VERSION "dbc-export 1 2025.20.8"

NS_ :

BS_:

BU_: ADSP APB APP APS BB BMS CC CP DAS DI DIF DIR EPAS3P EPAS3S EPBL EPBR GTW HVP ICR IDB PCS PM TCU UI UIS VC VCFRONT VCLEFT VCRIGHT VCSEC

BO_ 322 VCLEFT_liftgateStatus: 8 VCLEFT
 SG_ VCLEFT_liftgateStatusIndex M : 0|2@1+ (1,0) [0|3] "" Vector__XXX
 SG_ VCLEFT_liftgateState m0 : 3|4@1+ (1,0) [0|15] "" Vector__XXX
 SG_ VCLEFT_liftgateStoppingCondition m0 : 10|4@1+ (1,0) [0|15] "" Vector__XXX
 SG_ VCLEFT_liftgateMvmntNotAllowedCo m0 : 14|3@1+ (1,0) [0|7] "" Vector__XXX
 SG_ VCLEFT_liftgatePositionCalibrate m0 : 17|1@1+ (1,0) [0|1] "" Vector__XXX
 SG_ VCLEFT_liftgateUIChimeRequest m0 : 18|3@1+ (1,0) [0|7] "" Vector__XXX
 SG_ VCLEFT_liftgatePhysicalChimeRequ m0 : 21|3@1+ (1,0) [0|7] "" Vector__XXX
 SG_ VCLEFT_liftgateEstimatedStrutTem m0 : 24|8@1+ (1,-60) [-60|195] "C" Vector__XXX
 SG_ VCLEFT_liftgateStaticStrutMode m0 : 32|3@1+ (1,0) [1|7] "" Vector__XXX
 SG_ VCLEFT_liftgateRequestSource m0 : 35|4@1+ (1,0) [0|15] "" Vector__XXX
 SG_ VCLEFT_liftgateNewHeightNudge m0 : 39|1@1+ (1,0) [0|1] "" Vector__XXX
 SG_ VCLEFT_liftgateNewSaveHeight m0 : 40|8@1+ (1,0) [0|255] "cm" Vector__XXX
 SG_ VCLEFT_liftgateGeofenceState m0 : 48|2@1+ (1,0) [0|3] "" Vector__XXX
 SG_ VCLEFT_liftgateAboveCrossoverAng m0 : 59|1@1+ (1,0) [0|1] "" Vector__XXX
 SG_ VCLEFT_liftgateLatchRequest m0 : 61|3@1+ (1,0) [0|7] "" Vector__XXX
 SG_ VCLEFT_liftgateStrutDutyCycle m1 : 3|8@1- (1,0) [-100|100] "%" Vector__XXX
 SG_ VCLEFT_liftgateStrutCurrent m1 : 11|10@1- (0.1,0) [-30|30] "A" Vector__XXX
 SG_ VCLEFT_liftgatePosition m1 : 21|7@1- (1,46) [-5|95] "deg" Vector__XXX
 SG_ VCLEFT_liftgateSpeed m1 : 28|10@1- (0.1,0) [-30|30] "deg/s" Vector__XXX
 SG_ VCLEFT_liftgateHeight m1 : 38|8@1+ (1,0) [0|255] "cm" Vector__XXX
 SG_ VCLEFT_liftgatePositionDiff m1 : 46|6@1- (1,0) [-30|30] "deg" Vector__XXX

BO_ 994 VCLEFT_lightStatus: 7 VCLEFT
 SG_ VCLEFT_brakeLightStatus : 0|2@1+ (1,0) [0|2] "" Vector__XXX
 SG_ VCLEFT_tailLightStatus : 2|2@1+ (1,0) [0|2] "" Vector__XXX
 SG_ VCLEFT_turnSignalStatus : 4|2@1+ (1,0) [0|2] "" Vector__XXX
 SG_ VCLEFT_FLMapLightStatus : 6|2@1+ (1,0) [0|2] "" Vector__XXX
 SG_ VCLEFT_FRMapLightStatus : 8|2@1+ (1,0) [0|2] "" Vector__XXX
 SG_ VCLEFT_RLMapLightStatus : 10|2@1+ (1,0) [0|2] "" Vector__XXX
 SG_ VCLEFT_RRMapLightStatus : 12|2@1+ (1,0) [0|2] "" Vector__XXX
 SG_ VCLEFT_FLMapLightSwitchPressed : 14|1@1+ (1,0) [0|1] "" Vector__XXX
 SG_ VCLEFT_FRMapLightSwitchPressed : 15|1@1+ (1,0) [0|1] "" Vector__XXX
 SG_ VCLEFT_RLMapLightSwitchPressed : 16|1@1+ (1,0) [0|1] "" Vector__XXX
 SG_ VCLEFT_RRMapLightSwitchPressed : 17|1@1+ (1,0) [0|1] "" Vector__XXX
 SG_ VCLEFT_leftTurnTrailerLightStatu : 18|2@1+ (1,0) [0|2] "" Vector__XXX
 SG_ VCLEFT_rightTrnTrailerLightStatu : 20|2@1+ (1,0) [0|2] "" Vector__XXX
 SG_ VCLEFT_brakeTrailerLightStatus : 22|2@1+ (1,0) [0|2] "" Vector__XXX
 SG_ VCLEFT_tailTrailerLightStatus : 24|2@1+ (1,0) [0|2] "" Vector__XXX
 SG_ VCLEFT_fogTrailerLightStatus : 26|2@1+ (1,0) [0|2] "" Vector__XXX
 SG_ VCLEFT_frontRideHeight : 28|8@1- (1,0) [-127|127] "mm" Vector__XXX
 SG_ VCLEFT_rearRideHeight : 36|8@1- (1,0) [-127|127] "mm" Vector__XXX
 SG_ VCLEFT_trailerDetected : 46|2@1+ (1,0) [1|3] "" Vector__XXX
 SG_ VCLEFT_rideHeightSensorFault : 48|1@1+ (1,0) [0|1] "" Vector__XXX
 SG_ VCLEFT_reverseTrailerLightStatus : 49|2@1+ (1,0) [0|2] "" Vector__XXX
 SG_ VCLEFT_tailLightOutageStatus : 51|1@1+ (1,0) [0|1] "" Vector__XXX
 SG_ VCLEFT_reverseLightStatus : 52|2@1+ (1,0) [0|2] "" Vector__XXX

BO_ 1802 VCLEFT_logging0point1Hz: 6 VCLEFT
 SG_ VCLEFT_logging0point1HzIndex M : 0|1@1+ (1,0) [0|1] "" Vector__XXX
 SG_ VCLEFT_leftBrakeTailLightCurrent m0 : 2|9@1+ (0.005,0) [0|2.55] "A" Vector__XXX
 SG_ VCLEFT_leftBrakeTailLightCu_0001 m0 : 11|3@1+ (1,0) [1|7] "" Vector__XXX
 SG_ VCLEFT_leftRearTurnLightCurrent m0 : 14|9@1+ (0.002,0) [0|1.02] "A" Vector__XXX
 SG_ VCLEFT_leftRearTurnLightCurrentS m0 : 24|3@1+ (1,0) [1|7] "" Vector__XXX

BO_ 936 VCLEFT_logging1Hz: 8 VCLEFT
 SG_ VCLEFT_logging1HzIndex M : 0|2@1+ (1,0) [0|3] "" Vector__XXX
 SG_ VCLEFT_tohcPCBATemperature m0 : 8|8@1+ (1,-40) [-40|214] "degC" Vector__XXX
 SG_ VCLEFT_phoneChargingFL m0 : 16|1@1+ (1,0) [0|1] "" Vector__XXX
 SG_ VCLEFT_phoneChargingFR m0 : 17|1@1+ (1,0) [0|1] "" Vector__XXX
 SG_ VCLEFT_swcResistance m0 : 24|7@1+ (0.025,0) [0|3.15] "Ohm" Vector__XXX
 SG_ VCLEFT_frontSeatHeatCushionPwr m0 : 32|7@1+ (1,0) [0|127] "W" Vector__XXX
 SG_ VCLEFT_frontSeatHeatBackrestPwr m0 : 40|7@1+ (1,0) [0|127] "W" Vector__XXX

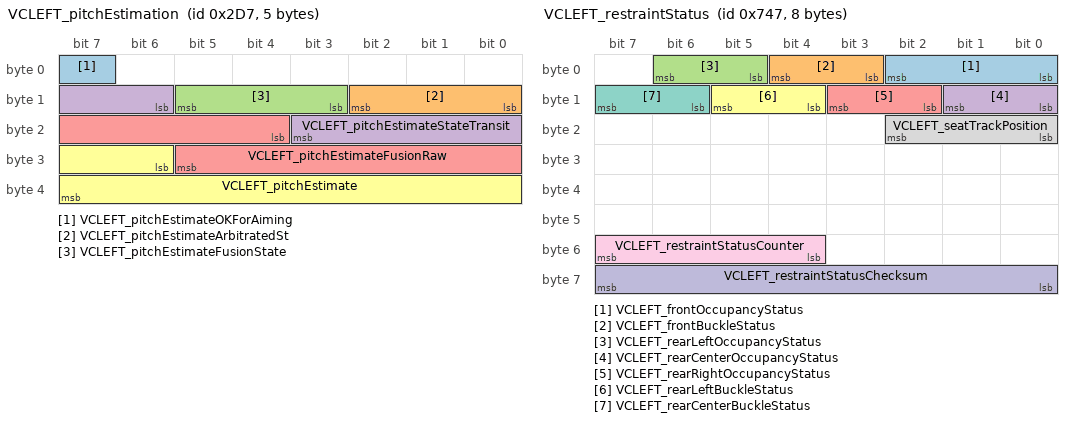
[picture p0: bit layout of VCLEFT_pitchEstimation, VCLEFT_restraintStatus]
BO_ 727 VCLEFT_pitchEstimation: 5 VCLEFT
 SG_ VCLEFT_pitchEstimateOKForAiming : 7|1@1+ (1,0) [0|1] "" Vector__XXX
 SG_ VCLEFT_pitchEstimateArbitratedSt : 8|3@1+ (1,0) [0|7] "" Vector__XXX
 SG_ VCLEFT_pitchEstimateFusionState : 11|3@1+ (1,0) [0|7] "" Vector__XXX
 SG_ VCLEFT_pitchEstimateStateTransit : 14|6@1+ (1,0) [0|63] "" Vector__XXX
 SG_ VCLEFT_pitchEstimateFusionRaw : 20|10@1- (0.0002,0) [-0.1024|0.1022] "rad" Vector__XXX
 SG_ VCLEFT_pitchEstimate : 30|10@1- (0.0002,0) [-0.1022|0.1022] "rad" Vector__XXX

BO_ 1863 VCLEFT_restraintStatus: 8 VCLEFT
 SG_ VCLEFT_frontOccupancyStatus : 0|3@1+ (1,0) [0|6] "" Vector__XXX
 SG_ VCLEFT_frontBuckleStatus : 3|2@1+ (1,0) [0|2] "" Vector__XXX
 SG_ VCLEFT_rearLeftOccupancyStatus : 5|2@1+ (1,0) [0|2] "" Vector__XXX
 SG_ VCLEFT_rearCenterOccupancyStatus : 8|2@1+ (1,0) [0|2] "" Vector__XXX
 SG_ VCLEFT_rearRightOccupancyStatus : 10|2@1+ (1,0) [0|2] "" Vector__XXX
 SG_ VCLEFT_rearLeftBuckleStatus : 12|2@1+ (1,0) [0|2] "" Vector__XXX
 SG_ VCLEFT_rearCenterBuckleStatus : 14|2@1+ (1,0) [0|2] "" Vector__XXX
 SG_ VCLEFT_seatTrackPosition : 16|3@1+ (1,0) [0|6] "" Vector__XXX
 SG_ VCLEFT_restraintStatusCounter : 52|4@1+ (1,0) [0|15] "" Vector__XXX
 SG_ VCLEFT_restraintStatusChecksum : 56|8@1+ (1,0) [0|255] "" Vector__XXX

BO_ 1250 VCLEFT_seatStatus: 8 VCLEFT
 SG_ VCLEFT_seatStatusIndex M : 0|3@1+ (1,0) [0|7] "" Vector__XXX
 SG_ VCLEFT_frontSeatTrackPos m0 : 8|16@1- (1,0) [-32768|32767] "" Vector__XXX
 SG_ VCLEFT_frontSeatTrackCurrent m0 : 24|12@1- (0.01,0) [-20.48|20.47] "A" Vector__XXX
 SG_ VCLEFT_frontSeatTrackDuty m0 : 36|12@1- (0.1,0) [-204.8|204.7] "%" Vector__XXX
 SG_ VCLEFT_frontSeatTrackState m0 : 48|3@1+ (1,0) [0|7] "" Vector__XXX
 SG_ VCLEFT_frontSeatTrackCalibrated m0 : 51|1@1+ (1,0) [0|1] "" Vector__XXX
 SG_ VCLEFT_frontSeatTrackLog m0 : 52|1@1+ (1,0) [0|1] "" Vector__XXX
 SG_ VCLEFT_frontSeatTrackBridgeSt m0 : 53|2@1+ (1,0) [0|3] "" Vector__XXX
 SG_ VCLEFT_frontSeatBackPos m1 : 8|16@1- (1,0) [-32768|32767] "" Vector__XXX
 SG_ VCLEFT_frontSeatBackCurrent m1 : 24|12@1- (0.01,0) [-20.48|20.47] "A" Vector__XXX
 SG_ VCLEFT_frontSeatBackDuty m1 : 36|12@1- (0.1,0) [-204.8|204.7] "%" Vector__XXX
 SG_ VCLEFT_frontSeatBackState m1 : 48|3@1+ (1,0) [0|7] "" Vector__XXX
 SG_ VCLEFT_frontSeatBackCalibrated m1 : 51|1@1+ (1,0) [0|1] "" Vector__XXX
 SG_ VCLEFT_frontSeatBackLog m1 : 52|1@1+ (1,0) [0|1] "" Vector__XXX
 SG_ VCLEFT_frontSeatBackBridgeSt m1 : 53|2@1+ (1,0) [0|3] "" Vector__XXX
 SG_ VCLEFT_frontSeatLiftPos m2 : 8|16@1- (1,0) [-32768|32767] "" Vector__XXX
 SG_ VCLEFT_frontSeatLiftCurrent m2 : 24|12@1- (0.01,0) [-20.48|20.47] "A" Vector__XXX
 SG_ VCLEFT_frontSeatLiftDuty m2 : 36|12@1- (0.1,0) [-204.8|204.7] "%" Vector__XXX
 SG_ VCLEFT_frontSeatLiftState m2 : 48|3@1+ (1,0) [0|7] "" Vector__XXX
 SG_ VCLEFT_frontSeatLiftCalibrated m2 : 51|1@1+ (1,0) [0|1] "" Vector__XXX
 SG_ VCLEFT_frontSeatLiftLog m2 : 52|1@1+ (1,0) [0|1] "" Vector__XXX
 SG_ VCLEFT_frontSeatLiftBridgeSt m2 : 53|2@1+ (1,0) [0|3] "" Vector__XXX
 SG_ VCLEFT_frontSeatTiltPos m3 : 8|16@1- (1,0) [-32768|32767] "" Vector__XXX
 SG_ VCLEFT_frontSeatTiltCurrent m3 : 24|12@1- (0.01,0) [-20.48|20.47] "A" Vector__XXX
 SG_ VCLEFT_frontSeatTiltDuty m3 : 36|12@1- (0.1,0) [-204.8|204.7] "%" Vector__XXX
 SG_ VCLEFT_frontSeatTiltState m3 : 48|3@1+ (1,0) [0|7] "" Vector__XXX
 SG_ VCLEFT_frontSeatTiltCalibrated m3 : 51|1@1+ (1,0) [0|1] "" Vector__XXX
 SG_ VCLEFT_frontSeatTiltLog m3 : 52|1@1+ (1,0) [0|1] "" Vector__XXX
 SG_ VCLEFT_frontSeatTiltBridgeSt m3 : 53|2@1+ (1,0) [0|3] "" Vector__XXX
 SG_ VCLEFT_lumbarAState m4 : 3|3@1+ (1,0) [0|7] "" Vector__XXX
 SG_ VCLEFT_lumbarBState m4 : 6|3@1+ (1,0) [0|7] "" Vector__XXX
 SG_ VCLEFT_lumbarAPressureHpa m4 : 9|12@1+ (1,0) [0|4095] "" Vector__XXX
 SG_ VCLEFT_lumbarAPressureHpaFilt m4 : 21|10@1+ (1,0) [0|1023] "" Vector__XXX
 SG_ VCLEFT_lumbarBPressureHpa m4 : 31|12@1+ (1,0) [0|4095] "" Vector__XXX
 SG_ VCLEFT_lumbarBPressureHpaFilt m4 : 43|10@1+ (1,0) [0|1023] "" Vector__XXX
 SG_ VCLEFT_lumbarActiveTooLongErr m4 : 53|1@1+ (1,0) [0|1] "" Vector__XXX
 SG_ VCLEFT_lumbarMaxPErr m4 : 54|1@1+ (1,0) [0|1] "" Vector__XXX
 SG_ VCLEFT_lumbarOvercurrentErr m4 : 55|1@1+ (1,0) [0|1] "" Vector__XXX
 SG_ VCLEFT_lumbarMaxOperatingPErr m4 : 56|1@1+ (1,0) [0|1] "" Vector__XXX
 SG_ VCLEFT_lumbarMinPErr m4 : 57|1@1+ (1,0) [0|1] "" Vector__XXX
 SG_ VCLEFT_lumbarGeneralErr m4 : 58|1@1+ (1,0) [0|1] "" Vector__XXX
 SG_ VCLEFT_lumbarDevMaxPumpPressA m4 : 59|1@1+ (1,0) [0|1] "" Vector__XXX
 SG_ VCLEFT_lumbarDevMaxPumpPressB m4 : 60|1@1+ (1,0) [0|1] "" Vector__XXX
 SG_ VCLEFT_frontSeatTrackPosReal m5 : 3|12@1- (1,0) [-2048|2047] "mm" Vector__XXX
 SG_ VCLEFT_frontSeatBackPosReal m5 : 16|12@1- (0.1,0) [-204.8|204.7] "deg" Vector__XXX
 SG_ VCLEFT_frontSeatLiftPosReal m5 : 28|12@1- (1,0) [-2048|2047] "mm" Vector__XXX
 SG_ VCLEFT_frontSeatTiltPosReal m5 : 40|12@1- (0.1,0) [-204.8|204.7] "deg" Vector__XXX
 SG_ VCLEFT_frontSeatTrackPosOffset m6 : 3|12@1- (1,0) [-2048|2047] "mm" Vector__XXX
 SG_ VCLEFT_frontSeatBackPosOffset m6 : 16|12@1- (0.1,0) [-204.8|204.7] "deg" Vector__XXX
 SG_ VCLEFT_frontSeatLiftPosOffset m6 : 28|12@1- (1,0) [-2048|2047] "mm" Vector__XXX
 SG_ VCLEFT_frontSeatTiltPosOffset m6 : 40|12@1- (0.1,0) [-204.8|204.7] "deg" Vector__XXX

BO_ 738 VCLEFT_seatStatus2: 8 VCLEFT
 SG_ VCLEFT_seatStatus2Index M : 0|4@1+ (1,0) [0|15] "" Vector__XXX
 SG_ VCLEFT_frontSeatHeatCurrent m0 : 4|12@1+ (0.01,0) [0|40.95] "A" Vector__XXX
 SG_ VCLEFT_frontSeatHeatDuty m0 : 16|8@1+ (1,0) [0|255] "%" Vector__XXX
 SG_ VCLEFT_frontSeatHeatTmp m0 : 24|12@1- (0.05,0) [-40|80] "degC" Vector__XXX
 SG_ VCLEFT_frontSeatHeatTmpTarget m0 : 36|8@1- (0.5,0) [0|60] "degC" Vector__XXX
 SG_ VCLEFT_frontSeatHeatInhibited m0 : 44|1@1+ (1,0) [0|1] "" Vector__XXX
 SG_ VCLEFT_frontSeatHeatPowered m0 : 45|1@1+ (1,0) [0|1] "" Vector__XXX
 SG_ VCLEFT_2RowSeatReclineState m11 : 4|4@1+ (1,0) [0|14] "" Vector__XXX
 SG_ VCLEFT_2RowSeatReclineDuty m11 : 8|8@1- (1,0) [-100|100] "%" Vector__XXX
 SG_ VCLEFT_2RowSeatReclineCurrent m11 : 16|12@1- (0.05,0) [-100|100] "A" Vector__XXX
 SG_ VCLEFT_2RowSeatReclineCalibrated m11 : 28|1@1+ (1,0) [0|1] "" Vector__XXX
 SG_ VCLEFT_2RowSeatReclinePositionRa m11 : 29|12@1- (1,0) [-2048|2047] "" Vector__XXX
 SG_ VCLEFT_2RowSeatReclineAngle m11 : 41|12@1- (0.1,0) [-204.8|204.7] "deg" Vector__XXX
 SG_ VCLEFT_2RowSeatReclineAbsPosSwit m11 : 53|2@1+ (1,0) [1|3] "" Vector__XXX
 SG_ VCLEFT_2RowSeatReclinePositionSt m12 : 4|3@1+ (1,0) [0|7] "" Vector__XXX
 SG_ VCLEFT_2RowSeatReclineAdjustment m12 : 7|1@1+ (1,0) [0|1] "" Vector__XXX
 SG_ VCLEFT_2RowSeatReclineFoldAllowe m12 : 8|1@1+ (1,0) [0|1] "" Vector__XXX
 SG_ VCLEFT_2RowSeatReclineUnfoldAllo m12 : 9|1@1+ (1,0) [0|1] "" Vector__XXX
 SG_ VCLEFT_2RowSeatReclineNextToggle m12 : 10|2@1+ (1,0) [0|3] "" Vector__XXX
 SG_ VCLEFT_2RowSeatReclineChoreoBloc m12 : 12|1@1+ (1,0) [0|1] "" Vector__XXX
 SG_ VCLEFT_2RowSeat1RClashAvoidanceB m12 : 13|3@1+ (1,0) [0|7] "" Vector__XXX
 SG_ VCLEFT_2RowSeat1RClashAvoidanceS m12 : 16|2@1+ (1,0) [0|3] "" Vector__XXX
 SG_ VCLEFT_2RowSeatReclineAbsPo_0001 m12 : 18|12@1- (0.1,0) [-204.8|204.7] "deg" Vector__XXX

BO_ 930 VCLEFT_status: 8 VCLEFT
 SG_ VCLEFT_statusIndex M : 0|2@1+ (1,0) [0|3] "" Vector__XXX
 SG_ VCLEFT_securityControllerEnable m0 : 5|1@1+ (1,0) [0|1] "" Vector__XXX
 SG_ VCLEFT_securityControllerVoltage m0 : 6|5@1+ (0.625,0) [0|19.375] "V" Vector__XXX
 SG_ VCLEFT_consoleDoorAssist m0 : 11|1@1+ (1,0) [0|1] "" Vector__XXX
 SG_ VCLEFT_OTAState m0 : 12|1@1+ (1,0) [0|1] "" Vector__XXX
 SG_ VCLEFT_5AVoltage m0 : 13|10@1+ (0.005443676,0) [0|5.568880548] "V" Vector__XXX
 SG_ VCLEFT_vbatProt m0 : 23|12@1+ (0.005443676,0) [0|22.29185322] "V" Vector__XXX
 SG_ VCLEFT_footwellLightCurrent m0 : 35|12@1- (0.1,0) [-204.8|204.7] "mA" Vector__XXX
 SG_ VCLEFT_swcInputVoltage m0 : 47|8@1+ (0.1,0) [0|25.4] "V" Vector__XXX
 SG_ VCLEFT_swcPCBATemperature m0 : 55|8@1- (1,68) [-59|195] "degC" Vector__XXX
 SG_ VCLEFT_obdEthernetActive m0 : 63|1@1+ (1,0) [0|1] "" Vector__XXX
 SG_ VCLEFT_rationalityAggregateCurre m1 : 12|8@1+ (0.5,0) [0|127.5] "A" Vector__XXX
 SG_ VCLEFT_LVBatteryTypeDBG m1 : 20|3@1+ (1,0) [0|7] "" Vector__XXX
 SG_ VCLEFT_DIeFuseFault m1 : 24|1@1+ (1,0) [0|1] "" Vector__XXX
 SG_ VCLEFT_eFuseMgmtVoltageMonitor m1 : 25|7@1+ (0.125,0) [0|15.875] "V" Vector__XXX
 SG_ VCLEFT_trailerAuxCurrent m1 : 32|12@1+ (0.025,0) [0|102.35] "A" Vector__XXX
 SG_ VCLEFT_swcHeatTmp m1 : 44|10@1+ (0.1,-35) [-35|65] "degC" Vector__XXX
 SG_ VCLEFT_swcHeatStatus m1 : 54|3@1+ (1,0) [1|7] "" Vector__XXX
 SG_ VCLEFT_swcHeatInhibited m1 : 57|1@1+ (1,0) [0|1] "" Vector__XXX
 SG_ VCLEFT_pcbaTemperature m2 : 4|11@1+ (0.125,-40) [-40|150] "degC" Vector__XXX
 SG_ VCLEFT_swcHeatPwr m2 : 15|9@1+ (0.5,0) [0|254] "W" Vector__XXX
 SG_ VCLEFT_swcHeatDutyCycle m2 : 24|7@1+ (1,0) [0|100] "%" Vector__XXX
 SG_ VCLEFT_DIeFuseCurrent m2 : 31|6@1+ (0.1,0) [0|6.3] "A" Vector__XXX
 SG_ VCLEFT_SWCpresent m2 : 37|1@1+ (1,0) [0|1] "" Vector__XXX

BO_ 962 VCLEFT_switchStatus: 8 VCLEFT
 SG_ VCLEFT_switchStatusIndex M : 0|1@1+ (1,0) [0|1] "" Vector__XXX
 SG_ VCLEFT_hornSwitchPressed m0 : 2|1@1+ (1,0) [0|1] "" Vector__XXX
 SG_ VCLEFT_hazardButtonPressed m0 : 3|1@1+ (1,0) [0|1] "" Vector__XXX
 SG_ VCLEFT_brakeSwitchPressed m0 : 4|1@1+ (1,0) [0|1] "" Vector__XXX
 SG_ VCLEFT_rightMirrorTilt m0 : 5|3@1+ (1,0) [0|7] "" Vector__XXX
 SG_ VCLEFT_frontSeatTrackBack m0 : 8|2@1+ (1,0) [1|3] "" Vector__XXX
 SG_ VCLEFT_frontSeatTrackForward m0 : 10|2@1+ (1,0) [1|3] "" Vector__XXX
 SG_ VCLEFT_frontSeatTiltDown m0 : 12|2@1+ (1,0) [1|3] "" Vector__XXX
 SG_ VCLEFT_frontSeatTiltUp m0 : 14|2@1+ (1,0) [1|3] "" Vector__XXX
 SG_ VCLEFT_frontSeatLiftDown m0 : 16|2@1+ (1,0) [1|3] "" Vector__XXX
 SG_ VCLEFT_frontSeatLiftUp m0 : 18|2@1+ (1,0) [1|3] "" Vector__XXX
 SG_ VCLEFT_frontSeatBackrestBack m0 : 20|2@1+ (1,0) [1|3] "" Vector__XXX
 SG_ VCLEFT_frontSeatBackrestForward m0 : 22|2@1+ (1,0) [1|3] "" Vector__XXX
 SG_ VCLEFT_frontSeatLumbarDown m0 : 24|2@1+ (1,0) [1|3] "" Vector__XXX
 SG_ VCLEFT_frontSeatLumbarUp m0 : 26|2@1+ (1,0) [1|3] "" Vector__XXX
 SG_ VCLEFT_frontSeatLumbarIn m0 : 28|2@1+ (1,0) [1|3] "" Vector__XXX
 SG_ VCLEFT_frontSeatLumbarOut m0 : 30|2@1+ (1,0) [1|3] "" Vector__XXX
 SG_ VCLEFT_btnWindowSwPackUpLF m0 : 32|1@1+ (1,0) [0|1] "" Vector__XXX
 SG_ VCLEFT_btnWindowSwPackAutoUpLF m0 : 33|1@1+ (1,0) [0|1] "" Vector__XXX
 SG_ VCLEFT_btnWindowSwPackDownLF m0 : 34|1@1+ (1,0) [0|1] "" Vector__XXX
 SG_ VCLEFT_btnWindowSwPackAutoDownLF m0 : 35|1@1+ (1,0) [0|1] "" Vector__XXX
 SG_ VCLEFT_btnWindowSwPackUpLR m0 : 36|1@1+ (1,0) [0|1] "" Vector__XXX
 SG_ VCLEFT_btnWindowSwPackAutoUpLR m0 : 37|1@1+ (1,0) [0|1] "" Vector__XXX
 SG_ VCLEFT_btnWindowSwPackDownLR m0 : 38|1@1+ (1,0) [0|1] "" Vector__XXX
 SG_ VCLEFT_btnWindowSwPackAutoDownLR m0 : 39|1@1+ (1,0) [0|1] "" Vector__XXX
 SG_ VCLEFT_btnWindowSwPackUpRF m0 : 40|1@1+ (1,0) [0|1] "" Vector__XXX
 SG_ VCLEFT_btnWindowSwPackAutoUpRF m0 : 41|1@1+ (1,0) [0|1] "" Vector__XXX
 SG_ VCLEFT_btnWindowSwPackDownRF m0 : 42|1@1+ (1,0) [0|1] "" Vector__XXX
 SG_ VCLEFT_btnWindowSwPackAutoDownRF m0 : 43|1@1+ (1,0) [0|1] "" Vector__XXX
 SG_ VCLEFT_btnWindowSwPackUpRR m0 : 44|1@1+ (1,0) [0|1] "" Vector__XXX
 SG_ VCLEFT_btnWindowSwPackAutoUpRR m0 : 45|1@1+ (1,0) [0|1] "" Vector__XXX
 SG_ VCLEFT_btnWindowSwPackDownRR m0 : 46|1@1+ (1,0) [0|1] "" Vector__XXX
 SG_ VCLEFT_btnWindowSwPackAutoDownRR m0 : 47|1@1+ (1,0) [0|1] "" Vector__XXX
 SG_ VCLEFT_frontBuckleSwitch m0 : 48|2@1+ (1,0) [1|3] "" Vector__XXX
 SG_ VCLEFT_frontOccupancySwitch m0 : 50|2@1+ (1,0) [1|3] "" Vector__XXX
 SG_ VCLEFT_rearLeftBuckleSwitch m0 : 52|2@1+ (1,0) [1|3] "" Vector__XXX
 SG_ VCLEFT_rearCenterOccupancySwitch m0 : 54|2@1+ (1,0) [1|3] "" Vector__XXX
 SG_ VCLEFT_rearLeftOccupancySwitch m0 : 56|2@1+ (1,0) [1|3] "" Vector__XXX
 SG_ VCLEFT_rearRightOccupancySwitch m0 : 58|2@1+ (1,0) [1|3] "" Vector__XXX
 SG_ VCLEFT_brakePressed m0 : 60|1@1+ (1,0) [0|1] "" Vector__XXX
 SG_ VCLEFT_rearHVACButtonPressed m0 : 61|1@1+ (1,0) [0|1] "" Vector__XXX
 SG_ VCLEFT_rearCenterBuckleSwitch m0 : 62|2@1+ (1,0) [1|3] "" Vector__XXX
 SG_ VCLEFT_isAlcoholInterlockSet m1 : 2|1@1+ (1,0) [0|1] "" Vector__XXX
 SG_ VCLEFT_swcLeftTiltRight m1 : 3|2@1+ (1,0) [1|3] "" Vector__XXX
 SG_ VCLEFT_swcLeftPressed m1 : 5|2@1+ (1,0) [1|3] "" Vector__XXX
 SG_ VCLEFT_swcRightTiltLeft m1 : 8|2@1+ (1,0) [1|3] "" Vector__XXX
 SG_ VCLEFT_swcRightTiltRight m1 : 10|2@1+ (1,0) [1|3] "" Vector__XXX
 SG_ VCLEFT_swcRightPressed m1 : 12|2@1+ (1,0) [1|3] "" Vector__XXX
 SG_ VCLEFT_swcLeftTiltLeft m1 : 14|2@1+ (1,0) [1|3] "" Vector__XXX
 SG_ VCLEFT_swcLeftScrollTicks m1 : 16|6@1- (1,0) [-32|31] "" Vector__XXX
 SG_ VCLEFT_swcWiperButtonState m1 : 22|2@1+ (1,0) [0|3] "" Vector__XXX
 SG_ VCLEFT_swcRightScrollTicks m1 : 24|6@1- (1,0) [-32|31] "" Vector__XXX
 SG_ VCLEFT_swcTurnSignalLeftButtonSt m1 : 30|2@1+ (1,0) [0|3] "" Vector__XXX
 SG_ VCLEFT_btnWindowUpLR m1 : 32|1@1+ (1,0) [0|1] "" Vector__XXX
 SG_ VCLEFT_btnWindowAutoUpLR m1 : 33|1@1+ (1,0) [0|1] "" Vector__XXX
 SG_ VCLEFT_btnWindowDownLR m1 : 34|1@1+ (1,0) [0|1] "" Vector__XXX
 SG_ VCLEFT_btnWindowAutoDownLR m1 : 35|1@1+ (1,0) [0|1] "" Vector__XXX
 SG_ VCLEFT_2RowSeatLeftFoldFlatSwitc m1 : 38|1@1+ (1,0) [0|1] "" Vector__XXX
 SG_ VCLEFT_2RowSeatRightFoldFlatSwit m1 : 39|1@1+ (1,0) [0|1] "" Vector__XXX
 SG_ VCLEFT_2RowSeatBothFoldFlatSwitc m1 : 40|1@1+ (1,0) [0|1] "" Vector__XXX
 SG_ VCLEFT_swcLeftDoublePress m1 : 41|1@1+ (1,0) [0|1] "" Vector__XXX
 SG_ VCLEFT_swcRightDoublePress m1 : 42|1@1+ (1,0) [0|1] "" Vector__XXX
 SG_ VCLEFT_swcTurnSignalRightButtonS m1 : 44|2@1+ (1,0) [0|3] "" Vector__XXX
 SG_ VCLEFT_swcHighBeamButtonState m1 : 46|2@1+ (1,0) [0|3] "" Vector__XXX
 SG_ VCLEFT_swcVoiceControlPress m1 : 48|2@1+ (1,0) [1|3] "" Vector__XXX
 SG_ VCLEFT_swcCameraButtonState m1 : 50|2@1+ (1,0) [0|3] "" Vector__XXX
 SG_ VCLEFT_swcRightPressedQF m1 : 52|1@1+ (1,0) [0|1] "" Vector__XXX
 SG_ VCLEFT_frontSeatResistiveOccupan m1 : 62|2@1+ (1,0) [1|3] "" Vector__XXX

BO_ 656 VCLEFT_thermalLogging10Hz: 8 VCLEFT
 SG_ VCLEFT_thermalLogging10HzIndex M : 0|3@1+ (1,0) [0|7] "" Vector__XXX
 SG_ VCLEFT_hvac2RLeftLateralVoltage m2 : 8|8@1+ (0.02,0) [0|5] "V" Vector__XXX
 SG_ VCLEFT_hvac2RLeftVerticalVoltage m2 : 16|8@1+ (0.02,0) [0|5] "V" Vector__XXX
 SG_ VCLEFT_hvac2RRightLateralVoltage m2 : 24|8@1+ (0.02,0) [0|5] "V" Vector__XXX
 SG_ VCLEFT_hvac2RRightVerticalVoltag m2 : 32|8@1+ (0.02,0) [0|5] "V" Vector__XXX
 SG_ VCLEFT_hvac2RLeftLateralCalibrat m2 : 40|1@1+ (1,0) [0|1] "" Vector__XXX
 SG_ VCLEFT_hvac2RLeftVerticalCalibra m2 : 41|1@1+ (1,0) [0|1] "" Vector__XXX
 SG_ VCLEFT_hvac2RRightLateralCalibra m2 : 42|1@1+ (1,0) [0|1] "" Vector__XXX
 SG_ VCLEFT_hvac2RRightVerticalCalibr m2 : 43|1@1+ (1,0) [0|1] "" Vector__XXX
 SG_ VCLEFT_hvac2RLeftLateralState m2 : 44|4@1+ (1,0) [0|15] "" Vector__XXX
 SG_ VCLEFT_hvac2RLeftVerticalState m2 : 48|4@1+ (1,0) [0|15] "" Vector__XXX
 SG_ VCLEFT_hvac2RRightLateralState m2 : 52|4@1+ (1,0) [0|15] "" Vector__XXX
 SG_ VCLEFT_hvac2RRightVerticalState m2 : 56|4@1+ (1,0) [0|15] "" Vector__XXX
 SG_ VCLEFT_hvacBlowerWindmillElecRpm m3 : 8|14@1+ (1,0) [0|16383] "RPM" Vector__XXX
 SG_ VCLEFT_hvac2RRightVerticalVeloci m3 : 24|8@1- (1,0) [-100|100] "deg/s" Vector__XXX
 SG_ VCLEFT_hvacBlowerWindmillBemf m3 : 32|14@1+ (4,0) [0|65532] "mV" Vector__XXX
 SG_ VCLEFT_hvac2RLeftVerticalVelocit m3 : 46|8@1- (1,0) [-100|100] "deg/s" Vector__XXX
 SG_ VCLEFT_hvac2RLeftLateralVelocity m3 : 54|8@1- (1,0) [-100|100] "deg/s" Vector__XXX
 SG_ VCLEFT_vcusbLinSchedule m3 : 62|2@1+ (1,0) [0|3] "" Vector__XXX
 SG_ VCLEFT_hvac2RLeftLateralDuty m4 : 3|8@1- (1,0) [-100|100] "%" Vector__XXX
 SG_ VCLEFT_hvac2RLeftVerticalDuty m4 : 11|8@1- (1,0) [-100|100] "%" Vector__XXX
 SG_ VCLEFT_hvac2RRightLateralDuty m4 : 19|8@1- (1,0) [-100|100] "%" Vector__XXX
 SG_ VCLEFT_hvac2RRightVerticalDuty m4 : 27|8@1- (1,0) [-100|100] "%" Vector__XXX
 SG_ VCLEFT_hvacBlowerWindmilling m4 : 35|1@1+ (1,0) [0|1] "" Vector__XXX
 SG_ VCLEFT_hvac2RRightLateralVelocit m4 : 36|8@1- (1,0) [-100|100] "deg/s" Vector__XXX
 SG_ VCLEFT_hvacBlower1msOverrunFrequ m4 : 44|10@1+ (1,0) [0|1023] "" Vector__XXX
 SG_ VCLEFT_hvacBlower10msOverrunFreq m4 : 54|7@1+ (1,0) [0|127] "" Vector__XXX

BO_ 657 VCLEFT_thermalLogging1Hz: 8 VCLEFT
 SG_ VCLEFT_thermalLogging1HzIndex M : 0|4@1+ (1,0) [0|15] "" Vector__XXX
 SG_ VCLEFT_hvac2RLeftLateralZeroStop m0 : 8|8@1+ (0.02,0) [0|5] "V" Vector__XXX
 SG_ VCLEFT_hvac2RLeftVerticalZeroSto m0 : 16|8@1+ (0.02,0) [0|5] "V" Vector__XXX
 SG_ VCLEFT_hvac2RRightLateralZeroSto m0 : 24|8@1+ (0.02,0) [0|5] "V" Vector__XXX
 SG_ VCLEFT_hvac2RRightVerticalZeroSt m0 : 32|8@1+ (0.02,0) [0|5] "V" Vector__XXX
 SG_ VCLEFT_hvac2RLeftLateralEndStopV m1 : 8|8@1+ (0.02,0) [0|5] "V" Vector__XXX
 SG_ VCLEFT_hvac2RLeftVerticalEndStop m1 : 16|8@1+ (0.02,0) [0|5] "V" Vector__XXX
 SG_ VCLEFT_hvac2RRightLateralEndStop m1 : 24|8@1+ (0.02,0) [0|5] "V" Vector__XXX
 SG_ VCLEFT_hvac2RRightVerticalEndSto m1 : 32|8@1+ (0.02,0) [0|5] "V" Vector__XXX
 SG_ VCLEFT_hvacBlowerArbState m1 : 40|3@1+ (1,0) [0|7] "" Vector__XXX
 SG_ VCLEFT_hvacBlowerArbResult m1 : 43|2@1+ (1,0) [0|3] "" Vector__XXX
 SG_ VCLEFT_hvacBlowerArbCurrent m1 : 48|8@1+ (0.1,0) [0|25.5] "A" Vector__XXX
 SG_ VCLEFT_hvacBlowerTorqueIndexFilt m1 : 56|7@1+ (1,0) [0|127] "%" Vector__XXX

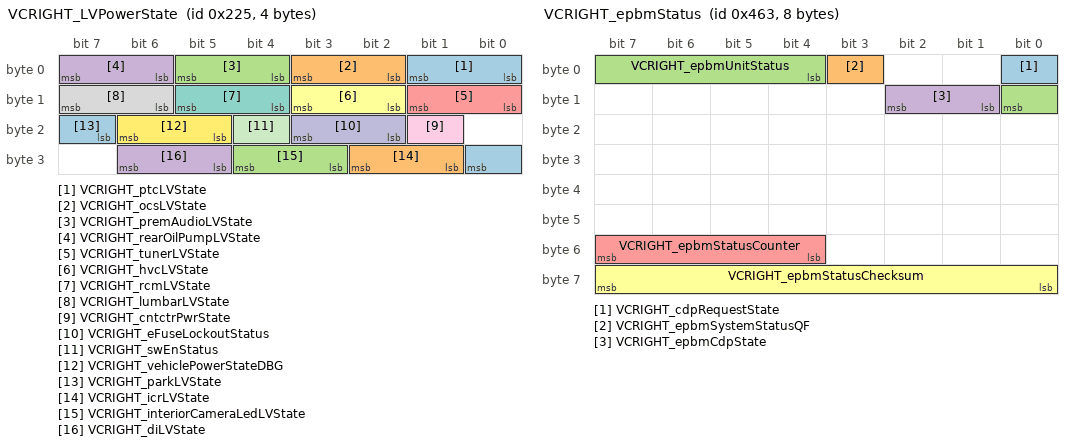
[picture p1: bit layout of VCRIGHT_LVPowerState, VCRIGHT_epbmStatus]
BO_ 549 VCRIGHT_LVPowerState: 4 VCRIGHT
 SG_ VCRIGHT_ptcLVState : 0|2@1+ (1,0) [0|3] "" Vector__XXX
 SG_ VCRIGHT_ocsLVState : 2|2@1+ (1,0) [0|3] "" Vector__XXX
 SG_ VCRIGHT_premAudioLVState : 4|2@1+ (1,0) [0|3] "" Vector__XXX
 SG_ VCRIGHT_rearOilPumpLVState : 6|2@1+ (1,0) [0|3] "" Vector__XXX
 SG_ VCRIGHT_tunerLVState : 8|2@1+ (1,0) [0|3] "" Vector__XXX
 SG_ VCRIGHT_hvcLVState : 10|2@1+ (1,0) [0|3] "" Vector__XXX
 SG_ VCRIGHT_rcmLVState : 12|2@1+ (1,0) [0|3] "" Vector__XXX
 SG_ VCRIGHT_lumbarLVState : 14|2@1+ (1,0) [0|3] "" Vector__XXX
 SG_ VCRIGHT_cntctrPwrState : 17|1@1+ (1,0) [0|1] "" Vector__XXX
 SG_ VCRIGHT_eFuseLockoutStatus : 18|2@1+ (1,0) [0|3] "" Vector__XXX
 SG_ VCRIGHT_swEnStatus : 20|1@1+ (1,0) [0|1] "" Vector__XXX
 SG_ VCRIGHT_vehiclePowerStateDBG : 21|2@1+ (1,0) [0|3] "" Vector__XXX
 SG_ VCRIGHT_parkLVState : 23|2@1+ (1,0) [0|3] "" Vector__XXX
 SG_ VCRIGHT_icrLVState : 25|2@1+ (1,0) [0|3] "" Vector__XXX
 SG_ VCRIGHT_interiorCameraLedLVState : 27|2@1+ (1,0) [0|3] "" Vector__XXX
 SG_ VCRIGHT_diLVState : 29|2@1+ (1,0) [0|3] "" Vector__XXX

BO_ 1795 VCRIGHT_debugThermal10Hz: 8 VCRIGHT
 SG_ VCRIGHT_debugThermal10HzIndex M : 0|4@1+ (1,0) [0|15] "" Vector__XXX
 SG_ VCRIGHT_hvacPanelFloorSplitRow1 m2 : 8|8@1+ (0.4,0) [0|100] "%" Vector__XXX
 SG_ VCRIGHT_hvacDefrostPercent m2 : 16|8@1+ (0.4,0) [0|100] "%" Vector__XXX
 SG_ VCRIGHT_hvacRow2Percent m2 : 24|8@1+ (0.4,0) [0|100] "%" Vector__XXX
 SG_ VCRIGHT_hvacPanelFloorSplitRow2 m2 : 32|8@1+ (0.4,0) [0|100] "%" Vector__XXX
 SG_ VCRIGHT_hvacFreshMassCounter m2 : 40|12@1+ (10,0) [0|40000] "kg" Vector__XXX
 SG_ VCRIGHT_hvacRecircMassCounter m2 : 52|12@1+ (10,0) [0|40000] "kg" Vector__XXX
 SG_ VCRIGHT_setTempAdjustmentLeft m3 : 8|7@1+ (0.1,0) [0|12] "degC" Vector__XXX
 SG_ VCRIGHT_setTempAdjustmentRight m3 : 16|7@1+ (0.1,0) [0|12] "degC" Vector__XXX
 SG_ VCRIGHT_hvacLHVaneVelocity m3 : 24|8@1- (0.8,0) [-100|100] "deg/s" Vector__XXX
 SG_ VCRIGHT_hvacRHVaneVelocity m3 : 32|8@1- (0.8,0) [-100|100] "deg/s" Vector__XXX
 SG_ VCRIGHT_hvacMassflowCompensated m3 : 47|8@1+ (1.5,0) [0|250] "g/s" Vector__XXX
 SG_ VCRIGHT_PTCcenterPowerLeft m5 : 8|6@1+ (30,0) [0|1800] "W" Vector__XXX
 SG_ VCRIGHT_PTCouterPowerLeft m5 : 16|6@1+ (30,0) [0|1800] "W" Vector__XXX
 SG_ VCRIGHT_PTCinnerPowerLeft m5 : 24|6@1+ (30,0) [0|1800] "W" Vector__XXX
 SG_ VCRIGHT_PTCcenterPowerRight m5 : 32|6@1+ (30,0) [0|1800] "W" Vector__XXX
 SG_ VCRIGHT_PTCouterPowerRight m5 : 40|6@1+ (30,0) [0|1800] "W" Vector__XXX
 SG_ VCRIGHT_PTCinnerPowerRight m5 : 48|6@1+ (30,0) [0|1800] "W" Vector__XXX
 SG_ VCRIGHT_PTCcenterStoneTempLeft m6 : 8|8@1+ (2,-70) [-70|438] "degC" Vector__XXX
 SG_ VCRIGHT_PTCcenterStoneTempRight m6 : 16|8@1+ (2,-70) [-70|438] "degC" Vector__XXX
 SG_ VCRIGHT_PTCinnerStoneTempLeft m6 : 24|8@1+ (2,-70) [-70|438] "degC" Vector__XXX
 SG_ VCRIGHT_PTCinnerStoneTempRight m6 : 32|8@1+ (2,-70) [-70|438] "degC" Vector__XXX
 SG_ VCRIGHT_PTCouterStoneTempLeft m7 : 8|8@1+ (2,-70) [-70|438] "degC" Vector__XXX
 SG_ VCRIGHT_PTCouterRodTempLeft m7 : 16|8@1+ (2,-70) [-70|438] "degC" Vector__XXX
 SG_ VCRIGHT_PTCouterAirTempLeft m7 : 24|8@1+ (2,-70) [-70|438] "degC" Vector__XXX
 SG_ VCRIGHT_PTCcenterRodTempLeft m7 : 32|8@1+ (2,-70) [-70|438] "degC" Vector__XXX
 SG_ VCRIGHT_PTCinnerRodTempLeft m7 : 40|8@1+ (2,-70) [-70|438] "degC" Vector__XXX
 SG_ VCRIGHT_PTCcenterAirTempLeft m7 : 48|8@1+ (2,-70) [-70|438] "degC" Vector__XXX
 SG_ VCRIGHT_PTCinnerAirTempLeft m7 : 56|8@1+ (2,-70) [-70|438] "degC" Vector__XXX
 SG_ VCRIGHT_PTCouterStoneTempRight m8 : 8|8@1+ (2,-70) [-70|438] "degC" Vector__XXX
 SG_ VCRIGHT_PTCouterRodTempRight m8 : 16|8@1+ (2,-70) [-70|438] "degC" Vector__XXX
 SG_ VCRIGHT_PTCouterAirTempRight m8 : 24|8@1+ (2,-70) [-70|438] "degC" Vector__XXX
 SG_ VCRIGHT_PTCcenterRodTempRight m8 : 32|8@1+ (2,-70) [-70|438] "degC" Vector__XXX
 SG_ VCRIGHT_PTCinnerRodTempRight m8 : 40|8@1+ (2,-70) [-70|438] "degC" Vector__XXX
 SG_ VCRIGHT_PTCcenterAirTempRight m8 : 48|8@1+ (2,-70) [-70|438] "degC" Vector__XXX
 SG_ VCRIGHT_PTCinnerAirTempRight m8 : 56|8@1+ (2,-70) [-70|438] "degC" Vector__XXX

BO_ 259 VCRIGHT_doorStatus: 8 VCRIGHT
 SG_ VCRIGHT_doorClosureStatusFront : 0|4@1+ (1,0) [1|15] "" Vector__XXX
 SG_ VCRIGHT_doorClosureStatusRear : 4|4@1+ (1,0) [1|15] "" Vector__XXX
 SG_ VCRIGHT_frontLatchSwitch : 8|1@1+ (1,0) [0|1] "" Vector__XXX
 SG_ VCRIGHT_rearLatchSwitch : 9|1@1+ (1,0) [0|1] "" Vector__XXX
 SG_ VCRIGHT_frontHandlePulled : 10|1@1+ (1,0) [0|1] "" Vector__XXX
 SG_ VCRIGHT_rearHandlePulled : 11|1@1+ (1,0) [0|1] "" Vector__XXX
 SG_ VCRIGHT_frontRelActuatorSwitch : 12|1@1+ (1,0) [0|1] "" Vector__XXX
 SG_ VCRIGHT_rearRelActuatorSwitch : 13|1@1+ (1,0) [0|1] "" Vector__XXX
 SG_ VCRIGHT_frontLatchStatus : 14|4@1+ (1,0) [1|15] "" Vector__XXX
 SG_ VCRIGHT_rearLatchStatus : 18|4@1+ (1,0) [1|15] "" Vector__XXX
 SG_ VCRIGHT_lastDoorReqSourceFront : 22|3@1+ (1,0) [0|7] "" Vector__XXX
 SG_ VCRIGHT_lastDoorReqSourceRear : 25|3@1+ (1,0) [0|7] "" Vector__XXX
 SG_ VCRIGHT_frontHandlePulledPersist : 30|1@1+ (1,0) [0|1] "" Vector__XXX
 SG_ VCRIGHT_frontIntSwitchPressed : 31|1@1+ (1,0) [0|1] "" Vector__XXX
 SG_ VCRIGHT_rearIntSwitchPressed : 32|1@1+ (1,0) [0|1] "" Vector__XXX
 SG_ VCRIGHT_mirrorTiltXPosition : 33|8@1+ (0.02,0) [0|5] "V" Vector__XXX
 SG_ VCRIGHT_mirrorTiltYPosition : 41|8@1+ (0.02,0) [0|5] "V" Vector__XXX
 SG_ VCRIGHT_mirrorState : 49|3@1+ (1,0) [0|7] "" Vector__XXX
 SG_ VCRIGHT_mirrorFoldState : 52|3@1+ (1,0) [0|7] "" Vector__XXX
 SG_ VCRIGHT_mirrorDipped : 55|1@1+ (1,0) [0|1] "" Vector__XXX
 SG_ VCRIGHT_trunkLatchStatus : 56|4@1+ (1,0) [1|15] "" Vector__XXX
 SG_ VCRIGHT_mirrorRecallState : 60|3@1+ (1,0) [0|7] "" Vector__XXX
 SG_ VCRIGHT_rearHandlePulledPersist : 63|1@1+ (1,0) [0|1] "" Vector__XXX

BO_ 915 VCRIGHT_epbmDebug: 8 VCRIGHT
 SG_ VCRIGHT_epbmDebugIndex M : 0|1@1+ (1,0) [0|1] "" Vector__XXX
 SG_ VCRIGHT_epbmCaliperState m0 : 1|3@1+ (1,0) [0|7] "" Vector__XXX
 SG_ VCRIGHT_epbmMotorEnabled m0 : 4|1@1+ (1,0) [0|1] "" Vector__XXX
 SG_ VCRIGHT_epbMotorCurrent m0 : 5|11@1+ (0.01,0) [0|20.47] "A" Vector__XXX
 SG_ VCRIGHT_epbmApplyVoltage m0 : 16|11@1+ (0.01,0) [0|20.47] "A" Vector__XXX
 SG_ VCRIGHT_epbmReleaseVoltage m0 : 27|11@1+ (0.01,0) [0|20.47] "A" Vector__XXX
 SG_ VCRIGHT_summonFaultReason m0 : 40|5@1+ (1,0) [0|31] "" Vector__XXX
 SG_ VCRIGHT_epbSummonState m0 : 45|3@1+ (1,0) [0|7] "" Vector__XXX
 SG_ VCRIGHT_epbmSummonState m0 : 48|3@1+ (1,0) [0|7] "" Vector__XXX
 SG_ VCRIGHT_epbUnitStatus m0 : 51|5@1+ (1,0) [0|31] "" Vector__XXX
 SG_ VCRIGHT_epbmFaultStatus m0 : 56|2@1+ (1,0) [0|3] "" Vector__XXX
 SG_ VCRIGHT_epbFaultStatus m0 : 58|2@1+ (1,0) [0|3] "" Vector__XXX
 SG_ VCRIGHT_epbmSystemStatus m0 : 60|4@1+ (1,0) [0|15] "" Vector__XXX

BO_ 1123 VCRIGHT_epbmStatus: 8 VCRIGHT
 SG_ VCRIGHT_cdpRequestState : 0|1@1+ (1,0) [0|1] "" Vector__XXX
 SG_ VCRIGHT_epbmSystemStatusQF : 3|1@1+ (1,0) [0|1] "" Vector__XXX
 SG_ VCRIGHT_epbmUnitStatus : 4|5@1+ (1,0) [0|31] "" Vector__XXX
 SG_ VCRIGHT_epbmCdpState : 9|2@1+ (1,0) [0|3] "" Vector__XXX
 SG_ VCRIGHT_epbmStatusCounter : 52|4@1+ (1,0) [0|15] "" Vector__XXX
 SG_ VCRIGHT_epbmStatusChecksum : 56|8@1+ (1,0) [0|255] "" Vector__XXX

BO_ 579 VCRIGHT_hvacStatus: 8 VCRIGHT
 SG_ VCRIGHT_hvacStatusIndex M : 0|3@1+ (1,0) [0|7] "" Vector__XXX
 SG_ VCRIGHT_childModeHVACState m0 : 20|2@1+ (1,0) [0|3] "" Vector__XXX
 SG_ VCRIGHT_dogModeState m0 : 22|4@1+ (1,0) [0|15] "" Vector__XXX
 SG_ VCRIGHT_hvacCabinTempEstValid m0 : 26|1@1+ (1,0) [0|1] "" Vector__XXX
 SG_ VCRIGHT_COPNotRunningReasonFilte m0 : 27|3@1+ (1,0) [0|7] "" Vector__XXX
 SG_ VCRIGHT_hvacCabinTempEst m0 : 30|11@1+ (0.1,-40) [-40|164] "degC" Vector__XXX
 SG_ VCRIGHT_hvacAirDistributionMode m0 : 41|3@1+ (1,0) [0|7] "" Vector__XXX
 SG_ VCRIGHT_hvacBlowerSegment m0 : 44|4@1+ (1,0) [0|15] "" Vector__XXX
 SG_ VCRIGHT_hvacRecirc m0 : 48|2@1+ (1,0) [0|3] "" Vector__XXX
 SG_ VCRIGHT_hvacACRunning m0 : 50|1@1+ (1,0) [0|1] "" Vector__XXX
 SG_ VCRIGHT_hvacPowerState m0 : 51|3@1+ (1,0) [0|7] "" Vector__XXX
 SG_ VCRIGHT_hvacVentStatus m0 : 54|2@1+ (1,0) [0|3] "" Vector__XXX
 SG_ VCRIGHT_hvacSecondRowState m0 : 56|3@1+ (1,0) [0|7] "" Vector__XXX
 SG_ VCRIGHT_hvacSystemNominal m0 : 59|1@1+ (1,0) [0|1] "" Vector__XXX
 SG_ VCRIGHT_hvacModelInitStatus m0 : 60|4@1+ (1,0) [0|15] "" Vector__XXX
 SG_ VCRIGHT_hvacMassflowRefrigSysRig m1 : 3|7@1+ (1,0) [0|125] "g/s" Vector__XXX
 SG_ VCRIGHT_hvacRecircDoorPercent m1 : 10|6@1+ (1.6,0) [0|100] "%" Vector__XXX
 SG_ VCRIGHT_tempDuctLeft m1 : 16|8@1+ (0.5,-22) [-22|105] "degC" Vector__XXX
 SG_ VCRIGHT_hvacMassflowRefrigSystem m1 : 24|8@1+ (1,0) [0|250] "g/s" Vector__XXX
 SG_ VCRIGHT_tempDuctRight m1 : 32|8@1+ (0.5,-22) [-22|105] "degC" Vector__XXX
 SG_ VCRIGHT_hvacMassflowRefrigSysLef m1 : 40|7@1+ (1,0) [0|125] "g/s" Vector__XXX
 SG_ VCRIGHT_hvacDuctTargetLeft m1 : 48|8@1+ (0.5,-40) [-40|80] "degC" Vector__XXX
 SG_ VCRIGHT_hvacDuctTargetRight m1 : 56|8@1+ (0.5,-40) [-40|80] "degC" Vector__XXX
 SG_ VCRIGHT_enableTripleCameraFanPow m2 : 9|1@1+ (1,0) [0|1] "" Vector__XXX
 SG_ VCRIGHT_tempDuctRightUpper m2 : 10|8@1+ (0.5,-22) [-22|105] "degC" Vector__XXX
 SG_ VCRIGHT_hpSplitTempsEnabled m2 : 18|1@1+ (1,0) [0|1] "" Vector__XXX
 SG_ VCRIGHT_hvacEvapInletTempEstimat m2 : 19|10@1+ (0.13,-40) [-40|90] "degC" Vector__XXX
 SG_ VCRIGHT_tempMonitorNotNominal m2 : 29|1@1+ (1,0) [0|1] "" Vector__XXX
 SG_ VCRIGHT_hvacCabinAtTempTarget m2 : 30|1@1+ (1,0) [0|1] "" Vector__XXX
 SG_ VCRIGHT_hvacReqSecondRow m2 : 31|1@1+ (1,0) [0|1] "" Vector__XXX
 SG_ VCRIGHT_hvacAirflowReason m2 : 32|5@1+ (1,0) [0|31] "" Vector__XXX
 SG_ VCRIGHT_autoHvacBlowerShouldLimi m2 : 37|1@1+ (1,0) [0|1] "" Vector__XXX
 SG_ VCRIGHT_solarLoadOnVehicle m2 : 40|8@1+ (4,0) [0|1016] "W/m2" Vector__XXX
 SG_ VCRIGHT_refrigDistCommanded m2 : 48|1@1+ (1,0) [0|1] "" Vector__XXX
 SG_ VCRIGHT_hvacFrontRightSeatFanSta m2 : 49|2@1+ (1,0) [0|3] "" Vector__XXX
 SG_ VCRIGHT_hvacFrontLeftSeatFanStat m2 : 51|2@1+ (1,0) [0|3] "" Vector__XXX
 SG_ VCRIGHT_hvacFrontRightSeatHeatSt m3 : 4|2@1+ (1,0) [0|3] "" Vector__XXX
 SG_ VCRIGHT_hvacSeatFrontLeftTempTar m3 : 6|8@1+ (0.5,-40) [-40|80] "degC" Vector__XXX
 SG_ VCRIGHT_hvacManualToAutoNotify m3 : 14|3@1+ (1,0) [0|7] "" Vector__XXX
 SG_ VCRIGHT_hvacRequestsFullAuto m3 : 17|3@1+ (1,0) [0|7] "" Vector__XXX
 SG_ VCRIGHT_passengerPresentHvacCycl m3 : 21|1@1+ (1,0) [0|1] "" Vector__XXX
 SG_ VCRIGHT_hvacRequestsAutoIntake m3 : 22|1@1+ (1,0) [0|1] "" Vector__XXX
 SG_ VCRIGHT_steeringWheelHeatStatus m3 : 24|2@1+ (1,0) [0|3] "" Vector__XXX
 SG_ VCRIGHT_autoDefogStatus m3 : 26|2@1+ (1,0) [0|3] "" Vector__XXX
 SG_ VCRIGHT_solarElevation m3 : 31|9@1- (0.5,0) [-127.5|127.5] "deg" Vector__XXX
 SG_ VCRIGHT_minsToSunrise m3 : 40|8@1+ (10,0) [0|2540] "min" Vector__XXX
 SG_ VCRIGHT_minsToSunset m3 : 48|8@1+ (10,0) [0|2540] "min" Vector__XXX
 SG_ VCRIGHT_hvacLimitedReasonRight m3 : 56|3@1+ (1,0) [0|7] "" Vector__XXX
 SG_ VCRIGHT_hvacLimitedReasonLeft m3 : 59|3@1+ (1,0) [0|7] "" Vector__XXX
 SG_ VCRIGHT_hvacOverheatProtActive m3 : 63|1@1+ (1,0) [0|1] "" Vector__XXX
 SG_ VCRIGHT_tempDuctLeftUpper m4 : 10|8@1+ (0.5,-22) [-22|105] "degC" Vector__XXX
 SG_ VCRIGHT_hvacFrontLeftSeatHeatSta m4 : 18|2@1+ (1,0) [0|3] "" Vector__XXX
 SG_ VCRIGHT_hvacQdotLeft m4 : 20|14@1+ (1,-8191) [-8191|8191] "W" Vector__XXX
 SG_ VCRIGHT_hvacQdotRight m4 : 34|14@1+ (1,-8191) [-8191|8191] "W" Vector__XXX
 SG_ VCRIGHT_tempDuctLeftLower m4 : 48|8@1+ (0.5,-22) [-22|105] "degC" Vector__XXX
 SG_ VCRIGHT_tempDuctRightLower m4 : 56|8@1+ (0.5,-22) [-22|105] "degC" Vector__XXX
 SG_ VCRIGHT_modeledCabinPressure m5 : 24|8@1+ (1,0) [0|255] "Pa" Vector__XXX
 SG_ VCRIGHT_blowerTorqueIndex m5 : 32|7@1+ (1,0) [0|127] "%" Vector__XXX
 SG_ VCRIGHT_autoSwingLeftPosX m5 : 39|8@1+ (0.4,0) [0|100] "%" Vector__XXX
 SG_ VCRIGHT_autoSwingRightPositionX m5 : 48|8@1+ (0.4,0) [0|100] "%" Vector__XXX
 SG_ VCRIGHT_autoSwingAvailable m5 : 56|1@1+ (1,0) [0|1] "" Vector__XXX

BO_ 774 VCRIGHT_info: 8 VCRIGHT
 SG_ VCRIGHT_infoIndex M : 0|8@1+ (1,0) [0|255] "" Vector__XXX
 SG_ VCRIGHT_infoBuildType m10 : 8|3@1+ (1,0) [0|7] "" Vector__XXX
 SG_ VCRIGHT_infoBuildConfigId m10 : 16|16@1+ (1,0) [0|65535] "" Vector__XXX
 SG_ VCRIGHT_infoHardwareId m10 : 32|16@1+ (1,0) [0|65535] "" Vector__XXX
 SG_ VCRIGHT_infoComponentId m10 : 48|16@1+ (1,0) [0|65535] "" Vector__XXX
 SG_ VCRIGHT_infoPcbaId m11 : 8|8@1+ (1,0) [0|255] "" Vector__XXX
 SG_ VCRIGHT_infoAssemblyId m11 : 16|8@1+ (1,0) [0|254] "" Vector__XXX
 SG_ VCRIGHT_infoUsageId m11 : 24|16@1+ (1,0) [0|65535] "" Vector__XXX
 SG_ VCRIGHT_infoSubUsageId m11 : 40|16@1+ (1,0) [0|65535] "" Vector__XXX
 SG_ VCRIGHT_infoAppCrc m13 : 8|32@1+ (1,0) [0|4294967295] "" Vector__XXX
 SG_ VCRIGHT_infoAppGitHash m17 : 8|56@1+ (1,0) [0|7.20575940379e+16] "" Vector__XXX
 SG_ VCRIGHT_infoBootGitHash m18 : 8|56@1+ (1,0) [0|7.20575940379e+16] "" Vector__XXX
 SG_ VCRIGHT_infoPlatformType m19 : 8|8@1+ (1,0) [0|255] "" Vector__XXX
 SG_ VCRIGHT_infoBootUdsProtoVersion m20 : 8|16@1+ (1,0) [0|65535] "" Vector__XXX
 SG_ VCRIGHT_infoBootCrc m20 : 24|32@1+ (1,0) [0|4294967295] "" Vector__XXX

BO_ 1803 VCRIGHT_logging0point1Hz: 8 VCRIGHT
 SG_ VCRIGHT_logging0point1HzIndex M : 0|4@1+ (1,0) [0|15] "" Vector__XXX
 SG_ VCRIGHT_cabinAirFilterLifeRemain m2 : 8|7@1+ (1,0) [0|127] "%" Vector__XXX
 SG_ VCRIGHT_HEPAAirFilterLifeRemaini m2 : 16|7@1+ (1,0) [0|127] "%" Vector__XXX
 SG_ VCRIGHT_leftPTCCompromisedRod m2 : 24|3@1+ (1,0) [0|7] "" Vector__XXX
 SG_ VCRIGHT_rightPTCCompromisedRod m2 : 27|3@1+ (1,0) [0|7] "" Vector__XXX
 SG_ VCRIGHT_hepaFilterHealthScore m2 : 32|7@1+ (1,0) [0|127] "%" Vector__XXX
 SG_ VCRIGHT_cabinFilterHealthScore m2 : 40|7@1+ (1,0) [0|127] "%" Vector__XXX
 SG_ VCRIGHT_cabinTempBreathLevelFOff m2 : 47|8@1+ (0.5,-40) [-40|80] "degC" Vector__XXX
 SG_ VCRIGHT_airDistributionModeAdjus m2 : 55|9@1+ (0.001,1) [1|1.5] "-" Vector__XXX
 SG_ VCRIGHT_hvacLHBleedEndStop m3 : 8|8@1+ (0.02,0) [0|5] "V" Vector__XXX
 SG_ VCRIGHT_hvacRHBleedEndStop m3 : 16|8@1+ (0.02,0) [0|5] "V" Vector__XXX
 SG_ VCRIGHT_hvacLHVaneEndStop m3 : 24|8@1+ (0.02,0) [0|5] "V" Vector__XXX
 SG_ VCRIGHT_hvacRHVaneEndStop m3 : 32|8@1+ (0.02,0) [0|5] "V" Vector__XXX
 SG_ VCRIGHT_hvacUpperModeEndStop m3 : 40|8@1+ (0.02,0) [0|5] "V" Vector__XXX
 SG_ VCRIGHT_hvacLowerModeEndStop m3 : 48|8@1+ (0.02,0) [0|5] "V" Vector__XXX
 SG_ VCRIGHT_hvacIntakeEndStop m3 : 56|8@1+ (0.02,0) [0|5] "V" Vector__XXX
 SG_ VCRIGHT_hvacLHBleedZeroStop m4 : 8|8@1+ (0.02,0) [0|5] "V" Vector__XXX
 SG_ VCRIGHT_hvacRHBleedZeroStop m4 : 16|8@1+ (0.02,0) [0|5] "V" Vector__XXX
 SG_ VCRIGHT_hvacLHVaneZeroStop m4 : 24|8@1+ (0.02,0) [0|5] "V" Vector__XXX
 SG_ VCRIGHT_hvacRHVaneZeroStop m4 : 32|8@1+ (0.02,0) [0|5] "V" Vector__XXX
 SG_ VCRIGHT_hvacUpperModeZeroStop m4 : 40|8@1+ (0.02,0) [0|5] "V" Vector__XXX
 SG_ VCRIGHT_hvacLowerModeZeroStop m4 : 48|8@1+ (0.02,0) [0|5] "V" Vector__XXX
 SG_ VCRIGHT_hvacIntakeZeroStop m4 : 56|8@1+ (0.02,0) [0|5] "V" Vector__XXX
 SG_ VCRIGHT_ambientTempLimp m6 : 8|8@1+ (0.5,-40) [-40|80] "degC" Vector__XXX
 SG_ VCRIGHT_cabinProbeTempLimp m6 : 16|8@1+ (0.5,-40) [-40|80] "degC" Vector__XXX
 SG_ VCRIGHT_thsTempLimp m6 : 24|8@1+ (0.5,-40) [-40|80] "degC" Vector__XXX
 SG_ VCRIGHT_thsCabinWaterMassLimp m6 : 32|8@1+ (0.5,0) [0|124] "g/kg" Vector__XXX
 SG_ VCRIGHT_thsSolarIrradianceLimp m6 : 40|8@1+ (5,0) [0|1270] "W/m2" Vector__XXX
 SG_ VCRIGHT_silentWakeRecordCount m6 : 48|5@1+ (1,0) [0|31] "" Vector__XXX
 SG_ VCRIGHT_evapCondensateMass m7 : 8|8@1+ (2,0) [0|500] "g" Vector__XXX
 SG_ VCRIGHT_airwaveRightLateralTotal m7 : 16|16@1+ (6100,0) [0|399763500] "deg" Vector__XXX
 SG_ VCRIGHT_airwaveLeftLateralTotalT m7 : 32|16@1+ (6100,0) [0|399763500] "deg" Vector__XXX

BO_ 611 VCRIGHT_logging10Hz: 8 VCRIGHT
 SG_ VCRIGHT_logging10HzIndex M : 0|3@1+ (1,0) [0|7] "" Vector__XXX
 SG_ VCRIGHT_hvacLHBleedTarget m0 : 8|8@1+ (0.4,0) [0|100] "%" Vector__XXX
 SG_ VCRIGHT_hvacRHBleedTarget m0 : 16|8@1+ (0.4,0) [0|100] "%" Vector__XXX
 SG_ VCRIGHT_hvacLHVaneTarget m0 : 24|8@1+ (0.4,0) [0|100] "%" Vector__XXX
 SG_ VCRIGHT_hvacRHVaneTarget m0 : 32|8@1+ (0.4,0) [0|100] "%" Vector__XXX
 SG_ VCRIGHT_hvacUpperModeTarget m0 : 40|8@1+ (0.4,0) [0|100] "%" Vector__XXX
 SG_ VCRIGHT_hvacLowerModeTarget m0 : 48|8@1+ (0.4,0) [0|100] "%" Vector__XXX
 SG_ VCRIGHT_hvacIntakeTarget m0 : 56|8@1+ (0.4,0) [0|100] "%" Vector__XXX
 SG_ VCRIGHT_hvacLHBleedPosition m1 : 8|8@1+ (0.4,0) [0|100] "%" Vector__XXX
 SG_ VCRIGHT_hvacRHBleedPosition m1 : 16|8@1+ (0.4,0) [0|100] "%" Vector__XXX
 SG_ VCRIGHT_hvacLHVanePosition m1 : 24|8@1+ (0.4,0) [0|100] "%" Vector__XXX
 SG_ VCRIGHT_hvacRHVanePosition m1 : 32|8@1+ (0.4,0) [0|100] "%" Vector__XXX
 SG_ VCRIGHT_hvacUpperModePosition m1 : 40|8@1+ (0.4,0) [0|100] "%" Vector__XXX
 SG_ VCRIGHT_hvacLowerModePosition m1 : 48|8@1+ (0.4,0) [0|100] "%" Vector__XXX
 SG_ VCRIGHT_hvacIntakePosition m1 : 56|8@1+ (0.4,0) [0|100] "%" Vector__XXX
 SG_ VCRIGHT_hvacLHBleedActuatorState m2 : 3|2@1+ (1,0) [0|3] "" Vector__XXX
 SG_ VCRIGHT_hvacRHBleedActuatorState m2 : 5|2@1+ (1,0) [0|3] "" Vector__XXX
 SG_ VCRIGHT_hvacLHVaneActuatorState m2 : 8|2@1+ (1,0) [0|3] "" Vector__XXX
 SG_ VCRIGHT_hvacRHVaneActuatorState m2 : 10|2@1+ (1,0) [0|3] "" Vector__XXX
 SG_ VCRIGHT_hvacUpperModeActState m2 : 12|2@1+ (1,0) [0|3] "" Vector__XXX
 SG_ VCRIGHT_hvacLowerModeActState m2 : 14|2@1+ (1,0) [0|3] "" Vector__XXX
 SG_ VCRIGHT_hvacIntakeActuatorState m2 : 16|2@1+ (1,0) [0|3] "" Vector__XXX
 SG_ VCRIGHT_EvapPulldownBiasActive m2 : 20|1@1+ (1,0) [0|1] "" Vector__XXX
 SG_ VCRIGHT_tempDatLeftEst m2 : 21|9@1+ (0.5,-22) [-22|200] "degC" Vector__XXX
 SG_ VCRIGHT_tempDatRightEst m2 : 30|9@1+ (0.5,-22) [-22|200] "degC" Vector__XXX
 SG_ VCRIGHT_tempDuctLeftEst m2 : 40|8@1+ (0.5,-22) [-22|105] "degC" Vector__XXX
 SG_ VCRIGHT_tempDuctRightEst m2 : 48|8@1+ (0.5,-22) [-22|105] "degC" Vector__XXX
 SG_ VCRIGHT_ptcHeaterBadRodDetection m2 : 56|4@1+ (1,0) [0|15] "" Vector__XXX
 SG_ VCRIGHT_leftVerticalActuatorDuty m4 : 8|6@1- (4,0) [-100|100] "%" Vector__XXX
 SG_ VCRIGHT_leftLateralActuatorDuty m4 : 16|6@1- (4,0) [-100|100] "%" Vector__XXX
 SG_ VCRIGHT_rightVerticalActuatorDut m4 : 24|6@1- (4,0) [-100|100] "%" Vector__XXX
 SG_ VCRIGHT_rightLateralActuatorDuty m4 : 30|6@1- (4,0) [-100|100] "%" Vector__XXX
 SG_ VCRIGHT_frontLeftSeatTempTargetQ m4 : 36|6@1+ (0.75,20) [20|60] "degC" Vector__XXX
 SG_ VCRIGHT_frontRightSeatTempTarget m4 : 42|6@1+ (1,20) [20|60] "degC" Vector__XXX

BO_TX_BU_ 322 : VCLEFT;
BO_TX_BU_ 994 : VCLEFT;
BO_TX_BU_ 1802 : VCLEFT;
BO_TX_BU_ 936 : VCLEFT;
BO_TX_BU_ 727 : VCLEFT;
BO_TX_BU_ 1863 : VCLEFT;
BO_TX_BU_ 1250 : VCLEFT;
BO_TX_BU_ 738 : VCLEFT;
BO_TX_BU_ 930 : VCLEFT;
BO_TX_BU_ 962 : VCLEFT;
BO_TX_BU_ 656 : VCLEFT;
BO_TX_BU_ 657 : VCLEFT;
BO_TX_BU_ 549 : VCRIGHT;
BO_TX_BU_ 1795 : VCRIGHT;
BO_TX_BU_ 259 : VCRIGHT;
BO_TX_BU_ 915 : VCRIGHT;
BO_TX_BU_ 1123 : VCRIGHT;
BO_TX_BU_ 579 : VCRIGHT;
BO_TX_BU_ 774 : VCRIGHT;
BO_TX_BU_ 1803 : VCRIGHT;
BO_TX_BU_ 611 : VCRIGHT;
CM_ BO_ 322 "Left body controller message: liftgate status";
CM_ SG_ 322 VCLEFT_liftgateStatusIndex "Left body controller: liftgate status index";
CM_ SG_ 322 VCLEFT_liftgateState "State of the power liftgate";
CM_ SG_ 322 VCLEFT_liftgateStoppingCondition "Stopping condition for the power liftgate";
CM_ SG_ 322 VCLEFT_liftgateMvmntNotAllowedCo "Movement not allowed condition for the power liftgate";
CM_ SG_ 322 VCLEFT_liftgatePositionCalibrate "Liftgate calibrated";
CM_ SG_ 322 VCLEFT_liftgateUIChimeRequest "Request from the liftgate module to sound a UI chime";
CM_ SG_ 322 VCLEFT_liftgatePhysicalChimeRequ "Request from the liftgate module to sound a physical chime";
CM_ SG_ 322 VCLEFT_liftgateEstimatedStrutTem "Left body controller: liftgate estimated strut temp";
CM_ SG_ 322 VCLEFT_liftgateStaticStrutMode "Static strut mode based on its velocity; raw 0 = signal not available (SNA)";
CM_ SG_ 322 VCLEFT_liftgateRequestSource "Movement request source for the power liftgate";
CM_ SG_ 322 VCLEFT_liftgateNewHeightNudge "Left body controller: liftgate new height nudge";
CM_ SG_ 322 VCLEFT_liftgateNewSaveHeight "Newly saved height of liftgate tip at max open";
CM_ SG_ 322 VCLEFT_liftgateGeofenceState "State of the geofence save process";
CM_ SG_ 322 VCLEFT_liftgateAboveCrossoverAng "Left body controller: liftgate above crossover angle";
CM_ SG_ 322 VCLEFT_liftgateLatchRequest "Reqeusts the liftgate latch to perform an action";
CM_ SG_ 322 VCLEFT_liftgateStrutDutyCycle "Left body controller: liftgate strut duty cycle";
CM_ SG_ 322 VCLEFT_liftgateStrutCurrent "Left body controller: liftgate strut current";
CM_ SG_ 322 VCLEFT_liftgatePosition "Liftgate position";
CM_ SG_ 322 VCLEFT_liftgateSpeed "Left body controller: liftgate speed";
CM_ SG_ 322 VCLEFT_liftgateHeight "Height of the liftgate tip above the ground";
CM_ SG_ 322 VCLEFT_liftgatePositionDiff "Left body controller: liftgate position diff";
CM_ BO_ 994 "Left body controller message: light status";
CM_ SG_ 994 VCLEFT_brakeLightStatus "Status of rear left brake light source; raw 3 = signal not available (SNA)";
CM_ SG_ 994 VCLEFT_tailLightStatus "Status of left tail (rear position) light source; raw 3 = signal not available (SNA)";
CM_ SG_ 994 VCLEFT_turnSignalStatus "Status of rear left turn signal light source; raw 3 = signal not available (SNA)";
CM_ SG_ 994 VCLEFT_FLMapLightStatus "Status of front left overhead map light; raw 3 = signal not available (SNA)";
CM_ SG_ 994 VCLEFT_FRMapLightStatus "Status of front right overhead map light; raw 3 = signal not available (SNA)";
CM_ SG_ 994 VCLEFT_RLMapLightStatus "Status of rear left overhead map light; raw 3 = signal not available (SNA)";
CM_ SG_ 994 VCLEFT_RRMapLightStatus "Status of rear right overhead map light; raw 3 = signal not available (SNA)";
CM_ SG_ 994 VCLEFT_FLMapLightSwitchPressed "Status of front left overhead map light switch";
CM_ SG_ 994 VCLEFT_FRMapLightSwitchPressed "Status of front right overhead map light switch";
CM_ SG_ 994 VCLEFT_RLMapLightSwitchPressed "Status of rear left overhead map light switch";
CM_ SG_ 994 VCLEFT_RRMapLightSwitchPressed "Status of rear right overhead map light switch";
CM_ SG_ 994 VCLEFT_leftTurnTrailerLightStatu "The desired on/off state of the trailer left turn light; raw 3 = signal not available (SNA)";
CM_ SG_ 994 VCLEFT_rightTrnTrailerLightStatu "The desired on/off state of the trailer right turn light; raw 3 = signal not available (SNA)";
CM_ SG_ 994 VCLEFT_brakeTrailerLightStatus "The desired on/off state of the trailer brake light; raw 3 = signal not available (SNA)";
CM_ SG_ 994 VCLEFT_tailTrailerLightStatus "The desired on/off state of the trailer tail light; raw 3 = signal not available (SNA)";
CM_ SG_ 994 VCLEFT_fogTrailerLightStatus "The desired on/off state of the trailer fog light; raw 3 = signal not available (SNA)";
CM_ SG_ 994 VCLEFT_frontRideHeight "Left body controller: front ride height; raw 128 = signal not available (SNA)";
CM_ SG_ 994 VCLEFT_rearRideHeight "Left body controller: rear ride height; raw 128 = signal not available (SNA)";
CM_ SG_ 994 VCLEFT_trailerDetected "Trailer light detection status; raw 0 = signal not available (SNA)";
CM_ SG_ 994 VCLEFT_rideHeightSensorFault "Fault status of the front and rear ride height sensors";
CM_ SG_ 994 VCLEFT_reverseTrailerLightStatus "The desired on/off state of the trailer reverse light; raw 3 = signal not available (SNA)";
CM_ SG_ 994 VCLEFT_tailLightOutageStatus "Left body controller: tail light outage status";
CM_ SG_ 994 VCLEFT_reverseLightStatus "Status of left rear body side reverse light source; raw 3 = signal not available (SNA)";
CM_ BO_ 1802 "Left body controller message: logging0point1 hz";
CM_ SG_ 1802 VCLEFT_logging0point1HzIndex "Left body controller: logging0point1 hz index";
CM_ SG_ 1802 VCLEFT_leftBrakeTailLightCurrent "Current sensed by the left brake tail light HSD (high side driver); raw 511 = signal not available (SNA)";
CM_ SG_ 1802 VCLEFT_leftBrakeTailLightCu_0001 "State representing validity of the left brake tail light HSD (high side driver) current sense; raw 0 = signal not available (SNA)";
CM_ SG_ 1802 VCLEFT_leftRearTurnLightCurrent "Current sensed by the left rear turn signal HSD (high side driver); raw 511 = signal not available (SNA)";
CM_ SG_ 1802 VCLEFT_leftRearTurnLightCurrentS "State representing validity of the left rear turn signal HSD (high side driver) current sense; raw 0 = signal not available (SNA)";
CM_ BO_ 936 "Left body controller message: logging1 hz";
CM_ SG_ 936 VCLEFT_logging1HzIndex "Left body controller: logging1 hz index";
CM_ SG_ 936 VCLEFT_tohcPCBATemperature "Left body controller: tohc PCBA temperature; raw 255 = signal not available (SNA)";
CM_ SG_ 936 VCLEFT_phoneChargingFL "Charging status of front left wireless phone charger (if installed)";
CM_ SG_ 936 VCLEFT_phoneChargingFR "Charging status of front right wireless phone charger (if installed)";
CM_ SG_ 936 VCLEFT_swcResistance "Left body controller: swc resistance; raw 127 = signal not available (SNA)";
CM_ SG_ 936 VCLEFT_frontSeatHeatCushionPwr "Left body controller: front seat heat cushion pwr";
CM_ SG_ 936 VCLEFT_frontSeatHeatBackrestPwr "Left body controller: front seat heat backrest pwr";
CM_ BO_ 727 "Left body controller message: pitch estimation";
CM_ SG_ 727 VCLEFT_pitchEstimateOKForAiming "Left body controller: pitch estimate OK for aiming";
CM_ SG_ 727 VCLEFT_pitchEstimateArbitratedSt "Left body controller: pitch estimate arbitrated state";
CM_ SG_ 727 VCLEFT_pitchEstimateFusionState "Left body controller: pitch estimate fusion state";
CM_ SG_ 727 VCLEFT_pitchEstimateStateTransit "Left body controller: pitch estimate state transition ID";
CM_ SG_ 727 VCLEFT_pitchEstimateFusionRaw "Left body controller: pitch estimate fusion raw";
CM_ SG_ 727 VCLEFT_pitchEstimate "Left body controller: pitch estimate; raw 512 = signal not available (SNA)";
CM_ BO_ 1863 "Left body controller message: restraint status";
CM_ SG_ 1863 VCLEFT_frontOccupancyStatus "Left body controller: front occupancy status; raw 7 = signal not available (SNA)";
CM_ SG_ 1863 VCLEFT_frontBuckleStatus "Status of front left seatbelt buckle; raw 3 = signal not available (SNA)";
CM_ SG_ 1863 VCLEFT_rearLeftOccupancyStatus "Status of rear left seat occupancy sensor; raw 3 = signal not available (SNA)";
CM_ SG_ 1863 VCLEFT_rearCenterOccupancyStatus "Status of rear center seat occupancy sensor; raw 3 = signal not available (SNA)";
CM_ SG_ 1863 VCLEFT_rearRightOccupancyStatus "Status of rear right seat occupancy sensor; raw 3 = signal not available (SNA)";
CM_ SG_ 1863 VCLEFT_rearLeftBuckleStatus "Status of rear left seatbelt buckle; raw 3 = signal not available (SNA)";
CM_ SG_ 1863 VCLEFT_rearCenterBuckleStatus "Status of rear center seatbelt buckle; raw 3 = signal not available (SNA)";
CM_ SG_ 1863 VCLEFT_seatTrackPosition "Status of seat track position sensor; raw 7 = signal not available (SNA)";
CM_ SG_ 1863 VCLEFT_restraintStatusCounter "Left body controller: restraint status counter";
CM_ SG_ 1863 VCLEFT_restraintStatusChecksum "Left body controller: restraint status checksum";
CM_ BO_ 1250 "Left body controller message: seat status";
CM_ SG_ 1250 VCLEFT_seatStatusIndex "Left body controller: seat status index";
CM_ SG_ 1250 VCLEFT_frontSeatTrackPos "communicates raw encoder count for driver seat track position";
CM_ SG_ 1250 VCLEFT_frontSeatTrackCurrent "Current drawn by front left seat track motor";
CM_ SG_ 1250 VCLEFT_frontSeatTrackDuty "Front left seat track motor duty cycle";
CM_ SG_ 1250 VCLEFT_frontSeatTrackState "State of front left seat track motor";
CM_ SG_ 1250 VCLEFT_frontSeatTrackCalibrated "Left body controller: front seat track calibrated";
CM_ SG_ 1250 VCLEFT_frontSeatTrackLog "Left body controller: front seat track log";
CM_ SG_ 1250 VCLEFT_frontSeatTrackBridgeSt "Bridge state";
CM_ SG_ 1250 VCLEFT_frontSeatBackPos "communicates raw encoder count for driver seat backrest position";
CM_ SG_ 1250 VCLEFT_frontSeatBackCurrent "Current drawn by front left seat backrest motor";
CM_ SG_ 1250 VCLEFT_frontSeatBackDuty "Front left seat backrest motor duty cycle";
CM_ SG_ 1250 VCLEFT_frontSeatBackState "Active state of front left seat backrest";
CM_ SG_ 1250 VCLEFT_frontSeatBackCalibrated "Left body controller: front seat back calibrated";
CM_ SG_ 1250 VCLEFT_frontSeatBackLog "Left body controller: front seat back log";
CM_ SG_ 1250 VCLEFT_frontSeatBackBridgeSt "Bridge state";
CM_ SG_ 1250 VCLEFT_frontSeatLiftPos "communicates raw encoder count for driver seat lift position";
CM_ SG_ 1250 VCLEFT_frontSeatLiftCurrent "Current drawn by front left seat lift motor";
CM_ SG_ 1250 VCLEFT_frontSeatLiftDuty "Front left seat lift motor duty cycle";
CM_ SG_ 1250 VCLEFT_frontSeatLiftState "Status of front left seat motor";
CM_ SG_ 1250 VCLEFT_frontSeatLiftCalibrated "Left body controller: front seat lift calibrated";
CM_ SG_ 1250 VCLEFT_frontSeatLiftLog "Left body controller: front seat lift log";
CM_ SG_ 1250 VCLEFT_frontSeatLiftBridgeSt "Bridge state";
CM_ SG_ 1250 VCLEFT_frontSeatTiltPos "communicates raw encoder count for driver seat tile position";
CM_ SG_ 1250 VCLEFT_frontSeatTiltCurrent "Current drawn by front left seat tilt motor";
CM_ SG_ 1250 VCLEFT_frontSeatTiltDuty "Front left seat tilt motor duty cycle";
CM_ SG_ 1250 VCLEFT_frontSeatTiltState "State of front left seat tilt motor";
CM_ SG_ 1250 VCLEFT_frontSeatTiltCalibrated "Left body controller: front seat tilt calibrated";
CM_ SG_ 1250 VCLEFT_frontSeatTiltLog "Left body controller: front seat tilt log";
CM_ SG_ 1250 VCLEFT_frontSeatTiltBridgeSt "Bridge state";
CM_ SG_ 1250 VCLEFT_lumbarAState "State of front left seat lumbar bladder A";
CM_ SG_ 1250 VCLEFT_lumbarBState "State of front left lumbar bladder B";
CM_ SG_ 1250 VCLEFT_lumbarAPressureHpa "Left body controller: lumbar a pressure hpa";
CM_ SG_ 1250 VCLEFT_lumbarAPressureHpaFilt "logs filtered pressure of left seat lumbar bladder A";
CM_ SG_ 1250 VCLEFT_lumbarBPressureHpa "Left body controller: lumbar b pressure hpa";
CM_ SG_ 1250 VCLEFT_lumbarBPressureHpaFilt "logs filtered pressure of left seat lumbar bladder B";
CM_ SG_ 1250 VCLEFT_lumbarActiveTooLongErr "Error reported by lumbar ECU: Valve activated too long";
CM_ SG_ 1250 VCLEFT_lumbarMaxPErr "Error reported by lumbar ECU: max bladder pressure reached";
CM_ SG_ 1250 VCLEFT_lumbarOvercurrentErr "Error reported by lumbar ECU: pump overcurrent";
CM_ SG_ 1250 VCLEFT_lumbarMaxOperatingPErr "Error reported by lumbar ECU: max bladder operating pressure reached";
CM_ SG_ 1250 VCLEFT_lumbarMinPErr "Error reported by lumbar ECU: min bladder pressure reached";
CM_ SG_ 1250 VCLEFT_lumbarGeneralErr "Error reported by lumbar ECU: general error";
CM_ SG_ 1250 VCLEFT_lumbarDevMaxPumpPressA "System has reached Tesla specified maximum pressure for lumbar bladder A";
CM_ SG_ 1250 VCLEFT_lumbarDevMaxPumpPressB "System has reached Tesla specified maximum pressure for lumbar bladder B";
CM_ SG_ 1250 VCLEFT_frontSeatTrackPosReal "communicates position of driver seat track in a physical unit";
CM_ SG_ 1250 VCLEFT_frontSeatBackPosReal "communicates position of driver seat backrest in degrees";
CM_ SG_ 1250 VCLEFT_frontSeatLiftPosReal "communicates position of driver seat lift in a physical unit";
CM_ SG_ 1250 VCLEFT_frontSeatTiltPosReal "communicates position of driver seat tilt in a physical unit";
CM_ SG_ 1250 VCLEFT_frontSeatTrackPosOffset "Communicates post calibration position offset of front left seat track in a physical unit";
CM_ SG_ 1250 VCLEFT_frontSeatBackPosOffset "Communicates post calibration position offset of front left seat backrest in degrees";
CM_ SG_ 1250 VCLEFT_frontSeatLiftPosOffset "Communicates post calibration position offset of front left seat lift in a physical unit";
CM_ SG_ 1250 VCLEFT_frontSeatTiltPosOffset "Communicates post calibration position offset of front left seat tilt in a physical unit";
CM_ BO_ 738 "Left body controller message: seat status2";
CM_ SG_ 738 VCLEFT_seatStatus2Index "Left body controller: seat status2 index";
CM_ SG_ 738 VCLEFT_frontSeatHeatCurrent "Left body controller: front seat heat current; raw 12 = signal not available (SNA)";
CM_ SG_ 738 VCLEFT_frontSeatHeatDuty "Left body controller: front seat heat duty";
CM_ SG_ 738 VCLEFT_frontSeatHeatTmp "Left body controller: front seat heat tmp";
CM_ SG_ 738 VCLEFT_frontSeatHeatTmpTarget "Left body controller: front seat heat tmp target";
CM_ SG_ 738 VCLEFT_frontSeatHeatInhibited "Left body controller: front seat heat inhibited";
CM_ SG_ 738 VCLEFT_frontSeatHeatPowered "Left body controller: front seat heat powered";
CM_ SG_ 738 VCLEFT_2RowSeatReclineState "Reports the active state of the 2nd row seat recliner; raw 15 = signal not available (SNA)";
CM_ SG_ 738 VCLEFT_2RowSeatReclineDuty "Reports the 2nd row seat recliner motor duty cycle";
CM_ SG_ 738 VCLEFT_2RowSeatReclineCurrent "Reports the 2nd row seat recliner motor current";
CM_ SG_ 738 VCLEFT_2RowSeatReclineCalibrated "Reports calibration status of the 2nd row seat recliner";
CM_ SG_ 738 VCLEFT_2RowSeatReclinePositionRa "Reports the 2nd row seat recliner raw encoder count";
CM_ SG_ 738 VCLEFT_2RowSeatReclineAngle "Reports the position of the 2nd row seat recliner in degrees";
CM_ SG_ 738 VCLEFT_2RowSeatReclineAbsPosSwit "Reports the status of 2nd row seat recline absolute position (comfort zone) switch; raw 0 = signal not available (SNA)";
CM_ SG_ 738 VCLEFT_2RowSeatReclinePositionSt "Reports the active position state of the 2nd row seat recliner; raw 4 = signal not available (SNA)";
CM_ SG_ 738 VCLEFT_2RowSeatReclineAdjustment "Indicates whether adjustment requests are currently permitted for the rear seat recliner";
CM_ SG_ 738 VCLEFT_2RowSeatReclineFoldAllowe "Indicates whether auto-fold requests are currently permitted for the rear seat recliner";
CM_ SG_ 738 VCLEFT_2RowSeatReclineUnfoldAllo "Indicates whether auto-unfold requests are currently permitted for the rear seat recliner";
CM_ SG_ 738 VCLEFT_2RowSeatReclineNextToggle "Left body controller: 2 row seat recline next toggle direction; raw 2 = signal not available (SNA)";
CM_ SG_ 738 VCLEFT_2RowSeatReclineChoreoBloc "Left body controller: 2 row seat recline choreo blocked by occupancy";
CM_ SG_ 738 VCLEFT_2RowSeat1RClashAvoidanceB "Left body controller: 2 row seat1 r clash avoidance blocked reason";
CM_ SG_ 738 VCLEFT_2RowSeat1RClashAvoidanceS "Left body controller: 2 row seat1 r clash avoidance state";
CM_ SG_ 738 VCLEFT_2RowSeatReclineAbsPo_0001 "Left body controller: 2 row seat recline abs pos switch trans point";
CM_ BO_ 930 "Left body controller message: status";
CM_ SG_ 930 VCLEFT_statusIndex "Left body controller: status index";
CM_ SG_ 930 VCLEFT_securityControllerEnable "Left body controller: security controller enable";
CM_ SG_ 930 VCLEFT_securityControllerVoltage "Voltage of the VCSEC power feed";
CM_ SG_ 930 VCLEFT_consoleDoorAssist "Left body controller: console door assist";
CM_ SG_ 930 VCLEFT_OTAState "Left body controller: OTA state";
CM_ SG_ 930 VCLEFT_5AVoltage "Left body controller: 5 a voltage";
CM_ SG_ 930 VCLEFT_vbatProt "Left body controller: vbat prot";
CM_ SG_ 930 VCLEFT_footwellLightCurrent "Left body controller: footwell light current";
CM_ SG_ 930 VCLEFT_swcInputVoltage "Input voltage reported by steering wheel controller module; raw 255 = signal not available (SNA)";
CM_ SG_ 930 VCLEFT_swcPCBATemperature "Left body controller: swc PCBA temperature; raw 128 = signal not available (SNA)";
CM_ SG_ 930 VCLEFT_obdEthernetActive "Left body controller: obd ethernet active";
CM_ SG_ 930 VCLEFT_rationalityAggregateCurre "Left body controller: rationality aggregate current";
CM_ SG_ 930 VCLEFT_LVBatteryTypeDBG "Left body controller: LV battery type DBG";
CM_ SG_ 930 VCLEFT_DIeFuseFault "Left body controller: d ie fuse fault";
CM_ SG_ 930 VCLEFT_eFuseMgmtVoltageMonitor "Left body controller: e fuse mgmt voltage monitor";
CM_ SG_ 930 VCLEFT_trailerAuxCurrent "Current Draw of the trailer aux output; raw 4095 = signal not available (SNA)";
CM_ SG_ 930 VCLEFT_swcHeatTmp "Temperature of steering wheel heater as reported by NTC; raw 1023 = signal not available (SNA)";
CM_ SG_ 930 VCLEFT_swcHeatStatus "Status of steering wheel heater; raw 0 = signal not available (SNA)";
CM_ SG_ 930 VCLEFT_swcHeatInhibited "Status describing whether steering wheel heat is inhibited";
CM_ SG_ 930 VCLEFT_pcbaTemperature "Left body controller: pcba temperature";
CM_ SG_ 930 VCLEFT_swcHeatPwr "Power of steering wheel heater; raw 511 = signal not available (SNA)";
CM_ SG_ 930 VCLEFT_swcHeatDutyCycle "Steering wheel heater duty cycle; raw 127 = signal not available (SNA)";
CM_ SG_ 930 VCLEFT_DIeFuseCurrent "Left body controller: d ie fuse current";
CM_ SG_ 930 VCLEFT_SWCpresent "Left body controller: SW cpresent";
CM_ BO_ 962 "Left body controller message: switch status";
CM_ SG_ 962 VCLEFT_switchStatusIndex "Left body controller: switch status index";
CM_ SG_ 962 VCLEFT_hornSwitchPressed "Left body controller: horn switch pressed";
CM_ SG_ 962 VCLEFT_hazardButtonPressed "Left body controller: hazard button pressed";
CM_ SG_ 962 VCLEFT_brakeSwitchPressed "Status of the brake pedal switch";
CM_ SG_ 962 VCLEFT_rightMirrorTilt "Left body controller: right mirror tilt";
CM_ SG_ 962 VCLEFT_frontSeatTrackBack "Left body controller: front seat track back; raw 0 = signal not available (SNA)";
CM_ SG_ 962 VCLEFT_frontSeatTrackForward "Left body controller: front seat track forward; raw 0 = signal not available (SNA)";
CM_ SG_ 962 VCLEFT_frontSeatTiltDown "Left body controller: front seat tilt down; raw 0 = signal not available (SNA)";
CM_ SG_ 962 VCLEFT_frontSeatTiltUp "Left body controller: front seat tilt up; raw 0 = signal not available (SNA)";
CM_ SG_ 962 VCLEFT_frontSeatLiftDown "Left body controller: front seat lift down; raw 0 = signal not available (SNA)";
CM_ SG_ 962 VCLEFT_frontSeatLiftUp "Left body controller: front seat lift up; raw 0 = signal not available (SNA)";
CM_ SG_ 962 VCLEFT_frontSeatBackrestBack "Left body controller: front seat backrest back; raw 0 = signal not available (SNA)";
CM_ SG_ 962 VCLEFT_frontSeatBackrestForward "Left body controller: front seat backrest forward; raw 0 = signal not available (SNA)";
CM_ SG_ 962 VCLEFT_frontSeatLumbarDown "Left body controller: front seat lumbar down; raw 0 = signal not available (SNA)";
CM_ SG_ 962 VCLEFT_frontSeatLumbarUp "Left body controller: front seat lumbar up; raw 0 = signal not available (SNA)";
CM_ SG_ 962 VCLEFT_frontSeatLumbarIn "Left body controller: front seat lumbar in; raw 0 = signal not available (SNA)";
CM_ SG_ 962 VCLEFT_frontSeatLumbarOut "Left body controller: front seat lumbar out; raw 0 = signal not available (SNA)";
CM_ SG_ 962 VCLEFT_btnWindowSwPackUpLF "Left body controller: btn window sw pack up LF";
CM_ SG_ 962 VCLEFT_btnWindowSwPackAutoUpLF "Left body controller: btn window sw pack auto up LF";
CM_ SG_ 962 VCLEFT_btnWindowSwPackDownLF "Left body controller: btn window sw pack down LF";
CM_ SG_ 962 VCLEFT_btnWindowSwPackAutoDownLF "Left body controller: btn window sw pack auto down LF";
CM_ SG_ 962 VCLEFT_btnWindowSwPackUpLR "Left body controller: btn window sw pack up LR";
CM_ SG_ 962 VCLEFT_btnWindowSwPackAutoUpLR "Left body controller: btn window sw pack auto up LR";
CM_ SG_ 962 VCLEFT_btnWindowSwPackDownLR "Left body controller: btn window sw pack down LR";
CM_ SG_ 962 VCLEFT_btnWindowSwPackAutoDownLR "Left body controller: btn window sw pack auto down LR";
CM_ SG_ 962 VCLEFT_btnWindowSwPackUpRF "Left body controller: btn window sw pack up RF";
CM_ SG_ 962 VCLEFT_btnWindowSwPackAutoUpRF "Left body controller: btn window sw pack auto up RF";
CM_ SG_ 962 VCLEFT_btnWindowSwPackDownRF "Left body controller: btn window sw pack down RF";
CM_ SG_ 962 VCLEFT_btnWindowSwPackAutoDownRF "Left body controller: btn window sw pack auto down RF";
CM_ SG_ 962 VCLEFT_btnWindowSwPackUpRR "Left body controller: btn window sw pack up RR";
CM_ SG_ 962 VCLEFT_btnWindowSwPackAutoUpRR "Left body controller: btn window sw pack auto up RR";
CM_ SG_ 962 VCLEFT_btnWindowSwPackDownRR "Left body controller: btn window sw pack down RR";
CM_ SG_ 962 VCLEFT_btnWindowSwPackAutoDownRR "Left body controller: btn window sw pack auto down RR";
CM_ SG_ 962 VCLEFT_frontBuckleSwitch "Left body controller: front buckle switch; raw 0 = signal not available (SNA)";
CM_ SG_ 962 VCLEFT_frontOccupancySwitch "Front left seat occupancy status; raw 0 = signal not available (SNA)";
CM_ SG_ 962 VCLEFT_rearLeftBuckleSwitch "Left body controller: rear left buckle switch; raw 0 = signal not available (SNA)";
CM_ SG_ 962 VCLEFT_rearCenterOccupancySwitch "Left body controller: rear center occupancy switch; raw 0 = signal not available (SNA)";
CM_ SG_ 962 VCLEFT_rearLeftOccupancySwitch "Left body controller: rear left occupancy switch; raw 0 = signal not available (SNA)";
CM_ SG_ 962 VCLEFT_rearRightOccupancySwitch "Left body controller: rear right occupancy switch; raw 0 = signal not available (SNA)";
CM_ SG_ 962 VCLEFT_brakePressed "Status of the brake pedal";
CM_ SG_ 962 VCLEFT_rearHVACButtonPressed "Left body controller: rear HVAC button pressed";
CM_ SG_ 962 VCLEFT_rearCenterBuckleSwitch "Left body controller: rear center buckle switch; raw 0 = signal not available (SNA)";
CM_ SG_ 962 VCLEFT_isAlcoholInterlockSet "Reports if the alcohol interlock is set.";
CM_ SG_ 962 VCLEFT_swcLeftTiltRight "Left body controller: swc left tilt right; raw 0 = signal not available (SNA)";
CM_ SG_ 962 VCLEFT_swcLeftPressed "Left body controller: swc left pressed; raw 0 = signal not available (SNA)";
CM_ SG_ 962 VCLEFT_swcRightTiltLeft "Left body controller: swc right tilt left; raw 0 = signal not available (SNA)";
CM_ SG_ 962 VCLEFT_swcRightTiltRight "Left body controller: swc right tilt right; raw 0 = signal not available (SNA)";
CM_ SG_ 962 VCLEFT_swcRightPressed "Left body controller: swc right pressed; raw 0 = signal not available (SNA)";
CM_ SG_ 962 VCLEFT_swcLeftTiltLeft "Left body controller: swc left tilt left; raw 0 = signal not available (SNA)";
CM_ SG_ 962 VCLEFT_swcLeftScrollTicks "Left body controller: swc left scroll ticks";
CM_ SG_ 962 VCLEFT_swcWiperButtonState "Left body controller: swc wiper button state";
CM_ SG_ 962 VCLEFT_swcRightScrollTicks "Encoder value for right steering wheel switch scroll";
CM_ SG_ 962 VCLEFT_swcTurnSignalLeftButtonSt "Left body controller: swc turn signal left button state";
CM_ SG_ 962 VCLEFT_btnWindowUpLR "Left body controller: btn window up LR";
CM_ SG_ 962 VCLEFT_btnWindowAutoUpLR "Left body controller: btn window auto up LR";
CM_ SG_ 962 VCLEFT_btnWindowDownLR "Left body controller: btn window down LR";
CM_ SG_ 962 VCLEFT_btnWindowAutoDownLR "Left body controller: btn window auto down LR";
CM_ SG_ 962 VCLEFT_2RowSeatLeftFoldFlatSwitc "Second row seat left fold flat switch";
CM_ SG_ 962 VCLEFT_2RowSeatRightFoldFlatSwit "Second row seat right fold flat switch";
CM_ SG_ 962 VCLEFT_2RowSeatBothFoldFlatSwitc "Second row seat both fold flat switch";
CM_ SG_ 962 VCLEFT_swcLeftDoublePress "Left body controller: swc left double press";
CM_ SG_ 962 VCLEFT_swcRightDoublePress "Left body controller: swc right double press";
CM_ SG_ 962 VCLEFT_swcTurnSignalRightButtonS "Left body controller: swc turn signal right button state";
CM_ SG_ 962 VCLEFT_swcHighBeamButtonState "Left body controller: swc high beam button state";
CM_ SG_ 962 VCLEFT_swcVoiceControlPress "Left body controller: swc voice control press; raw 0 = signal not available (SNA)";
CM_ SG_ 962 VCLEFT_swcCameraButtonState "Left body controller: swc camera button state";
CM_ SG_ 962 VCLEFT_swcRightPressedQF "Quality of steering wheel right scroll wheel button signal";
CM_ SG_ 962 VCLEFT_frontSeatResistiveOccupan "Front left seat occupancy status; raw 0 = signal not available (SNA)";
CM_ BO_ 656 "Left body controller message: thermal logging10 hz";
CM_ SG_ 656 VCLEFT_thermalLogging10HzIndex "Left body controller: thermal logging10 hz index";
CM_ SG_ 656 VCLEFT_hvac2RLeftLateralVoltage "Left body controller: hvac2 r left lateral voltage";
CM_ SG_ 656 VCLEFT_hvac2RLeftVerticalVoltage "Left body controller: hvac2 r left vertical voltage";
CM_ SG_ 656 VCLEFT_hvac2RRightLateralVoltage "Left body controller: hvac2 r right lateral voltage";
CM_ SG_ 656 VCLEFT_hvac2RRightVerticalVoltag "Left body controller: hvac2 r right vertical voltage";
CM_ SG_ 656 VCLEFT_hvac2RLeftLateralCalibrat "Left body controller: hvac2 r left lateral calibrated";
CM_ SG_ 656 VCLEFT_hvac2RLeftVerticalCalibra "Left body controller: hvac2 r left vertical calibrated";
CM_ SG_ 656 VCLEFT_hvac2RRightLateralCalibra "Left body controller: hvac2 r right lateral calibrated";
CM_ SG_ 656 VCLEFT_hvac2RRightVerticalCalibr "Left body controller: hvac2 r right vertical calibrated";
CM_ SG_ 656 VCLEFT_hvac2RLeftLateralState "Left body controller: hvac2 r left lateral state";
CM_ SG_ 656 VCLEFT_hvac2RLeftVerticalState "Left body controller: hvac2 r left vertical state";
CM_ SG_ 656 VCLEFT_hvac2RRightLateralState "Left body controller: hvac2 r right lateral state";
CM_ SG_ 656 VCLEFT_hvac2RRightVerticalState "Left body controller: hvac2 r right vertical state";
CM_ SG_ 656 VCLEFT_hvacBlowerWindmillElecRpm "Left body controller: hvac blower windmill elec rpm";
CM_ SG_ 656 VCLEFT_hvac2RRightVerticalVeloci "Left body controller: hvac2 r right vertical velocity";
CM_ SG_ 656 VCLEFT_hvacBlowerWindmillBemf "Left body controller: hvac blower windmill bemf";
CM_ SG_ 656 VCLEFT_hvac2RLeftVerticalVelocit "Left body controller: hvac2 r left vertical velocity";
CM_ SG_ 656 VCLEFT_hvac2RLeftLateralVelocity "Left body controller: hvac2 r left lateral velocity";
CM_ SG_ 656 VCLEFT_vcusbLinSchedule "Left body controller: vcusb lin schedule";
CM_ SG_ 656 VCLEFT_hvac2RLeftLateralDuty "Left body controller: hvac2 r left lateral duty";
CM_ SG_ 656 VCLEFT_hvac2RLeftVerticalDuty "Left body controller: hvac2 r left vertical duty";
CM_ SG_ 656 VCLEFT_hvac2RRightLateralDuty "Left body controller: hvac2 r right lateral duty";
CM_ SG_ 656 VCLEFT_hvac2RRightVerticalDuty "Left body controller: hvac2 r right vertical duty";
CM_ SG_ 656 VCLEFT_hvacBlowerWindmilling "Left body controller: hvac blower windmilling";
CM_ SG_ 656 VCLEFT_hvac2RRightLateralVelocit "Left body controller: hvac2 r right lateral velocity";
CM_ SG_ 656 VCLEFT_hvacBlower1msOverrunFrequ "Left body controller: hvac blower1ms overrun frequency";
CM_ SG_ 656 VCLEFT_hvacBlower10msOverrunFreq "Left body controller: hvac blower10ms overrun frequency";
CM_ BO_ 657 "Left body controller message: thermal logging1 hz";
CM_ SG_ 657 VCLEFT_thermalLogging1HzIndex "Left body controller: thermal logging1 hz index";
CM_ SG_ 657 VCLEFT_hvac2RLeftLateralZeroStop "Left body controller: hvac2 r left lateral zero stop voltage";
CM_ SG_ 657 VCLEFT_hvac2RLeftVerticalZeroSto "Left body controller: hvac2 r left vertical zero stop voltage";
CM_ SG_ 657 VCLEFT_hvac2RRightLateralZeroSto "Left body controller: hvac2 r right lateral zero stop voltage";
CM_ SG_ 657 VCLEFT_hvac2RRightVerticalZeroSt "Left body controller: hvac2 r right vertical zero stop voltage";
CM_ SG_ 657 VCLEFT_hvac2RLeftLateralEndStopV "Left body controller: hvac2 r left lateral end stop voltage";
CM_ SG_ 657 VCLEFT_hvac2RLeftVerticalEndStop "Left body controller: hvac2 r left vertical end stop voltage";
CM_ SG_ 657 VCLEFT_hvac2RRightLateralEndStop "Left body controller: hvac2 r right lateral end stop voltage";
CM_ SG_ 657 VCLEFT_hvac2RRightVerticalEndSto "Left body controller: hvac2 r right vertical end stop voltage";
CM_ SG_ 657 VCLEFT_hvacBlowerArbState "Left body controller: hvac blower arb state";
CM_ SG_ 657 VCLEFT_hvacBlowerArbResult "Left body controller: hvac blower arb result";
CM_ SG_ 657 VCLEFT_hvacBlowerArbCurrent "Left body controller: hvac blower arb current";
CM_ SG_ 657 VCLEFT_hvacBlowerTorqueIndexFilt "Left body controller: hvac blower torque index filtered";
CM_ BO_ 549 "Right body controller message: LV power state";
CM_ SG_ 549 VCRIGHT_ptcLVState "Right body controller: ptc LV state";
CM_ SG_ 549 VCRIGHT_ocsLVState "Right body controller: ocs LV state";
CM_ SG_ 549 VCRIGHT_premAudioLVState "Right body controller: prem audio LV state";
CM_ SG_ 549 VCRIGHT_rearOilPumpLVState "Right body controller: rear oil pump LV state";
CM_ SG_ 549 VCRIGHT_tunerLVState "Right body controller: tuner LV state";
CM_ SG_ 549 VCRIGHT_hvcLVState "Right body controller: hvc LV state";
CM_ SG_ 549 VCRIGHT_rcmLVState "Right body controller: rcm LV state";
CM_ SG_ 549 VCRIGHT_lumbarLVState "Right body controller: lumbar LV state";
CM_ SG_ 549 VCRIGHT_cntctrPwrState "Right body controller: cntctr pwr state";
CM_ SG_ 549 VCRIGHT_eFuseLockoutStatus "Right body controller: e fuse lockout status";
CM_ SG_ 549 VCRIGHT_swEnStatus "Status of the internal switched power rail on the board";
CM_ SG_ 549 VCRIGHT_vehiclePowerStateDBG "Right body controller: vehicle power state DBG";
CM_ SG_ 549 VCRIGHT_parkLVState "Right body controller: park LV state";
CM_ SG_ 549 VCRIGHT_icrLVState "Right body controller: icr LV state";
CM_ SG_ 549 VCRIGHT_interiorCameraLedLVState "Right body controller: interior camera led LV state";
CM_ SG_ 549 VCRIGHT_diLVState "Right body controller: di LV state";
CM_ BO_ 1795 "Right body controller message: debug thermal10 hz";
CM_ SG_ 1795 VCRIGHT_debugThermal10HzIndex "Right body controller: debug thermal10 hz index";
CM_ SG_ 1795 VCRIGHT_hvacPanelFloorSplitRow1 "Right body controller: hvac panel floor split row1";
CM_ SG_ 1795 VCRIGHT_hvacDefrostPercent "Right body controller: hvac defrost percent";
CM_ SG_ 1795 VCRIGHT_hvacRow2Percent "Right body controller: hvac row2 percent";
CM_ SG_ 1795 VCRIGHT_hvacPanelFloorSplitRow2 "Right body controller: hvac panel floor split row2";
CM_ SG_ 1795 VCRIGHT_hvacFreshMassCounter "Right body controller: hvac fresh mass counter";
CM_ SG_ 1795 VCRIGHT_hvacRecircMassCounter "Right body controller: hvac recirc mass counter";
CM_ SG_ 1795 VCRIGHT_setTempAdjustmentLeft "Right body controller: set temp adjustment left; raw 127 = signal not available (SNA)";
CM_ SG_ 1795 VCRIGHT_setTempAdjustmentRight "Right body controller: set temp adjustment right; raw 127 = signal not available (SNA)";
CM_ SG_ 1795 VCRIGHT_hvacLHVaneVelocity "Right body controller: hvac LH vane velocity";
CM_ SG_ 1795 VCRIGHT_hvacRHVaneVelocity "Right body controller: hvac RH vane velocity";
CM_ SG_ 1795 VCRIGHT_hvacMassflowCompensated "Right body controller: hvac massflow compensated";
CM_ SG_ 1795 VCRIGHT_PTCcenterPowerLeft "Right body controller: PT ccenter power left; raw 63 = signal not available (SNA)";
CM_ SG_ 1795 VCRIGHT_PTCouterPowerLeft "Right body controller: PT couter power left; raw 63 = signal not available (SNA)";
CM_ SG_ 1795 VCRIGHT_PTCinnerPowerLeft "Right body controller: PT cinner power left; raw 63 = signal not available (SNA)";
CM_ SG_ 1795 VCRIGHT_PTCcenterPowerRight "Right body controller: PT ccenter power right; raw 63 = signal not available (SNA)";
CM_ SG_ 1795 VCRIGHT_PTCouterPowerRight "Right body controller: PT couter power right; raw 63 = signal not available (SNA)";
CM_ SG_ 1795 VCRIGHT_PTCinnerPowerRight "Right body controller: PT cinner power right; raw 63 = signal not available (SNA)";
CM_ SG_ 1795 VCRIGHT_PTCcenterStoneTempLeft "Right body controller: PT ccenter stone temp left; raw 255 = signal not available (SNA)";
CM_ SG_ 1795 VCRIGHT_PTCcenterStoneTempRight "Right body controller: PT ccenter stone temp right; raw 255 = signal not available (SNA)";
CM_ SG_ 1795 VCRIGHT_PTCinnerStoneTempLeft "Right body controller: PT cinner stone temp left; raw 255 = signal not available (SNA)";
CM_ SG_ 1795 VCRIGHT_PTCinnerStoneTempRight "Right body controller: PT cinner stone temp right; raw 255 = signal not available (SNA)";
CM_ SG_ 1795 VCRIGHT_PTCouterStoneTempLeft "Right body controller: PT couter stone temp left; raw 255 = signal not available (SNA)";
CM_ SG_ 1795 VCRIGHT_PTCouterRodTempLeft "Right body controller: PT couter rod temp left; raw 255 = signal not available (SNA)";
CM_ SG_ 1795 VCRIGHT_PTCouterAirTempLeft "Right body controller: PT couter air temp left; raw 255 = signal not available (SNA)";
CM_ SG_ 1795 VCRIGHT_PTCcenterRodTempLeft "Right body controller: PT ccenter rod temp left; raw 255 = signal not available (SNA)";
CM_ SG_ 1795 VCRIGHT_PTCinnerRodTempLeft "Right body controller: PT cinner rod temp left; raw 255 = signal not available (SNA)";
CM_ SG_ 1795 VCRIGHT_PTCcenterAirTempLeft "Right body controller: PT ccenter air temp left; raw 255 = signal not available (SNA)";
CM_ SG_ 1795 VCRIGHT_PTCinnerAirTempLeft "Right body controller: PT cinner air temp left; raw 255 = signal not available (SNA)";
CM_ SG_ 1795 VCRIGHT_PTCouterStoneTempRight "Right body controller: PT couter stone temp right; raw 255 = signal not available (SNA)";
CM_ SG_ 1795 VCRIGHT_PTCouterRodTempRight "Right body controller: PT couter rod temp right; raw 255 = signal not available (SNA)";
CM_ SG_ 1795 VCRIGHT_PTCouterAirTempRight "Right body controller: PT couter air temp right; raw 255 = signal not available (SNA)";
CM_ SG_ 1795 VCRIGHT_PTCcenterRodTempRight "Right body controller: PT ccenter rod temp right; raw 255 = signal not available (SNA)";
CM_ SG_ 1795 VCRIGHT_PTCinnerRodTempRight "Right body controller: PT cinner rod temp right; raw 255 = signal not available (SNA)";
CM_ SG_ 1795 VCRIGHT_PTCcenterAirTempRight "Right body controller: PT ccenter air temp right; raw 255 = signal not available (SNA)";
CM_ SG_ 1795 VCRIGHT_PTCinnerAirTempRight "Right body controller: PT cinner air temp right; raw 255 = signal not available (SNA)";
CM_ BO_ 259 "Right body controller message: door status";
CM_ SG_ 259 VCRIGHT_doorClosureStatusFront "Status of the door from a closures perspective; raw 0 = signal not available (SNA)";
CM_ SG_ 259 VCRIGHT_doorClosureStatusRear "Status of the door from a closures perspective; raw 0 = signal not available (SNA)";
CM_ SG_ 259 VCRIGHT_frontLatchSwitch "State of front left door latch switch representing door open/closed. 0 is open and 1 is closed";
CM_ SG_ 259 VCRIGHT_rearLatchSwitch "State of rear right door latch switch representing door open/closed. 0 is open and 1 is closed";
CM_ SG_ 259 VCRIGHT_frontHandlePulled "Right body controller: front handle pulled";
CM_ SG_ 259 VCRIGHT_rearHandlePulled "Right body controller: rear handle pulled";
CM_ SG_ 259 VCRIGHT_frontRelActuatorSwitch "State of front left door latch switch representing latch arm/unarmed. Disarms while door handle is pulled.";
CM_ SG_ 259 VCRIGHT_rearRelActuatorSwitch "State of rear right door latch switch representing latch arm/unarmed. Disarms while door handle is pulled";
CM_ SG_ 259 VCRIGHT_frontLatchStatus "Status of right front door latch; raw 0 = signal not available (SNA)";
CM_ SG_ 259 VCRIGHT_rearLatchStatus "Status of rear right door latch; raw 0 = signal not available (SNA)";
CM_ SG_ 259 VCRIGHT_lastDoorReqSourceFront "last source of front door open request";
CM_ SG_ 259 VCRIGHT_lastDoorReqSourceRear "last source of rear door open request";
CM_ SG_ 259 VCRIGHT_frontHandlePulledPersist "Right body controller: front handle pulled persist";
CM_ SG_ 259 VCRIGHT_frontIntSwitchPressed "Right body controller: front int switch pressed";
CM_ SG_ 259 VCRIGHT_rearIntSwitchPressed "Right body controller: rear int switch pressed";
CM_ SG_ 259 VCRIGHT_mirrorTiltXPosition "Value representing right side view mirror tilt horizontal position";
CM_ SG_ 259 VCRIGHT_mirrorTiltYPosition "Value representing right side view mirror tilt vertical position";
CM_ SG_ 259 VCRIGHT_mirrorState "State of the right side view mirror.";
CM_ SG_ 259 VCRIGHT_mirrorFoldState "Fold state for the right side view mirror";
CM_ SG_ 259 VCRIGHT_mirrorDipped "Reports if the side view mirrors in are in the dipped position.";
CM_ SG_ 259 VCRIGHT_trunkLatchStatus "State of the trunk latch; raw 0 = signal not available (SNA)";
CM_ SG_ 259 VCRIGHT_mirrorRecallState "State of Mirror Recall.";
CM_ SG_ 259 VCRIGHT_rearHandlePulledPersist "Right body controller: rear handle pulled persist";
CM_ BO_ 915 "Right body controller message: epbm debug";
CM_ SG_ 915 VCRIGHT_epbmDebugIndex "Right body controller: epbm debug index";
CM_ SG_ 915 VCRIGHT_epbmCaliperState "Right body controller: epbm caliper state";
CM_ SG_ 915 VCRIGHT_epbmMotorEnabled "Right body controller: epbm motor enabled";
CM_ SG_ 915 VCRIGHT_epbMotorCurrent "Right body controller: epb motor current";
CM_ SG_ 915 VCRIGHT_epbmApplyVoltage "Right body controller: epbm apply voltage";
CM_ SG_ 915 VCRIGHT_epbmReleaseVoltage "Right body controller: epbm release voltage";
CM_ SG_ 915 VCRIGHT_summonFaultReason "Electronic Parking Brake Monitors error code associated with previous summon failure.";
CM_ SG_ 915 VCRIGHT_epbSummonState "Electronic Parking Brake Monitors reading of Electronic Parking Brake's summon state.";
CM_ SG_ 915 VCRIGHT_epbmSummonState "Electronic Parking Brake Monitors summon state.";
CM_ SG_ 915 VCRIGHT_epbUnitStatus "Electronic Parking Brake Monitors reading of Electronic Parking Brake's state.";
CM_ SG_ 915 VCRIGHT_epbmFaultStatus "Electronic Parking Brake Monitors fault state.";
CM_ SG_ 915 VCRIGHT_epbFaultStatus "Electronic Parking Brake Monitors reading of Electronic Parking Brake's fault state.";
CM_ SG_ 915 VCRIGHT_epbmSystemStatus "Electronic Parking Brake Monitors reading of Electronic Parking Brake's state.";
CM_ BO_ 1123 "Right body controller message: epbm status";
CM_ SG_ 1123 VCRIGHT_cdpRequestState "If the Electronic Parking Brake makes a Controlled Deceleration for Parking Brake request, when cdpOkayToRequest is EPB_CDP_REQUEST_INVALID, cdpRequestState shall transition to EPB_CDP_REQUEST_INVALID, untill the Electronic Parking Brake Monitor enters unitStatus PARKED. Stability Control listens to this signal to qualify Controlled Deceleration for Parking Brake requests from the Electronic Parking Brake.";
CM_ SG_ 1123 VCRIGHT_epbmSystemStatusQF "Right body controller: epbm system status QF";
CM_ SG_ 1123 VCRIGHT_epbmUnitStatus "Electronic Parking Brake Monitors state.";
CM_ SG_ 1123 VCRIGHT_epbmCdpState "Right body controller: epbm cdp state";
CM_ SG_ 1123 VCRIGHT_epbmStatusCounter "Right body controller: epbm status counter";
CM_ SG_ 1123 VCRIGHT_epbmStatusChecksum "Right body controller: epbm status checksum";
CM_ BO_ 579 "Right body controller message: hvac status";
CM_ SG_ 579 VCRIGHT_hvacStatusIndex "Right body controller: hvac status index";
CM_ SG_ 579 VCRIGHT_childModeHVACState "Right body controller: child mode HVAC state";
CM_ SG_ 579 VCRIGHT_dogModeState "Reports the state of Dog Mode.";
CM_ SG_ 579 VCRIGHT_hvacCabinTempEstValid "Right body controller: hvac cabin temp est valid";
CM_ SG_ 579 VCRIGHT_COPNotRunningReasonFilte "Reports the reason cabin overheat protection is not running for User Interface (UI).";
CM_ SG_ 579 VCRIGHT_hvacCabinTempEst "Estimated temperature of the cabin";
CM_ SG_ 579 VCRIGHT_hvacAirDistributionMode "Cabin airflow distribution";
CM_ SG_ 579 VCRIGHT_hvacBlowerSegment "Cabin airflow blower set speed segment";
CM_ SG_ 579 VCRIGHT_hvacRecirc "UI airflow recirculation request state";
CM_ SG_ 579 VCRIGHT_hvacACRunning "Air conditioning is active";
CM_ SG_ 579 VCRIGHT_hvacPowerState "Commanded HVAC power state from UI";
CM_ SG_ 579 VCRIGHT_hvacVentStatus "HVAC vent status";
CM_ SG_ 579 VCRIGHT_hvacSecondRowState "Right body controller: hvac second row state";
CM_ SG_ 579 VCRIGHT_hvacSystemNominal "HVAC system state";
CM_ SG_ 579 VCRIGHT_hvacModelInitStatus "Right body controller: hvac model init status";
CM_ SG_ 579 VCRIGHT_hvacMassflowRefrigSysRig "Right body controller: hvac massflow refrig sys right";
CM_ SG_ 579 VCRIGHT_hvacRecircDoorPercent "Reports the HVAC air recirculation massflow fraction target.";
CM_ SG_ 579 VCRIGHT_tempDuctLeft "Fusion of upper and lower left duct temp sensor values for Heat Pump HVAC case, Raw left/right duct temp sensor value for the legacy HVAC case; raw 255 = signal not available (SNA)";
CM_ SG_ 579 VCRIGHT_hvacMassflowRefrigSystem "Right body controller: hvac massflow refrig system";
CM_ SG_ 579 VCRIGHT_tempDuctRight "Fusion of upper and lower right duct temp sensor values for Heat Pump HVAC case, Raw left/right duct temp sensor value for the legacy HVAC case; raw 255 = signal not available (SNA)";
CM_ SG_ 579 VCRIGHT_hvacMassflowRefrigSysLef "Right body controller: hvac massflow refrig sys left";
CM_ SG_ 579 VCRIGHT_hvacDuctTargetLeft "Left airflow duct temperature target; raw 255 = signal not available (SNA)";
CM_ SG_ 579 VCRIGHT_hvacDuctTargetRight "Right airflow duct temperature target; raw 255 = signal not available (SNA)";
CM_ SG_ 579 VCRIGHT_enableTripleCameraFanPow "Right body controller: enable triple camera fan power in sleep";
CM_ SG_ 579 VCRIGHT_tempDuctRightUpper "Right body controller: temp duct right upper; raw 255 = signal not available (SNA)";
CM_ SG_ 579 VCRIGHT_hpSplitTempsEnabled "Right body controller: hp split temps enabled";
CM_ SG_ 579 VCRIGHT_hvacEvapInletTempEstimat "Right body controller: hvac evap inlet temp estimate; raw 1023 = signal not available (SNA)";
CM_ SG_ 579 VCRIGHT_tempMonitorNotNominal "Right body controller: temp monitor not nominal";
CM_ SG_ 579 VCRIGHT_hvacCabinAtTempTarget "Cabin has reached target temp, send signal to UI";
CM_ SG_ 579 VCRIGHT_hvacReqSecondRow "Right body controller: hvac req second row";
CM_ SG_ 579 VCRIGHT_hvacAirflowReason "Reason for cabin airflow";
CM_ SG_ 579 VCRIGHT_autoHvacBlowerShouldLimi "Cabin airflow blower auto set speed recommendation based on NVH";
CM_ SG_ 579 VCRIGHT_solarLoadOnVehicle "Right body controller: solar load on vehicle; raw 255 = signal not available (SNA)";
CM_ SG_ 579 VCRIGHT_refrigDistCommanded "The HVAC system has set its settings to run the refrigerant distribution routine";
CM_ SG_ 579 VCRIGHT_hvacFrontRightSeatFanSta "Right body controller: hvac front right seat fan status";
CM_ SG_ 579 VCRIGHT_hvacFrontLeftSeatFanStat "Right body controller: hvac front left seat fan status";
CM_ SG_ 579 VCRIGHT_hvacFrontRightSeatHeatSt "Right body controller: hvac front right seat heat status";
CM_ SG_ 579 VCRIGHT_hvacSeatFrontLeftTempTar "Front left seat heating target temperature";
CM_ SG_ 579 VCRIGHT_hvacManualToAutoNotify "Right body controller: hvac manual to auto notify";
CM_ SG_ 579 VCRIGHT_hvacRequestsFullAuto "Request that the UI go to full auto HVAC mode";
CM_ SG_ 579 VCRIGHT_passengerPresentHvacCycl "Right body controller: passenger present hvac cycle";
CM_ SG_ 579 VCRIGHT_hvacRequestsAutoIntake "Request that the UI go to auto intake HVAC mode";
CM_ SG_ 579 VCRIGHT_steeringWheelHeatStatus "Right body controller: steering wheel heat status";
CM_ SG_ 579 VCRIGHT_autoDefogStatus "Indicates defog status of auto HVAC, used for providing messaging to the user";
CM_ SG_ 579 VCRIGHT_solarElevation "Right body controller: solar elevation; raw 256 = signal not available (SNA)";
CM_ SG_ 579 VCRIGHT_minsToSunrise "Right body controller: mins to sunrise; raw 255 = signal not available (SNA)";
CM_ SG_ 579 VCRIGHT_minsToSunset "Right body controller: mins to sunset; raw 255 = signal not available (SNA)";
CM_ SG_ 579 VCRIGHT_hvacLimitedReasonRight "Right body controller: hvac limited reason right";
CM_ SG_ 579 VCRIGHT_hvacLimitedReasonLeft "Right body controller: hvac limited reason left";
CM_ SG_ 579 VCRIGHT_hvacOverheatProtActive "Status of cabin overheat protection";
CM_ SG_ 579 VCRIGHT_tempDuctLeftUpper "Right body controller: temp duct left upper; raw 255 = signal not available (SNA)";
CM_ SG_ 579 VCRIGHT_hvacFrontLeftSeatHeatSta "Right body controller: hvac front left seat heat status";
CM_ SG_ 579 VCRIGHT_hvacQdotLeft "Right body controller: hvac qdot left";
CM_ SG_ 579 VCRIGHT_hvacQdotRight "Right body controller: hvac qdot right";
CM_ SG_ 579 VCRIGHT_tempDuctLeftLower "Right body controller: temp duct left lower; raw 255 = signal not available (SNA)";
CM_ SG_ 579 VCRIGHT_tempDuctRightLower "Right body controller: temp duct right lower; raw 255 = signal not available (SNA)";
CM_ SG_ 579 VCRIGHT_modeledCabinPressure "Right body controller: modeled cabin pressure";
CM_ SG_ 579 VCRIGHT_blowerTorqueIndex "Right body controller: blower torque index";
CM_ SG_ 579 VCRIGHT_autoSwingLeftPosX "Right body controller: auto swing left pos x";
CM_ SG_ 579 VCRIGHT_autoSwingRightPositionX "Right body controller: auto swing right position x";
CM_ SG_ 579 VCRIGHT_autoSwingAvailable "Right body controller: auto swing available";
CM_ BO_ 774 "Right body controller message: info";
CM_ SG_ 774 VCRIGHT_infoIndex "Right body controller: info index";
CM_ SG_ 774 VCRIGHT_infoBuildType "Right body controller: info build type";
CM_ SG_ 774 VCRIGHT_infoBuildConfigId "Right body controller: info build config id";
CM_ SG_ 774 VCRIGHT_infoHardwareId "Right body controller: info hardware id";
CM_ SG_ 774 VCRIGHT_infoComponentId "Right body controller: info component id";
CM_ SG_ 774 VCRIGHT_infoPcbaId "Right body controller: info pcba id";
CM_ SG_ 774 VCRIGHT_infoAssemblyId "Right body controller: info assembly id; raw 255 = signal not available (SNA)";
CM_ SG_ 774 VCRIGHT_infoUsageId "Right body controller: info usage id";
CM_ SG_ 774 VCRIGHT_infoSubUsageId "Right body controller: info sub usage id";
CM_ SG_ 774 VCRIGHT_infoAppCrc "Right body controller: info app crc";
CM_ SG_ 774 VCRIGHT_infoAppGitHash "Right body controller: info app git hash";
CM_ SG_ 774 VCRIGHT_infoBootGitHash "Right body controller: info boot git hash";
CM_ SG_ 774 VCRIGHT_infoPlatformType "Right body controller: info platform type";
CM_ SG_ 774 VCRIGHT_infoBootUdsProtoVersion "Right body controller: info boot uds proto version";
CM_ SG_ 774 VCRIGHT_infoBootCrc "Right body controller: info boot crc";
CM_ BO_ 1803 "Right body controller message: logging0point1 hz";
CM_ SG_ 1803 VCRIGHT_logging0point1HzIndex "Right body controller: logging0point1 hz index";
CM_ SG_ 1803 VCRIGHT_cabinAirFilterLifeRemain "Life remaining on the cabin air filter";
CM_ SG_ 1803 VCRIGHT_HEPAAirFilterLifeRemaini "Life remaining on the cabin air filter";
CM_ SG_ 1803 VCRIGHT_leftPTCCompromisedRod "Right body controller: left PTC compromised rod";
CM_ SG_ 1803 VCRIGHT_rightPTCCompromisedRod "Right body controller: right PTC compromised rod";
CM_ SG_ 1803 VCRIGHT_hepaFilterHealthScore "Right body controller: hepa filter health score";
CM_ SG_ 1803 VCRIGHT_cabinFilterHealthScore "Right body controller: cabin filter health score";
CM_ SG_ 1803 VCRIGHT_cabinTempBreathLevelFOff "Right body controller: cabin temp breath level f off; raw 255 = signal not available (SNA)";
CM_ SG_ 1803 VCRIGHT_airDistributionModeAdjus "Right body controller: air distribution mode adjustment factor";
CM_ SG_ 1803 VCRIGHT_hvacLHBleedEndStop "Right body controller: hvac LH bleed end stop";
CM_ SG_ 1803 VCRIGHT_hvacRHBleedEndStop "Right body controller: hvac RH bleed end stop";
CM_ SG_ 1803 VCRIGHT_hvacLHVaneEndStop "Right body controller: hvac LH vane end stop";
CM_ SG_ 1803 VCRIGHT_hvacRHVaneEndStop "Right body controller: hvac RH vane end stop";
CM_ SG_ 1803 VCRIGHT_hvacUpperModeEndStop "Right body controller: hvac upper mode end stop";
CM_ SG_ 1803 VCRIGHT_hvacLowerModeEndStop "Right body controller: hvac lower mode end stop";
CM_ SG_ 1803 VCRIGHT_hvacIntakeEndStop "Right body controller: hvac intake end stop";
CM_ SG_ 1803 VCRIGHT_hvacLHBleedZeroStop "Right body controller: hvac LH bleed zero stop";
CM_ SG_ 1803 VCRIGHT_hvacRHBleedZeroStop "Right body controller: hvac RH bleed zero stop";
CM_ SG_ 1803 VCRIGHT_hvacLHVaneZeroStop "Right body controller: hvac LH vane zero stop";
CM_ SG_ 1803 VCRIGHT_hvacRHVaneZeroStop "Right body controller: hvac RH vane zero stop";
CM_ SG_ 1803 VCRIGHT_hvacUpperModeZeroStop "Right body controller: hvac upper mode zero stop";
CM_ SG_ 1803 VCRIGHT_hvacLowerModeZeroStop "Right body controller: hvac lower mode zero stop";
CM_ SG_ 1803 VCRIGHT_hvacIntakeZeroStop "Right body controller: hvac intake zero stop";
CM_ SG_ 1803 VCRIGHT_ambientTempLimp "Reports the estimated ambient temperature in limp mode; raw 255 = signal not available (SNA)";
CM_ SG_ 1803 VCRIGHT_cabinProbeTempLimp "Reports the estimated cabin probe temperature in limp mode; raw 255 = signal not available (SNA)";
CM_ SG_ 1803 VCRIGHT_thsTempLimp "Reports the estimated Tesla HVAC Sensor (THS) temperature in limp mode; raw 255 = signal not available (SNA)";
CM_ SG_ 1803 VCRIGHT_thsCabinWaterMassLimp "Reports the estimated Tesla HVAC Sensor (THS) humidity cabin water mass backup in limp mode.";
CM_ SG_ 1803 VCRIGHT_thsSolarIrradianceLimp "Reports the estimated Tesla HVAC Sensor (THS) solar irradiance backup in limp mode; raw 255 = signal not available (SNA)";
CM_ SG_ 1803 VCRIGHT_silentWakeRecordCount "Reports the number of records recorded during silent wake events.";
CM_ SG_ 1803 VCRIGHT_evapCondensateMass "Right body controller: evap condensate mass";
CM_ SG_ 1803 VCRIGHT_airwaveRightLateralTotal "Right body controller: airwave right lateral total travel";
CM_ SG_ 1803 VCRIGHT_airwaveLeftLateralTotalT "Right body controller: airwave left lateral total travel";
CM_ BO_ 611 "Right body controller message: logging10 hz";
CM_ SG_ 611 VCRIGHT_logging10HzIndex "Right body controller: logging10 hz index";
CM_ SG_ 611 VCRIGHT_hvacLHBleedTarget "Right body controller: hvac LH bleed target";
CM_ SG_ 611 VCRIGHT_hvacRHBleedTarget "Right body controller: hvac RH bleed target";
CM_ SG_ 611 VCRIGHT_hvacLHVaneTarget "Right body controller: hvac LH vane target";
CM_ SG_ 611 VCRIGHT_hvacRHVaneTarget "Right body controller: hvac RH vane target";
CM_ SG_ 611 VCRIGHT_hvacUpperModeTarget "Right body controller: hvac upper mode target";
CM_ SG_ 611 VCRIGHT_hvacLowerModeTarget "Right body controller: hvac lower mode target";
CM_ SG_ 611 VCRIGHT_hvacIntakeTarget "Right body controller: hvac intake target";
CM_ SG_ 611 VCRIGHT_hvacLHBleedPosition "Right body controller: hvac LH bleed position";
CM_ SG_ 611 VCRIGHT_hvacRHBleedPosition "Right body controller: hvac RH bleed position";
CM_ SG_ 611 VCRIGHT_hvacLHVanePosition "Right body controller: hvac LH vane position";
CM_ SG_ 611 VCRIGHT_hvacRHVanePosition "Right body controller: hvac RH vane position";
CM_ SG_ 611 VCRIGHT_hvacUpperModePosition "Right body controller: hvac upper mode position";
CM_ SG_ 611 VCRIGHT_hvacLowerModePosition "Right body controller: hvac lower mode position";
CM_ SG_ 611 VCRIGHT_hvacIntakePosition "Right body controller: hvac intake position";
CM_ SG_ 611 VCRIGHT_hvacLHBleedActuatorState "Right body controller: hvac LH bleed actuator state";
CM_ SG_ 611 VCRIGHT_hvacRHBleedActuatorState "Right body controller: hvac RH bleed actuator state";
CM_ SG_ 611 VCRIGHT_hvacLHVaneActuatorState "Right body controller: hvac LH vane actuator state";
CM_ SG_ 611 VCRIGHT_hvacRHVaneActuatorState "Right body controller: hvac RH vane actuator state";
CM_ SG_ 611 VCRIGHT_hvacUpperModeActState "Right body controller: hvac upper mode act state";
CM_ SG_ 611 VCRIGHT_hvacLowerModeActState "Right body controller: hvac lower mode act state";
CM_ SG_ 611 VCRIGHT_hvacIntakeActuatorState "Right body controller: hvac intake actuator state";
CM_ SG_ 611 VCRIGHT_EvapPulldownBiasActive "Indicates if an evap pulldown smell mitigation is active";
CM_ SG_ 611 VCRIGHT_tempDatLeftEst "Right body controller: temp dat left est; raw 255 = signal not available (SNA)";
CM_ SG_ 611 VCRIGHT_tempDatRightEst "Right body controller: temp dat right est; raw 255 = signal not available (SNA)";
CM_ SG_ 611 VCRIGHT_tempDuctLeftEst "Right body controller: temp duct left est; raw 255 = signal not available (SNA)";
CM_ SG_ 611 VCRIGHT_tempDuctRightEst "Right body controller: temp duct right est; raw 255 = signal not available (SNA)";
CM_ SG_ 611 VCRIGHT_ptcHeaterBadRodDetection "Right body controller: ptc heater bad rod detection state";
CM_ SG_ 611 VCRIGHT_leftVerticalActuatorDuty "Reports the HVAC motor duty cycle";
CM_ SG_ 611 VCRIGHT_leftLateralActuatorDuty "Reports the HVAC motor duty cycle";
CM_ SG_ 611 VCRIGHT_rightVerticalActuatorDut "Reports the HVAC motor duty cycle";
CM_ SG_ 611 VCRIGHT_rightLateralActuatorDuty "Reports the HVAC motor duty cycle";
CM_ SG_ 611 VCRIGHT_frontLeftSeatTempTargetQ "Reports the front left seat heating target temperature.";
CM_ SG_ 611 VCRIGHT_frontRightSeatTempTarget "Reports the front right seat heating target temperature.";
BA_DEF_ BO_ "GenMsgCycleTime" INT 0 3600000;
BA_DEF_ BO_ "GenMsgSendType" ENUM "Cyclic","NotUsed","NotUsed","NotUsed","NotUsed","NotUsed","NotUsed","IfActive","NoMsgSendType","NotUsed";
BA_DEF_ BO_ "VFrameFormat" ENUM "StandardCAN","ExtendedCAN","reserved","J1939PG","reserved","reserved","reserved","reserved","reserved","reserved","reserved","reserved","reserved","reserved","StandardCAN_FD","ExtendedCAN_FD";
BA_DEF_ BO_ "CANFD_BRS" ENUM "0","1";
BA_DEF_ SG_ "GenSigSNA" STRING;
BA_DEF_ SG_ "SystemSignalLongSymbol" STRING;
BA_DEF_ SG_ "Confidence" ENUM "validated","plausible","layout-only","contradicted";
BA_DEF_DEF_ "GenMsgCycleTime" 0;
BA_DEF_DEF_ "GenMsgSendType" "NoMsgSendType";
BA_DEF_DEF_ "VFrameFormat" "StandardCAN";
BA_DEF_DEF_ "CANFD_BRS" "1";
BA_DEF_DEF_ "GenSigSNA" "";
BA_DEF_DEF_ "SystemSignalLongSymbol" "";
BA_DEF_DEF_ "Confidence" "layout-only";
BA_ "GenMsgCycleTime" BO_ 322 50;
BA_ "GenMsgSendType" BO_ 322 0;
BA_ "GenMsgCycleTime" BO_ 994 200;
BA_ "GenMsgSendType" BO_ 994 0;
BA_ "GenMsgCycleTime" BO_ 1802 10000;
BA_ "GenMsgSendType" BO_ 1802 0;
BA_ "GenMsgCycleTime" BO_ 936 333;
BA_ "GenMsgSendType" BO_ 936 0;
BA_ "GenMsgCycleTime" BO_ 727 100;
BA_ "GenMsgSendType" BO_ 727 0;
BA_ "GenMsgCycleTime" BO_ 1863 50;
BA_ "GenMsgSendType" BO_ 1863 0;
BA_ "GenMsgCycleTime" BO_ 1250 100;
BA_ "GenMsgSendType" BO_ 1250 0;
BA_ "GenMsgCycleTime" BO_ 738 200;
BA_ "GenMsgSendType" BO_ 738 0;
BA_ "GenMsgCycleTime" BO_ 930 33;
BA_ "GenMsgSendType" BO_ 930 0;
BA_ "GenMsgCycleTime" BO_ 962 50;
BA_ "GenMsgSendType" BO_ 962 0;
BA_ "GenMsgCycleTime" BO_ 656 20;
BA_ "GenMsgSendType" BO_ 656 0;
BA_ "GenMsgCycleTime" BO_ 657 500;
BA_ "GenMsgSendType" BO_ 657 0;
BA_ "GenMsgCycleTime" BO_ 549 100;
BA_ "GenMsgSendType" BO_ 549 0;
BA_ "GenMsgCycleTime" BO_ 1795 10;
BA_ "GenMsgSendType" BO_ 1795 0;
BA_ "GenMsgCycleTime" BO_ 259 100;
BA_ "GenMsgSendType" BO_ 259 0;
BA_ "GenMsgCycleTime" BO_ 915 100;
BA_ "GenMsgSendType" BO_ 915 0;
BA_ "GenMsgCycleTime" BO_ 1123 100;
BA_ "GenMsgSendType" BO_ 1123 0;
BA_ "GenMsgCycleTime" BO_ 579 20;
BA_ "GenMsgSendType" BO_ 579 0;
BA_ "GenMsgCycleTime" BO_ 774 1000;
BA_ "GenMsgSendType" BO_ 774 0;
BA_ "GenMsgCycleTime" BO_ 1803 1250;
BA_ "GenMsgSendType" BO_ 1803 0;
BA_ "GenMsgCycleTime" BO_ 611 20;
BA_ "GenMsgSendType" BO_ 611 0;
BA_ "Confidence" SG_ 322 VCLEFT_liftgateStatusIndex 1;
BA_ "Confidence" SG_ 322 VCLEFT_liftgateState 0;
BA_ "Confidence" SG_ 322 VCLEFT_liftgateStoppingCondition 0;
BA_ "Confidence" SG_ 322 VCLEFT_liftgateMvmntNotAllowedCo 0;
BA_ "SystemSignalLongSymbol" SG_ 322 VCLEFT_liftgateMvmntNotAllowedCo "VCLEFT_liftgateMvmntNotAllowedCondition";
BA_ "Confidence" SG_ 322 VCLEFT_liftgatePositionCalibrate 0;
BA_ "SystemSignalLongSymbol" SG_ 322 VCLEFT_liftgatePositionCalibrate "VCLEFT_liftgatePositionCalibrated";
BA_ "Confidence" SG_ 322 VCLEFT_liftgateUIChimeRequest 0;
BA_ "Confidence" SG_ 322 VCLEFT_liftgatePhysicalChimeRequ 0;
BA_ "SystemSignalLongSymbol" SG_ 322 VCLEFT_liftgatePhysicalChimeRequ "VCLEFT_liftgatePhysicalChimeRequest";
BA_ "Confidence" SG_ 322 VCLEFT_liftgateEstimatedStrutTem 0;
BA_ "SystemSignalLongSymbol" SG_ 322 VCLEFT_liftgateEstimatedStrutTem "VCLEFT_liftgateEstimatedStrutTemp";
BA_ "Confidence" SG_ 322 VCLEFT_liftgateStaticStrutMode 0;
BA_ "GenSigSNA" SG_ 322 VCLEFT_liftgateStaticStrutMode "0";
BA_ "Confidence" SG_ 322 VCLEFT_liftgateRequestSource 0;
BA_ "Confidence" SG_ 322 VCLEFT_liftgateNewHeightNudge 0;
BA_ "Confidence" SG_ 322 VCLEFT_liftgateNewSaveHeight 0;
BA_ "Confidence" SG_ 322 VCLEFT_liftgateGeofenceState 0;
BA_ "Confidence" SG_ 322 VCLEFT_liftgateAboveCrossoverAng 0;
BA_ "SystemSignalLongSymbol" SG_ 322 VCLEFT_liftgateAboveCrossoverAng "VCLEFT_liftgateAboveCrossoverAngle";
BA_ "Confidence" SG_ 322 VCLEFT_liftgateLatchRequest 0;
BA_ "Confidence" SG_ 322 VCLEFT_liftgateStrutDutyCycle 0;
BA_ "Confidence" SG_ 322 VCLEFT_liftgateStrutCurrent 0;
BA_ "Confidence" SG_ 322 VCLEFT_liftgatePosition 0;
BA_ "Confidence" SG_ 322 VCLEFT_liftgateSpeed 0;
BA_ "Confidence" SG_ 322 VCLEFT_liftgateHeight 0;
BA_ "Confidence" SG_ 322 VCLEFT_liftgatePositionDiff 0;
BA_ "Confidence" SG_ 994 VCLEFT_brakeLightStatus 0;
BA_ "GenSigSNA" SG_ 994 VCLEFT_brakeLightStatus "3";
BA_ "Confidence" SG_ 994 VCLEFT_tailLightStatus 0;
BA_ "GenSigSNA" SG_ 994 VCLEFT_tailLightStatus "3";
BA_ "Confidence" SG_ 994 VCLEFT_turnSignalStatus 0;
BA_ "GenSigSNA" SG_ 994 VCLEFT_turnSignalStatus "3";
BA_ "Confidence" SG_ 994 VCLEFT_FLMapLightStatus 0;
BA_ "GenSigSNA" SG_ 994 VCLEFT_FLMapLightStatus "3";
BA_ "Confidence" SG_ 994 VCLEFT_FRMapLightStatus 0;
BA_ "GenSigSNA" SG_ 994 VCLEFT_FRMapLightStatus "3";
BA_ "Confidence" SG_ 994 VCLEFT_RLMapLightStatus 0;
BA_ "GenSigSNA" SG_ 994 VCLEFT_RLMapLightStatus "3";
BA_ "Confidence" SG_ 994 VCLEFT_RRMapLightStatus 0;
BA_ "GenSigSNA" SG_ 994 VCLEFT_RRMapLightStatus "3";
BA_ "Confidence" SG_ 994 VCLEFT_FLMapLightSwitchPressed 0;
BA_ "Confidence" SG_ 994 VCLEFT_FRMapLightSwitchPressed 0;
BA_ "Confidence" SG_ 994 VCLEFT_RLMapLightSwitchPressed 0;
BA_ "Confidence" SG_ 994 VCLEFT_RRMapLightSwitchPressed 0;
BA_ "Confidence" SG_ 994 VCLEFT_leftTurnTrailerLightStatu 0;
BA_ "GenSigSNA" SG_ 994 VCLEFT_leftTurnTrailerLightStatu "3";
BA_ "SystemSignalLongSymbol" SG_ 994 VCLEFT_leftTurnTrailerLightStatu "VCLEFT_leftTurnTrailerLightStatus";
BA_ "Confidence" SG_ 994 VCLEFT_rightTrnTrailerLightStatu 0;
BA_ "GenSigSNA" SG_ 994 VCLEFT_rightTrnTrailerLightStatu "3";
BA_ "SystemSignalLongSymbol" SG_ 994 VCLEFT_rightTrnTrailerLightStatu "VCLEFT_rightTrnTrailerLightStatus";
BA_ "Confidence" SG_ 994 VCLEFT_brakeTrailerLightStatus 0;
BA_ "GenSigSNA" SG_ 994 VCLEFT_brakeTrailerLightStatus "3";
BA_ "Confidence" SG_ 994 VCLEFT_tailTrailerLightStatus 0;
BA_ "GenSigSNA" SG_ 994 VCLEFT_tailTrailerLightStatus "3";
BA_ "Confidence" SG_ 994 VCLEFT_fogTrailerLightStatus 0;
BA_ "GenSigSNA" SG_ 994 VCLEFT_fogTrailerLightStatus "3";
BA_ "Confidence" SG_ 994 VCLEFT_frontRideHeight 0;
BA_ "GenSigSNA" SG_ 994 VCLEFT_frontRideHeight "128";
BA_ "Confidence" SG_ 994 VCLEFT_rearRideHeight 0;
BA_ "GenSigSNA" SG_ 994 VCLEFT_rearRideHeight "128";
BA_ "Confidence" SG_ 994 VCLEFT_trailerDetected 0;
BA_ "GenSigSNA" SG_ 994 VCLEFT_trailerDetected "0";
BA_ "Confidence" SG_ 994 VCLEFT_rideHeightSensorFault 0;
BA_ "Confidence" SG_ 994 VCLEFT_reverseTrailerLightStatus 0;
BA_ "GenSigSNA" SG_ 994 VCLEFT_reverseTrailerLightStatus "3";
BA_ "Confidence" SG_ 994 VCLEFT_tailLightOutageStatus 0;
BA_ "Confidence" SG_ 994 VCLEFT_reverseLightStatus 0;
BA_ "GenSigSNA" SG_ 994 VCLEFT_reverseLightStatus "3";
BA_ "Confidence" SG_ 1802 VCLEFT_logging0point1HzIndex 1;
BA_ "Confidence" SG_ 1802 VCLEFT_leftBrakeTailLightCurrent 0;
BA_ "GenSigSNA" SG_ 1802 VCLEFT_leftBrakeTailLightCurrent "511";
BA_ "Confidence" SG_ 1802 VCLEFT_leftBrakeTailLightCu_0001 0;
BA_ "GenSigSNA" SG_ 1802 VCLEFT_leftBrakeTailLightCu_0001 "0";
BA_ "SystemSignalLongSymbol" SG_ 1802 VCLEFT_leftBrakeTailLightCu_0001 "VCLEFT_leftBrakeTailLightCurrentSenseState";
BA_ "Confidence" SG_ 1802 VCLEFT_leftRearTurnLightCurrent 0;
BA_ "GenSigSNA" SG_ 1802 VCLEFT_leftRearTurnLightCurrent "511";
BA_ "Confidence" SG_ 1802 VCLEFT_leftRearTurnLightCurrentS 0;
BA_ "GenSigSNA" SG_ 1802 VCLEFT_leftRearTurnLightCurrentS "0";
BA_ "SystemSignalLongSymbol" SG_ 1802 VCLEFT_leftRearTurnLightCurrentS "VCLEFT_leftRearTurnLightCurrentSenseState";
BA_ "Confidence" SG_ 936 VCLEFT_logging1HzIndex 1;
BA_ "Confidence" SG_ 936 VCLEFT_tohcPCBATemperature 0;
BA_ "GenSigSNA" SG_ 936 VCLEFT_tohcPCBATemperature "255";
BA_ "Confidence" SG_ 936 VCLEFT_phoneChargingFL 0;
BA_ "Confidence" SG_ 936 VCLEFT_phoneChargingFR 0;
BA_ "Confidence" SG_ 936 VCLEFT_swcResistance 0;
BA_ "GenSigSNA" SG_ 936 VCLEFT_swcResistance "127";
BA_ "Confidence" SG_ 936 VCLEFT_frontSeatHeatCushionPwr 0;
BA_ "Confidence" SG_ 936 VCLEFT_frontSeatHeatBackrestPwr 0;
BA_ "Confidence" SG_ 727 VCLEFT_pitchEstimateArbitratedSt 0;
BA_ "SystemSignalLongSymbol" SG_ 727 VCLEFT_pitchEstimateArbitratedSt "VCLEFT_pitchEstimateArbitratedState";
BA_ "Confidence" SG_ 727 VCLEFT_pitchEstimateFusionState 1;
BA_ "Confidence" SG_ 727 VCLEFT_pitchEstimateStateTransit 1;
BA_ "SystemSignalLongSymbol" SG_ 727 VCLEFT_pitchEstimateStateTransit "VCLEFT_pitchEstimateStateTransitionID";
BA_ "Confidence" SG_ 727 VCLEFT_pitchEstimateFusionRaw 1;
BA_ "Confidence" SG_ 727 VCLEFT_pitchEstimate 1;
BA_ "GenSigSNA" SG_ 727 VCLEFT_pitchEstimate "512";
BA_ "Confidence" SG_ 1863 VCLEFT_frontOccupancyStatus 0;
BA_ "GenSigSNA" SG_ 1863 VCLEFT_frontOccupancyStatus "7";
BA_ "Confidence" SG_ 1863 VCLEFT_frontBuckleStatus 0;
BA_ "GenSigSNA" SG_ 1863 VCLEFT_frontBuckleStatus "3";
BA_ "Confidence" SG_ 1863 VCLEFT_rearLeftOccupancyStatus 0;
BA_ "GenSigSNA" SG_ 1863 VCLEFT_rearLeftOccupancyStatus "3";
BA_ "Confidence" SG_ 1863 VCLEFT_rearCenterOccupancyStatus 0;
BA_ "GenSigSNA" SG_ 1863 VCLEFT_rearCenterOccupancyStatus "3";
BA_ "Confidence" SG_ 1863 VCLEFT_rearRightOccupancyStatus 0;
BA_ "GenSigSNA" SG_ 1863 VCLEFT_rearRightOccupancyStatus "3";
BA_ "Confidence" SG_ 1863 VCLEFT_rearLeftBuckleStatus 0;
BA_ "GenSigSNA" SG_ 1863 VCLEFT_rearLeftBuckleStatus "3";
BA_ "Confidence" SG_ 1863 VCLEFT_rearCenterBuckleStatus 0;
BA_ "GenSigSNA" SG_ 1863 VCLEFT_rearCenterBuckleStatus "3";
BA_ "Confidence" SG_ 1863 VCLEFT_seatTrackPosition 0;
BA_ "GenSigSNA" SG_ 1863 VCLEFT_seatTrackPosition "7";
BA_ "Confidence" SG_ 1863 VCLEFT_restraintStatusCounter 0;
BA_ "Confidence" SG_ 1863 VCLEFT_restraintStatusChecksum 0;
BA_ "Confidence" SG_ 1250 VCLEFT_seatStatusIndex 1;
BA_ "Confidence" SG_ 1250 VCLEFT_frontSeatTrackPos 0;
BA_ "Confidence" SG_ 1250 VCLEFT_frontSeatTrackCurrent 0;
BA_ "Confidence" SG_ 1250 VCLEFT_frontSeatTrackDuty 0;
BA_ "Confidence" SG_ 1250 VCLEFT_frontSeatTrackState 0;
BA_ "Confidence" SG_ 1250 VCLEFT_frontSeatTrackCalibrated 0;
BA_ "Confidence" SG_ 1250 VCLEFT_frontSeatTrackLog 0;
BA_ "Confidence" SG_ 1250 VCLEFT_frontSeatTrackBridgeSt 0;
BA_ "Confidence" SG_ 1250 VCLEFT_frontSeatBackPos 0;
BA_ "Confidence" SG_ 1250 VCLEFT_frontSeatBackCurrent 0;
BA_ "Confidence" SG_ 1250 VCLEFT_frontSeatBackDuty 0;
BA_ "Confidence" SG_ 1250 VCLEFT_frontSeatBackState 0;
BA_ "Confidence" SG_ 1250 VCLEFT_frontSeatBackCalibrated 0;
BA_ "Confidence" SG_ 1250 VCLEFT_frontSeatBackLog 0;
BA_ "Confidence" SG_ 1250 VCLEFT_frontSeatBackBridgeSt 0;
BA_ "Confidence" SG_ 1250 VCLEFT_frontSeatLiftPos 0;
BA_ "Confidence" SG_ 1250 VCLEFT_frontSeatLiftCurrent 0;
BA_ "Confidence" SG_ 1250 VCLEFT_frontSeatLiftDuty 0;
BA_ "Confidence" SG_ 1250 VCLEFT_frontSeatLiftState 0;
BA_ "Confidence" SG_ 1250 VCLEFT_frontSeatLiftCalibrated 0;
BA_ "Confidence" SG_ 1250 VCLEFT_frontSeatLiftLog 0;
BA_ "Confidence" SG_ 1250 VCLEFT_frontSeatLiftBridgeSt 0;
BA_ "Confidence" SG_ 1250 VCLEFT_frontSeatTiltPos 0;
BA_ "Confidence" SG_ 1250 VCLEFT_frontSeatTiltCurrent 0;
BA_ "Confidence" SG_ 1250 VCLEFT_frontSeatTiltDuty 0;
BA_ "Confidence" SG_ 1250 VCLEFT_frontSeatTiltState 0;
BA_ "Confidence" SG_ 1250 VCLEFT_frontSeatTiltCalibrated 0;
BA_ "Confidence" SG_ 1250 VCLEFT_frontSeatTiltLog 0;
BA_ "Confidence" SG_ 1250 VCLEFT_frontSeatTiltBridgeSt 0;
BA_ "Confidence" SG_ 1250 VCLEFT_lumbarAState 0;
BA_ "Confidence" SG_ 1250 VCLEFT_lumbarBState 0;
BA_ "Confidence" SG_ 1250 VCLEFT_lumbarAPressureHpa 0;
BA_ "Confidence" SG_ 1250 VCLEFT_lumbarAPressureHpaFilt 0;
BA_ "Confidence" SG_ 1250 VCLEFT_lumbarBPressureHpa 0;
BA_ "Confidence" SG_ 1250 VCLEFT_lumbarBPressureHpaFilt 0;
BA_ "Confidence" SG_ 1250 VCLEFT_lumbarActiveTooLongErr 0;
BA_ "Confidence" SG_ 1250 VCLEFT_lumbarMaxPErr 0;
BA_ "Confidence" SG_ 1250 VCLEFT_lumbarOvercurrentErr 0;
BA_ "Confidence" SG_ 1250 VCLEFT_lumbarMaxOperatingPErr 0;
BA_ "Confidence" SG_ 1250 VCLEFT_lumbarMinPErr 0;
BA_ "Confidence" SG_ 1250 VCLEFT_lumbarGeneralErr 0;
BA_ "Confidence" SG_ 1250 VCLEFT_lumbarDevMaxPumpPressA 0;
BA_ "Confidence" SG_ 1250 VCLEFT_lumbarDevMaxPumpPressB 0;
BA_ "Confidence" SG_ 1250 VCLEFT_frontSeatTrackPosReal 0;
BA_ "Confidence" SG_ 1250 VCLEFT_frontSeatBackPosReal 0;
BA_ "Confidence" SG_ 1250 VCLEFT_frontSeatLiftPosReal 0;
BA_ "Confidence" SG_ 1250 VCLEFT_frontSeatTiltPosReal 0;
BA_ "Confidence" SG_ 1250 VCLEFT_frontSeatTrackPosOffset 0;
BA_ "Confidence" SG_ 1250 VCLEFT_frontSeatBackPosOffset 0;
BA_ "Confidence" SG_ 1250 VCLEFT_frontSeatLiftPosOffset 0;
BA_ "Confidence" SG_ 1250 VCLEFT_frontSeatTiltPosOffset 0;
BA_ "Confidence" SG_ 738 VCLEFT_seatStatus2Index 1;
BA_ "Confidence" SG_ 738 VCLEFT_frontSeatHeatCurrent 0;
BA_ "GenSigSNA" SG_ 738 VCLEFT_frontSeatHeatCurrent "12";
BA_ "Confidence" SG_ 738 VCLEFT_frontSeatHeatDuty 0;
BA_ "Confidence" SG_ 738 VCLEFT_frontSeatHeatTmp 0;
BA_ "Confidence" SG_ 738 VCLEFT_frontSeatHeatTmpTarget 0;
BA_ "Confidence" SG_ 738 VCLEFT_frontSeatHeatInhibited 0;
BA_ "Confidence" SG_ 738 VCLEFT_frontSeatHeatPowered 0;
BA_ "Confidence" SG_ 738 VCLEFT_2RowSeatReclineState 0;
BA_ "GenSigSNA" SG_ 738 VCLEFT_2RowSeatReclineState "15";
BA_ "Confidence" SG_ 738 VCLEFT_2RowSeatReclineDuty 0;
BA_ "Confidence" SG_ 738 VCLEFT_2RowSeatReclineCurrent 0;
BA_ "Confidence" SG_ 738 VCLEFT_2RowSeatReclineCalibrated 0;
BA_ "Confidence" SG_ 738 VCLEFT_2RowSeatReclinePositionRa 0;
BA_ "SystemSignalLongSymbol" SG_ 738 VCLEFT_2RowSeatReclinePositionRa "VCLEFT_2RowSeatReclinePositionRaw";
BA_ "Confidence" SG_ 738 VCLEFT_2RowSeatReclineAngle 0;
BA_ "Confidence" SG_ 738 VCLEFT_2RowSeatReclineAbsPosSwit 0;
BA_ "GenSigSNA" SG_ 738 VCLEFT_2RowSeatReclineAbsPosSwit "0";
BA_ "SystemSignalLongSymbol" SG_ 738 VCLEFT_2RowSeatReclineAbsPosSwit "VCLEFT_2RowSeatReclineAbsPosSwitchState";
BA_ "Confidence" SG_ 738 VCLEFT_2RowSeatReclinePositionSt 0;
BA_ "GenSigSNA" SG_ 738 VCLEFT_2RowSeatReclinePositionSt "4";
BA_ "SystemSignalLongSymbol" SG_ 738 VCLEFT_2RowSeatReclinePositionSt "VCLEFT_2RowSeatReclinePositionState";
BA_ "Confidence" SG_ 738 VCLEFT_2RowSeatReclineAdjustment 0;
BA_ "SystemSignalLongSymbol" SG_ 738 VCLEFT_2RowSeatReclineAdjustment "VCLEFT_2RowSeatReclineAdjustmentAllowed";
BA_ "Confidence" SG_ 738 VCLEFT_2RowSeatReclineFoldAllowe 0;
BA_ "SystemSignalLongSymbol" SG_ 738 VCLEFT_2RowSeatReclineFoldAllowe "VCLEFT_2RowSeatReclineFoldAllowed";
BA_ "Confidence" SG_ 738 VCLEFT_2RowSeatReclineUnfoldAllo 0;
BA_ "SystemSignalLongSymbol" SG_ 738 VCLEFT_2RowSeatReclineUnfoldAllo "VCLEFT_2RowSeatReclineUnfoldAllowed";
BA_ "Confidence" SG_ 738 VCLEFT_2RowSeatReclineNextToggle 0;
BA_ "GenSigSNA" SG_ 738 VCLEFT_2RowSeatReclineNextToggle "2";
BA_ "SystemSignalLongSymbol" SG_ 738 VCLEFT_2RowSeatReclineNextToggle "VCLEFT_2RowSeatReclineNextToggleDirection";
BA_ "Confidence" SG_ 738 VCLEFT_2RowSeatReclineChoreoBloc 0;
BA_ "SystemSignalLongSymbol" SG_ 738 VCLEFT_2RowSeatReclineChoreoBloc "VCLEFT_2RowSeatReclineChoreoBlockedByOccupancy";
BA_ "Confidence" SG_ 738 VCLEFT_2RowSeat1RClashAvoidanceB 0;
BA_ "SystemSignalLongSymbol" SG_ 738 VCLEFT_2RowSeat1RClashAvoidanceB "VCLEFT_2RowSeat1RClashAvoidanceBlockedReason";
BA_ "Confidence" SG_ 738 VCLEFT_2RowSeat1RClashAvoidanceS 0;
BA_ "SystemSignalLongSymbol" SG_ 738 VCLEFT_2RowSeat1RClashAvoidanceS "VCLEFT_2RowSeat1RClashAvoidanceState";
BA_ "Confidence" SG_ 738 VCLEFT_2RowSeatReclineAbsPo_0001 0;
BA_ "SystemSignalLongSymbol" SG_ 738 VCLEFT_2RowSeatReclineAbsPo_0001 "VCLEFT_2RowSeatReclineAbsPosSwitchTransPoint";
BA_ "Confidence" SG_ 930 VCLEFT_statusIndex 1;
BA_ "Confidence" SG_ 930 VCLEFT_securityControllerEnable 0;
BA_ "Confidence" SG_ 930 VCLEFT_securityControllerVoltage 0;
BA_ "Confidence" SG_ 930 VCLEFT_consoleDoorAssist 0;
BA_ "Confidence" SG_ 930 VCLEFT_OTAState 0;
BA_ "Confidence" SG_ 930 VCLEFT_5AVoltage 0;
BA_ "Confidence" SG_ 930 VCLEFT_vbatProt 0;
BA_ "Confidence" SG_ 930 VCLEFT_footwellLightCurrent 0;
BA_ "Confidence" SG_ 930 VCLEFT_swcInputVoltage 0;
BA_ "GenSigSNA" SG_ 930 VCLEFT_swcInputVoltage "255";
BA_ "Confidence" SG_ 930 VCLEFT_swcPCBATemperature 0;
BA_ "GenSigSNA" SG_ 930 VCLEFT_swcPCBATemperature "128";
BA_ "Confidence" SG_ 930 VCLEFT_obdEthernetActive 0;
BA_ "Confidence" SG_ 930 VCLEFT_rationalityAggregateCurre 0;
BA_ "SystemSignalLongSymbol" SG_ 930 VCLEFT_rationalityAggregateCurre "VCLEFT_rationalityAggregateCurrent";
BA_ "Confidence" SG_ 930 VCLEFT_LVBatteryTypeDBG 0;
BA_ "Confidence" SG_ 930 VCLEFT_DIeFuseFault 0;
BA_ "Confidence" SG_ 930 VCLEFT_eFuseMgmtVoltageMonitor 0;
BA_ "Confidence" SG_ 930 VCLEFT_trailerAuxCurrent 0;
BA_ "GenSigSNA" SG_ 930 VCLEFT_trailerAuxCurrent "4095";
BA_ "Confidence" SG_ 930 VCLEFT_swcHeatTmp 0;
BA_ "GenSigSNA" SG_ 930 VCLEFT_swcHeatTmp "1023";
BA_ "Confidence" SG_ 930 VCLEFT_swcHeatStatus 0;
BA_ "GenSigSNA" SG_ 930 VCLEFT_swcHeatStatus "0";
BA_ "Confidence" SG_ 930 VCLEFT_swcHeatInhibited 0;
BA_ "Confidence" SG_ 930 VCLEFT_pcbaTemperature 0;
BA_ "Confidence" SG_ 930 VCLEFT_swcHeatPwr 0;
BA_ "GenSigSNA" SG_ 930 VCLEFT_swcHeatPwr "511";
BA_ "Confidence" SG_ 930 VCLEFT_swcHeatDutyCycle 0;
BA_ "GenSigSNA" SG_ 930 VCLEFT_swcHeatDutyCycle "127";
BA_ "Confidence" SG_ 930 VCLEFT_DIeFuseCurrent 0;
BA_ "Confidence" SG_ 930 VCLEFT_SWCpresent 0;
BA_ "Confidence" SG_ 962 VCLEFT_switchStatusIndex 1;
BA_ "Confidence" SG_ 962 VCLEFT_hornSwitchPressed 0;
BA_ "Confidence" SG_ 962 VCLEFT_hazardButtonPressed 0;
BA_ "Confidence" SG_ 962 VCLEFT_brakeSwitchPressed 0;
BA_ "Confidence" SG_ 962 VCLEFT_rightMirrorTilt 0;
BA_ "Confidence" SG_ 962 VCLEFT_frontSeatTrackBack 0;
BA_ "GenSigSNA" SG_ 962 VCLEFT_frontSeatTrackBack "0";
BA_ "Confidence" SG_ 962 VCLEFT_frontSeatTrackForward 0;
BA_ "GenSigSNA" SG_ 962 VCLEFT_frontSeatTrackForward "0";
BA_ "Confidence" SG_ 962 VCLEFT_frontSeatTiltDown 0;
BA_ "GenSigSNA" SG_ 962 VCLEFT_frontSeatTiltDown "0";
BA_ "Confidence" SG_ 962 VCLEFT_frontSeatTiltUp 0;
BA_ "GenSigSNA" SG_ 962 VCLEFT_frontSeatTiltUp "0";
BA_ "Confidence" SG_ 962 VCLEFT_frontSeatLiftDown 0;
BA_ "GenSigSNA" SG_ 962 VCLEFT_frontSeatLiftDown "0";
BA_ "Confidence" SG_ 962 VCLEFT_frontSeatLiftUp 0;
BA_ "GenSigSNA" SG_ 962 VCLEFT_frontSeatLiftUp "0";
BA_ "Confidence" SG_ 962 VCLEFT_frontSeatBackrestBack 0;
BA_ "GenSigSNA" SG_ 962 VCLEFT_frontSeatBackrestBack "0";
BA_ "Confidence" SG_ 962 VCLEFT_frontSeatBackrestForward 0;
BA_ "GenSigSNA" SG_ 962 VCLEFT_frontSeatBackrestForward "0";
BA_ "Confidence" SG_ 962 VCLEFT_frontSeatLumbarDown 0;
BA_ "GenSigSNA" SG_ 962 VCLEFT_frontSeatLumbarDown "0";
BA_ "Confidence" SG_ 962 VCLEFT_frontSeatLumbarUp 0;
BA_ "GenSigSNA" SG_ 962 VCLEFT_frontSeatLumbarUp "0";
BA_ "Confidence" SG_ 962 VCLEFT_frontSeatLumbarIn 0;
BA_ "GenSigSNA" SG_ 962 VCLEFT_frontSeatLumbarIn "0";
BA_ "Confidence" SG_ 962 VCLEFT_frontSeatLumbarOut 0;
BA_ "GenSigSNA" SG_ 962 VCLEFT_frontSeatLumbarOut "0";
BA_ "Confidence" SG_ 962 VCLEFT_btnWindowSwPackUpLF 0;
BA_ "Confidence" SG_ 962 VCLEFT_btnWindowSwPackAutoUpLF 0;
BA_ "Confidence" SG_ 962 VCLEFT_btnWindowSwPackDownLF 0;
BA_ "Confidence" SG_ 962 VCLEFT_btnWindowSwPackAutoDownLF 0;
BA_ "Confidence" SG_ 962 VCLEFT_btnWindowSwPackUpLR 0;
BA_ "Confidence" SG_ 962 VCLEFT_btnWindowSwPackAutoUpLR 0;
BA_ "Confidence" SG_ 962 VCLEFT_btnWindowSwPackDownLR 0;
BA_ "Confidence" SG_ 962 VCLEFT_btnWindowSwPackAutoDownLR 0;
BA_ "Confidence" SG_ 962 VCLEFT_btnWindowSwPackUpRF 0;
BA_ "Confidence" SG_ 962 VCLEFT_btnWindowSwPackAutoUpRF 0;
BA_ "Confidence" SG_ 962 VCLEFT_btnWindowSwPackDownRF 0;
BA_ "Confidence" SG_ 962 VCLEFT_btnWindowSwPackAutoDownRF 0;
BA_ "Confidence" SG_ 962 VCLEFT_btnWindowSwPackUpRR 0;
BA_ "Confidence" SG_ 962 VCLEFT_btnWindowSwPackAutoUpRR 0;
BA_ "Confidence" SG_ 962 VCLEFT_btnWindowSwPackDownRR 0;
BA_ "Confidence" SG_ 962 VCLEFT_btnWindowSwPackAutoDownRR 0;
BA_ "Confidence" SG_ 962 VCLEFT_frontBuckleSwitch 0;
BA_ "GenSigSNA" SG_ 962 VCLEFT_frontBuckleSwitch "0";
BA_ "Confidence" SG_ 962 VCLEFT_frontOccupancySwitch 0;
BA_ "GenSigSNA" SG_ 962 VCLEFT_frontOccupancySwitch "0";
BA_ "Confidence" SG_ 962 VCLEFT_rearLeftBuckleSwitch 0;
BA_ "GenSigSNA" SG_ 962 VCLEFT_rearLeftBuckleSwitch "0";
BA_ "Confidence" SG_ 962 VCLEFT_rearCenterOccupancySwitch 0;
BA_ "GenSigSNA" SG_ 962 VCLEFT_rearCenterOccupancySwitch "0";
BA_ "Confidence" SG_ 962 VCLEFT_rearLeftOccupancySwitch 0;
BA_ "GenSigSNA" SG_ 962 VCLEFT_rearLeftOccupancySwitch "0";
BA_ "Confidence" SG_ 962 VCLEFT_rearRightOccupancySwitch 0;
BA_ "GenSigSNA" SG_ 962 VCLEFT_rearRightOccupancySwitch "0";
BA_ "Confidence" SG_ 962 VCLEFT_brakePressed 0;
BA_ "Confidence" SG_ 962 VCLEFT_rearHVACButtonPressed 0;
BA_ "Confidence" SG_ 962 VCLEFT_rearCenterBuckleSwitch 0;
BA_ "GenSigSNA" SG_ 962 VCLEFT_rearCenterBuckleSwitch "0";
BA_ "Confidence" SG_ 962 VCLEFT_isAlcoholInterlockSet 0;
BA_ "Confidence" SG_ 962 VCLEFT_swcLeftTiltRight 0;
BA_ "GenSigSNA" SG_ 962 VCLEFT_swcLeftTiltRight "0";
BA_ "Confidence" SG_ 962 VCLEFT_swcLeftPressed 0;
BA_ "GenSigSNA" SG_ 962 VCLEFT_swcLeftPressed "0";
BA_ "Confidence" SG_ 962 VCLEFT_swcRightTiltLeft 0;
BA_ "GenSigSNA" SG_ 962 VCLEFT_swcRightTiltLeft "0";
BA_ "Confidence" SG_ 962 VCLEFT_swcRightTiltRight 0;
BA_ "GenSigSNA" SG_ 962 VCLEFT_swcRightTiltRight "0";
BA_ "Confidence" SG_ 962 VCLEFT_swcRightPressed 0;
BA_ "GenSigSNA" SG_ 962 VCLEFT_swcRightPressed "0";
BA_ "Confidence" SG_ 962 VCLEFT_swcLeftTiltLeft 0;
BA_ "GenSigSNA" SG_ 962 VCLEFT_swcLeftTiltLeft "0";
BA_ "Confidence" SG_ 962 VCLEFT_swcLeftScrollTicks 0;
BA_ "Confidence" SG_ 962 VCLEFT_swcWiperButtonState 0;
BA_ "Confidence" SG_ 962 VCLEFT_swcRightScrollTicks 0;
BA_ "Confidence" SG_ 962 VCLEFT_swcTurnSignalLeftButtonSt 0;
BA_ "SystemSignalLongSymbol" SG_ 962 VCLEFT_swcTurnSignalLeftButtonSt "VCLEFT_swcTurnSignalLeftButtonState";
BA_ "Confidence" SG_ 962 VCLEFT_btnWindowUpLR 0;
BA_ "Confidence" SG_ 962 VCLEFT_btnWindowAutoUpLR 0;
BA_ "Confidence" SG_ 962 VCLEFT_btnWindowDownLR 0;
BA_ "Confidence" SG_ 962 VCLEFT_btnWindowAutoDownLR 0;
BA_ "Confidence" SG_ 962 VCLEFT_2RowSeatLeftFoldFlatSwitc 0;
BA_ "SystemSignalLongSymbol" SG_ 962 VCLEFT_2RowSeatLeftFoldFlatSwitc "VCLEFT_2RowSeatLeftFoldFlatSwitch";
BA_ "Confidence" SG_ 962 VCLEFT_2RowSeatRightFoldFlatSwit 0;
BA_ "SystemSignalLongSymbol" SG_ 962 VCLEFT_2RowSeatRightFoldFlatSwit "VCLEFT_2RowSeatRightFoldFlatSwitch";
BA_ "Confidence" SG_ 962 VCLEFT_2RowSeatBothFoldFlatSwitc 0;
BA_ "SystemSignalLongSymbol" SG_ 962 VCLEFT_2RowSeatBothFoldFlatSwitc "VCLEFT_2RowSeatBothFoldFlatSwitch";
BA_ "Confidence" SG_ 962 VCLEFT_swcLeftDoublePress 0;
BA_ "Confidence" SG_ 962 VCLEFT_swcRightDoublePress 0;
BA_ "Confidence" SG_ 962 VCLEFT_swcTurnSignalRightButtonS 0;
BA_ "SystemSignalLongSymbol" SG_ 962 VCLEFT_swcTurnSignalRightButtonS "VCLEFT_swcTurnSignalRightButtonState";
BA_ "Confidence" SG_ 962 VCLEFT_swcHighBeamButtonState 0;
BA_ "Confidence" SG_ 962 VCLEFT_swcVoiceControlPress 0;
BA_ "GenSigSNA" SG_ 962 VCLEFT_swcVoiceControlPress "0";
BA_ "Confidence" SG_ 962 VCLEFT_swcCameraButtonState 0;
BA_ "Confidence" SG_ 962 VCLEFT_swcRightPressedQF 0;
BA_ "Confidence" SG_ 962 VCLEFT_frontSeatResistiveOccupan 0;
BA_ "GenSigSNA" SG_ 962 VCLEFT_frontSeatResistiveOccupan "0";
BA_ "SystemSignalLongSymbol" SG_ 962 VCLEFT_frontSeatResistiveOccupan "VCLEFT_frontSeatResistiveOccupancy";
BA_ "Confidence" SG_ 656 VCLEFT_thermalLogging10HzIndex 1;
BA_ "Confidence" SG_ 656 VCLEFT_hvac2RLeftLateralVoltage 0;
BA_ "Confidence" SG_ 656 VCLEFT_hvac2RLeftVerticalVoltage 0;
BA_ "Confidence" SG_ 656 VCLEFT_hvac2RRightLateralVoltage 0;
BA_ "Confidence" SG_ 656 VCLEFT_hvac2RRightVerticalVoltag 0;
BA_ "SystemSignalLongSymbol" SG_ 656 VCLEFT_hvac2RRightVerticalVoltag "VCLEFT_hvac2RRightVerticalVoltage";
BA_ "Confidence" SG_ 656 VCLEFT_hvac2RLeftLateralCalibrat 0;
BA_ "SystemSignalLongSymbol" SG_ 656 VCLEFT_hvac2RLeftLateralCalibrat "VCLEFT_hvac2RLeftLateralCalibrated";
BA_ "Confidence" SG_ 656 VCLEFT_hvac2RLeftVerticalCalibra 0;
BA_ "SystemSignalLongSymbol" SG_ 656 VCLEFT_hvac2RLeftVerticalCalibra "VCLEFT_hvac2RLeftVerticalCalibrated";
BA_ "Confidence" SG_ 656 VCLEFT_hvac2RRightLateralCalibra 0;
BA_ "SystemSignalLongSymbol" SG_ 656 VCLEFT_hvac2RRightLateralCalibra "VCLEFT_hvac2RRightLateralCalibrated";
BA_ "Confidence" SG_ 656 VCLEFT_hvac2RRightVerticalCalibr 0;
BA_ "SystemSignalLongSymbol" SG_ 656 VCLEFT_hvac2RRightVerticalCalibr "VCLEFT_hvac2RRightVerticalCalibrated";
BA_ "Confidence" SG_ 656 VCLEFT_hvac2RLeftLateralState 0;
BA_ "Confidence" SG_ 656 VCLEFT_hvac2RLeftVerticalState 0;
BA_ "Confidence" SG_ 656 VCLEFT_hvac2RRightLateralState 0;
BA_ "Confidence" SG_ 656 VCLEFT_hvac2RRightVerticalState 0;
BA_ "Confidence" SG_ 656 VCLEFT_hvacBlowerWindmillElecRpm 1;
BA_ "Confidence" SG_ 656 VCLEFT_hvac2RRightVerticalVeloci 1;
BA_ "SystemSignalLongSymbol" SG_ 656 VCLEFT_hvac2RRightVerticalVeloci "VCLEFT_hvac2RRightVerticalVelocity";
BA_ "Confidence" SG_ 656 VCLEFT_hvacBlowerWindmillBemf 1;
BA_ "Confidence" SG_ 656 VCLEFT_hvac2RLeftVerticalVelocit 1;
BA_ "SystemSignalLongSymbol" SG_ 656 VCLEFT_hvac2RLeftVerticalVelocit "VCLEFT_hvac2RLeftVerticalVelocity";
BA_ "Confidence" SG_ 656 VCLEFT_hvac2RLeftLateralVelocity 1;
BA_ "Confidence" SG_ 656 VCLEFT_vcusbLinSchedule 1;
BA_ "Confidence" SG_ 656 VCLEFT_hvac2RLeftLateralDuty 0;
BA_ "Confidence" SG_ 656 VCLEFT_hvac2RLeftVerticalDuty 0;
BA_ "Confidence" SG_ 656 VCLEFT_hvac2RRightLateralDuty 0;
BA_ "Confidence" SG_ 656 VCLEFT_hvac2RRightVerticalDuty 0;
BA_ "Confidence" SG_ 656 VCLEFT_hvacBlowerWindmilling 0;
BA_ "Confidence" SG_ 656 VCLEFT_hvac2RRightLateralVelocit 0;
BA_ "SystemSignalLongSymbol" SG_ 656 VCLEFT_hvac2RRightLateralVelocit "VCLEFT_hvac2RRightLateralVelocity";
BA_ "Confidence" SG_ 656 VCLEFT_hvacBlower1msOverrunFrequ 0;
BA_ "SystemSignalLongSymbol" SG_ 656 VCLEFT_hvacBlower1msOverrunFrequ "VCLEFT_hvacBlower1msOverrunFrequency";
BA_ "Confidence" SG_ 656 VCLEFT_hvacBlower10msOverrunFreq 0;
BA_ "SystemSignalLongSymbol" SG_ 656 VCLEFT_hvacBlower10msOverrunFreq "VCLEFT_hvacBlower10msOverrunFrequency";
BA_ "Confidence" SG_ 657 VCLEFT_thermalLogging1HzIndex 1;
BA_ "Confidence" SG_ 657 VCLEFT_hvac2RLeftLateralZeroStop 0;
BA_ "SystemSignalLongSymbol" SG_ 657 VCLEFT_hvac2RLeftLateralZeroStop "VCLEFT_hvac2RLeftLateralZeroStopVoltage";
BA_ "Confidence" SG_ 657 VCLEFT_hvac2RLeftVerticalZeroSto 0;
BA_ "SystemSignalLongSymbol" SG_ 657 VCLEFT_hvac2RLeftVerticalZeroSto "VCLEFT_hvac2RLeftVerticalZeroStopVoltage";
BA_ "Confidence" SG_ 657 VCLEFT_hvac2RRightLateralZeroSto 0;
BA_ "SystemSignalLongSymbol" SG_ 657 VCLEFT_hvac2RRightLateralZeroSto "VCLEFT_hvac2RRightLateralZeroStopVoltage";
BA_ "Confidence" SG_ 657 VCLEFT_hvac2RRightVerticalZeroSt 0;
BA_ "SystemSignalLongSymbol" SG_ 657 VCLEFT_hvac2RRightVerticalZeroSt "VCLEFT_hvac2RRightVerticalZeroStopVoltage";
BA_ "Confidence" SG_ 657 VCLEFT_hvac2RLeftLateralEndStopV 0;
BA_ "SystemSignalLongSymbol" SG_ 657 VCLEFT_hvac2RLeftLateralEndStopV "VCLEFT_hvac2RLeftLateralEndStopVoltage";
BA_ "Confidence" SG_ 657 VCLEFT_hvac2RLeftVerticalEndStop 0;
BA_ "SystemSignalLongSymbol" SG_ 657 VCLEFT_hvac2RLeftVerticalEndStop "VCLEFT_hvac2RLeftVerticalEndStopVoltage";
BA_ "Confidence" SG_ 657 VCLEFT_hvac2RRightLateralEndStop 0;
BA_ "SystemSignalLongSymbol" SG_ 657 VCLEFT_hvac2RRightLateralEndStop "VCLEFT_hvac2RRightLateralEndStopVoltage";
BA_ "Confidence" SG_ 657 VCLEFT_hvac2RRightVerticalEndSto 0;
BA_ "SystemSignalLongSymbol" SG_ 657 VCLEFT_hvac2RRightVerticalEndSto "VCLEFT_hvac2RRightVerticalEndStopVoltage";
BA_ "Confidence" SG_ 657 VCLEFT_hvacBlowerArbState 1;
BA_ "Confidence" SG_ 657 VCLEFT_hvacBlowerArbResult 1;
BA_ "Confidence" SG_ 657 VCLEFT_hvacBlowerArbCurrent 1;
BA_ "Confidence" SG_ 657 VCLEFT_hvacBlowerTorqueIndexFilt 1;
BA_ "SystemSignalLongSymbol" SG_ 657 VCLEFT_hvacBlowerTorqueIndexFilt "VCLEFT_hvacBlowerTorqueIndexFiltered";
BA_ "Confidence" SG_ 549 VCRIGHT_ptcLVState 0;
BA_ "Confidence" SG_ 549 VCRIGHT_ocsLVState 0;
BA_ "Confidence" SG_ 549 VCRIGHT_premAudioLVState 0;
BA_ "Confidence" SG_ 549 VCRIGHT_rearOilPumpLVState 0;
BA_ "Confidence" SG_ 549 VCRIGHT_tunerLVState 0;
BA_ "Confidence" SG_ 549 VCRIGHT_hvcLVState 0;
BA_ "Confidence" SG_ 549 VCRIGHT_rcmLVState 0;
BA_ "Confidence" SG_ 549 VCRIGHT_lumbarLVState 0;
BA_ "Confidence" SG_ 549 VCRIGHT_cntctrPwrState 0;
BA_ "Confidence" SG_ 549 VCRIGHT_eFuseLockoutStatus 0;
BA_ "Confidence" SG_ 549 VCRIGHT_swEnStatus 0;
BA_ "Confidence" SG_ 549 VCRIGHT_vehiclePowerStateDBG 0;
BA_ "Confidence" SG_ 549 VCRIGHT_parkLVState 0;
BA_ "Confidence" SG_ 549 VCRIGHT_icrLVState 0;
BA_ "Confidence" SG_ 549 VCRIGHT_interiorCameraLedLVState 0;
BA_ "Confidence" SG_ 549 VCRIGHT_diLVState 0;
BA_ "Confidence" SG_ 1795 VCRIGHT_debugThermal10HzIndex 1;
BA_ "Confidence" SG_ 1795 VCRIGHT_hvacPanelFloorSplitRow1 0;
BA_ "Confidence" SG_ 1795 VCRIGHT_hvacDefrostPercent 0;
BA_ "Confidence" SG_ 1795 VCRIGHT_hvacRow2Percent 0;
BA_ "Confidence" SG_ 1795 VCRIGHT_hvacPanelFloorSplitRow2 0;
BA_ "Confidence" SG_ 1795 VCRIGHT_hvacFreshMassCounter 0;
BA_ "Confidence" SG_ 1795 VCRIGHT_hvacRecircMassCounter 0;
BA_ "Confidence" SG_ 1795 VCRIGHT_setTempAdjustmentLeft 0;
BA_ "GenSigSNA" SG_ 1795 VCRIGHT_setTempAdjustmentLeft "127";
BA_ "Confidence" SG_ 1795 VCRIGHT_setTempAdjustmentRight 0;
BA_ "GenSigSNA" SG_ 1795 VCRIGHT_setTempAdjustmentRight "127";
BA_ "Confidence" SG_ 1795 VCRIGHT_hvacLHVaneVelocity 0;
BA_ "Confidence" SG_ 1795 VCRIGHT_hvacRHVaneVelocity 0;
BA_ "Confidence" SG_ 1795 VCRIGHT_hvacMassflowCompensated 0;
BA_ "Confidence" SG_ 1795 VCRIGHT_PTCcenterPowerLeft 0;
BA_ "GenSigSNA" SG_ 1795 VCRIGHT_PTCcenterPowerLeft "63";
BA_ "Confidence" SG_ 1795 VCRIGHT_PTCouterPowerLeft 0;
BA_ "GenSigSNA" SG_ 1795 VCRIGHT_PTCouterPowerLeft "63";
BA_ "Confidence" SG_ 1795 VCRIGHT_PTCinnerPowerLeft 0;
BA_ "GenSigSNA" SG_ 1795 VCRIGHT_PTCinnerPowerLeft "63";
BA_ "Confidence" SG_ 1795 VCRIGHT_PTCcenterPowerRight 0;
BA_ "GenSigSNA" SG_ 1795 VCRIGHT_PTCcenterPowerRight "63";
BA_ "Confidence" SG_ 1795 VCRIGHT_PTCouterPowerRight 0;
BA_ "GenSigSNA" SG_ 1795 VCRIGHT_PTCouterPowerRight "63";
BA_ "Confidence" SG_ 1795 VCRIGHT_PTCinnerPowerRight 0;
BA_ "GenSigSNA" SG_ 1795 VCRIGHT_PTCinnerPowerRight "63";
BA_ "Confidence" SG_ 1795 VCRIGHT_PTCcenterStoneTempLeft 0;
BA_ "GenSigSNA" SG_ 1795 VCRIGHT_PTCcenterStoneTempLeft "255";
BA_ "Confidence" SG_ 1795 VCRIGHT_PTCcenterStoneTempRight 0;
BA_ "GenSigSNA" SG_ 1795 VCRIGHT_PTCcenterStoneTempRight "255";
BA_ "Confidence" SG_ 1795 VCRIGHT_PTCinnerStoneTempLeft 0;
BA_ "GenSigSNA" SG_ 1795 VCRIGHT_PTCinnerStoneTempLeft "255";
BA_ "Confidence" SG_ 1795 VCRIGHT_PTCinnerStoneTempRight 0;
BA_ "GenSigSNA" SG_ 1795 VCRIGHT_PTCinnerStoneTempRight "255";
BA_ "Confidence" SG_ 1795 VCRIGHT_PTCouterStoneTempLeft 0;
BA_ "GenSigSNA" SG_ 1795 VCRIGHT_PTCouterStoneTempLeft "255";
BA_ "Confidence" SG_ 1795 VCRIGHT_PTCouterRodTempLeft 0;
BA_ "GenSigSNA" SG_ 1795 VCRIGHT_PTCouterRodTempLeft "255";
BA_ "Confidence" SG_ 1795 VCRIGHT_PTCouterAirTempLeft 0;
BA_ "GenSigSNA" SG_ 1795 VCRIGHT_PTCouterAirTempLeft "255";
BA_ "Confidence" SG_ 1795 VCRIGHT_PTCcenterRodTempLeft 0;
BA_ "GenSigSNA" SG_ 1795 VCRIGHT_PTCcenterRodTempLeft "255";
BA_ "Confidence" SG_ 1795 VCRIGHT_PTCinnerRodTempLeft 0;
BA_ "GenSigSNA" SG_ 1795 VCRIGHT_PTCinnerRodTempLeft "255";
BA_ "Confidence" SG_ 1795 VCRIGHT_PTCcenterAirTempLeft 0;
BA_ "GenSigSNA" SG_ 1795 VCRIGHT_PTCcenterAirTempLeft "255";
BA_ "Confidence" SG_ 1795 VCRIGHT_PTCinnerAirTempLeft 0;
BA_ "GenSigSNA" SG_ 1795 VCRIGHT_PTCinnerAirTempLeft "255";
BA_ "Confidence" SG_ 1795 VCRIGHT_PTCouterStoneTempRight 0;
BA_ "GenSigSNA" SG_ 1795 VCRIGHT_PTCouterStoneTempRight "255";
BA_ "Confidence" SG_ 1795 VCRIGHT_PTCouterRodTempRight 0;
BA_ "GenSigSNA" SG_ 1795 VCRIGHT_PTCouterRodTempRight "255";
BA_ "Confidence" SG_ 1795 VCRIGHT_PTCouterAirTempRight 0;
BA_ "GenSigSNA" SG_ 1795 VCRIGHT_PTCouterAirTempRight "255";
BA_ "Confidence" SG_ 1795 VCRIGHT_PTCcenterRodTempRight 0;
BA_ "GenSigSNA" SG_ 1795 VCRIGHT_PTCcenterRodTempRight "255";
BA_ "Confidence" SG_ 1795 VCRIGHT_PTCinnerRodTempRight 0;
BA_ "GenSigSNA" SG_ 1795 VCRIGHT_PTCinnerRodTempRight "255";
BA_ "Confidence" SG_ 1795 VCRIGHT_PTCcenterAirTempRight 0;
BA_ "GenSigSNA" SG_ 1795 VCRIGHT_PTCcenterAirTempRight "255";
BA_ "Confidence" SG_ 1795 VCRIGHT_PTCinnerAirTempRight 0;
BA_ "GenSigSNA" SG_ 1795 VCRIGHT_PTCinnerAirTempRight "255";
BA_ "Confidence" SG_ 259 VCRIGHT_doorClosureStatusFront 0;
BA_ "GenSigSNA" SG_ 259 VCRIGHT_doorClosureStatusFront "0";
BA_ "Confidence" SG_ 259 VCRIGHT_doorClosureStatusRear 0;
BA_ "GenSigSNA" SG_ 259 VCRIGHT_doorClosureStatusRear "0";
BA_ "Confidence" SG_ 259 VCRIGHT_frontLatchSwitch 0;
BA_ "Confidence" SG_ 259 VCRIGHT_rearLatchSwitch 0;
BA_ "Confidence" SG_ 259 VCRIGHT_frontHandlePulled 0;
BA_ "Confidence" SG_ 259 VCRIGHT_rearHandlePulled 0;
BA_ "Confidence" SG_ 259 VCRIGHT_frontRelActuatorSwitch 0;
BA_ "Confidence" SG_ 259 VCRIGHT_rearRelActuatorSwitch 0;
BA_ "Confidence" SG_ 259 VCRIGHT_frontLatchStatus 0;
BA_ "GenSigSNA" SG_ 259 VCRIGHT_frontLatchStatus "0";
BA_ "Confidence" SG_ 259 VCRIGHT_rearLatchStatus 0;
BA_ "GenSigSNA" SG_ 259 VCRIGHT_rearLatchStatus "0";
BA_ "Confidence" SG_ 259 VCRIGHT_lastDoorReqSourceFront 0;
BA_ "Confidence" SG_ 259 VCRIGHT_lastDoorReqSourceRear 0;
BA_ "Confidence" SG_ 259 VCRIGHT_frontHandlePulledPersist 0;
BA_ "Confidence" SG_ 259 VCRIGHT_frontIntSwitchPressed 0;
BA_ "Confidence" SG_ 259 VCRIGHT_rearIntSwitchPressed 0;
BA_ "Confidence" SG_ 259 VCRIGHT_mirrorTiltXPosition 0;
BA_ "Confidence" SG_ 259 VCRIGHT_mirrorTiltYPosition 0;
BA_ "Confidence" SG_ 259 VCRIGHT_mirrorState 0;
BA_ "Confidence" SG_ 259 VCRIGHT_mirrorFoldState 0;
BA_ "Confidence" SG_ 259 VCRIGHT_mirrorDipped 0;
BA_ "Confidence" SG_ 259 VCRIGHT_trunkLatchStatus 0;
BA_ "GenSigSNA" SG_ 259 VCRIGHT_trunkLatchStatus "0";
BA_ "Confidence" SG_ 259 VCRIGHT_mirrorRecallState 0;
BA_ "Confidence" SG_ 259 VCRIGHT_rearHandlePulledPersist 0;
BA_ "Confidence" SG_ 915 VCRIGHT_epbmDebugIndex 1;
BA_ "Confidence" SG_ 915 VCRIGHT_epbmCaliperState 0;
BA_ "Confidence" SG_ 915 VCRIGHT_epbmMotorEnabled 0;
BA_ "Confidence" SG_ 915 VCRIGHT_epbMotorCurrent 0;
BA_ "Confidence" SG_ 915 VCRIGHT_epbmApplyVoltage 0;
BA_ "Confidence" SG_ 915 VCRIGHT_epbmReleaseVoltage 0;
BA_ "Confidence" SG_ 915 VCRIGHT_summonFaultReason 1;
BA_ "Confidence" SG_ 915 VCRIGHT_epbSummonState 1;
BA_ "Confidence" SG_ 915 VCRIGHT_epbmSummonState 1;
BA_ "Confidence" SG_ 915 VCRIGHT_epbUnitStatus 1;
BA_ "Confidence" SG_ 915 VCRIGHT_epbmFaultStatus 1;
BA_ "Confidence" SG_ 915 VCRIGHT_epbFaultStatus 1;
BA_ "Confidence" SG_ 915 VCRIGHT_epbmSystemStatus 1;
BA_ "Confidence" SG_ 1123 VCRIGHT_cdpRequestState 0;
BA_ "Confidence" SG_ 1123 VCRIGHT_epbmSystemStatusQF 0;
BA_ "Confidence" SG_ 1123 VCRIGHT_epbmUnitStatus 0;
BA_ "Confidence" SG_ 1123 VCRIGHT_epbmCdpState 0;
BA_ "Confidence" SG_ 1123 VCRIGHT_epbmStatusCounter 0;
BA_ "Confidence" SG_ 1123 VCRIGHT_epbmStatusChecksum 0;
BA_ "Confidence" SG_ 579 VCRIGHT_hvacStatusIndex 1;
BA_ "Confidence" SG_ 579 VCRIGHT_childModeHVACState 0;
BA_ "Confidence" SG_ 579 VCRIGHT_dogModeState 0;
BA_ "Confidence" SG_ 579 VCRIGHT_hvacCabinTempEstValid 0;
BA_ "Confidence" SG_ 579 VCRIGHT_COPNotRunningReasonFilte 0;
BA_ "SystemSignalLongSymbol" SG_ 579 VCRIGHT_COPNotRunningReasonFilte "VCRIGHT_COPNotRunningReasonFiltered";
BA_ "Confidence" SG_ 579 VCRIGHT_hvacCabinTempEst 0;
BA_ "Confidence" SG_ 579 VCRIGHT_hvacAirDistributionMode 0;
BA_ "Confidence" SG_ 579 VCRIGHT_hvacBlowerSegment 0;
BA_ "Confidence" SG_ 579 VCRIGHT_hvacRecirc 0;
BA_ "Confidence" SG_ 579 VCRIGHT_hvacACRunning 0;
BA_ "Confidence" SG_ 579 VCRIGHT_hvacPowerState 0;
BA_ "Confidence" SG_ 579 VCRIGHT_hvacVentStatus 0;
BA_ "Confidence" SG_ 579 VCRIGHT_hvacSecondRowState 0;
BA_ "Confidence" SG_ 579 VCRIGHT_hvacSystemNominal 0;
BA_ "Confidence" SG_ 579 VCRIGHT_hvacModelInitStatus 0;
BA_ "Confidence" SG_ 579 VCRIGHT_hvacMassflowRefrigSysRig 0;
BA_ "SystemSignalLongSymbol" SG_ 579 VCRIGHT_hvacMassflowRefrigSysRig "VCRIGHT_hvacMassflowRefrigSysRight";
BA_ "Confidence" SG_ 579 VCRIGHT_hvacRecircDoorPercent 0;
BA_ "Confidence" SG_ 579 VCRIGHT_tempDuctLeft 0;
BA_ "GenSigSNA" SG_ 579 VCRIGHT_tempDuctLeft "255";
BA_ "Confidence" SG_ 579 VCRIGHT_hvacMassflowRefrigSystem 0;
BA_ "Confidence" SG_ 579 VCRIGHT_tempDuctRight 0;
BA_ "GenSigSNA" SG_ 579 VCRIGHT_tempDuctRight "255";
BA_ "Confidence" SG_ 579 VCRIGHT_hvacMassflowRefrigSysLef 0;
BA_ "SystemSignalLongSymbol" SG_ 579 VCRIGHT_hvacMassflowRefrigSysLef "VCRIGHT_hvacMassflowRefrigSysLeft";
BA_ "Confidence" SG_ 579 VCRIGHT_hvacDuctTargetLeft 0;
BA_ "GenSigSNA" SG_ 579 VCRIGHT_hvacDuctTargetLeft "255";
BA_ "Confidence" SG_ 579 VCRIGHT_hvacDuctTargetRight 0;
BA_ "GenSigSNA" SG_ 579 VCRIGHT_hvacDuctTargetRight "255";
BA_ "Confidence" SG_ 579 VCRIGHT_enableTripleCameraFanPow 0;
BA_ "SystemSignalLongSymbol" SG_ 579 VCRIGHT_enableTripleCameraFanPow "VCRIGHT_enableTripleCameraFanPowerInSleep";
BA_ "Confidence" SG_ 579 VCRIGHT_tempDuctRightUpper 0;
BA_ "GenSigSNA" SG_ 579 VCRIGHT_tempDuctRightUpper "255";
BA_ "Confidence" SG_ 579 VCRIGHT_hpSplitTempsEnabled 0;
BA_ "Confidence" SG_ 579 VCRIGHT_hvacEvapInletTempEstimat 0;
BA_ "GenSigSNA" SG_ 579 VCRIGHT_hvacEvapInletTempEstimat "1023";
BA_ "SystemSignalLongSymbol" SG_ 579 VCRIGHT_hvacEvapInletTempEstimat "VCRIGHT_hvacEvapInletTempEstimate";
BA_ "Confidence" SG_ 579 VCRIGHT_tempMonitorNotNominal 0;
BA_ "Confidence" SG_ 579 VCRIGHT_hvacCabinAtTempTarget 0;
BA_ "Confidence" SG_ 579 VCRIGHT_hvacReqSecondRow 0;
BA_ "Confidence" SG_ 579 VCRIGHT_hvacAirflowReason 0;
BA_ "Confidence" SG_ 579 VCRIGHT_autoHvacBlowerShouldLimi 0;
BA_ "SystemSignalLongSymbol" SG_ 579 VCRIGHT_autoHvacBlowerShouldLimi "VCRIGHT_autoHvacBlowerShouldLimit";
BA_ "Confidence" SG_ 579 VCRIGHT_solarLoadOnVehicle 0;
BA_ "GenSigSNA" SG_ 579 VCRIGHT_solarLoadOnVehicle "255";
BA_ "Confidence" SG_ 579 VCRIGHT_refrigDistCommanded 0;
BA_ "Confidence" SG_ 579 VCRIGHT_hvacFrontRightSeatFanSta 0;
BA_ "SystemSignalLongSymbol" SG_ 579 VCRIGHT_hvacFrontRightSeatFanSta "VCRIGHT_hvacFrontRightSeatFanStatus";
BA_ "Confidence" SG_ 579 VCRIGHT_hvacFrontLeftSeatFanStat 0;
BA_ "SystemSignalLongSymbol" SG_ 579 VCRIGHT_hvacFrontLeftSeatFanStat "VCRIGHT_hvacFrontLeftSeatFanStatus";
BA_ "Confidence" SG_ 579 VCRIGHT_hvacFrontRightSeatHeatSt 0;
BA_ "SystemSignalLongSymbol" SG_ 579 VCRIGHT_hvacFrontRightSeatHeatSt "VCRIGHT_hvacFrontRightSeatHeatStatus";
BA_ "Confidence" SG_ 579 VCRIGHT_hvacSeatFrontLeftTempTar 0;
BA_ "SystemSignalLongSymbol" SG_ 579 VCRIGHT_hvacSeatFrontLeftTempTar "VCRIGHT_hvacSeatFrontLeftTempTarget";
BA_ "Confidence" SG_ 579 VCRIGHT_hvacManualToAutoNotify 0;
BA_ "Confidence" SG_ 579 VCRIGHT_hvacRequestsFullAuto 0;
BA_ "Confidence" SG_ 579 VCRIGHT_passengerPresentHvacCycl 0;
BA_ "SystemSignalLongSymbol" SG_ 579 VCRIGHT_passengerPresentHvacCycl "VCRIGHT_passengerPresentHvacCycle";
BA_ "Confidence" SG_ 579 VCRIGHT_hvacRequestsAutoIntake 0;
BA_ "Confidence" SG_ 579 VCRIGHT_steeringWheelHeatStatus 0;
BA_ "Confidence" SG_ 579 VCRIGHT_autoDefogStatus 0;
BA_ "Confidence" SG_ 579 VCRIGHT_solarElevation 0;
BA_ "GenSigSNA" SG_ 579 VCRIGHT_solarElevation "256";
BA_ "Confidence" SG_ 579 VCRIGHT_minsToSunrise 0;
BA_ "GenSigSNA" SG_ 579 VCRIGHT_minsToSunrise "255";
BA_ "Confidence" SG_ 579 VCRIGHT_minsToSunset 0;
BA_ "GenSigSNA" SG_ 579 VCRIGHT_minsToSunset "255";
BA_ "Confidence" SG_ 579 VCRIGHT_hvacLimitedReasonRight 0;
BA_ "Confidence" SG_ 579 VCRIGHT_hvacLimitedReasonLeft 0;
BA_ "Confidence" SG_ 579 VCRIGHT_hvacOverheatProtActive 0;
BA_ "Confidence" SG_ 579 VCRIGHT_tempDuctLeftUpper 0;
BA_ "GenSigSNA" SG_ 579 VCRIGHT_tempDuctLeftUpper "255";
BA_ "Confidence" SG_ 579 VCRIGHT_hvacFrontLeftSeatHeatSta 0;
BA_ "SystemSignalLongSymbol" SG_ 579 VCRIGHT_hvacFrontLeftSeatHeatSta "VCRIGHT_hvacFrontLeftSeatHeatStatus";
BA_ "Confidence" SG_ 579 VCRIGHT_hvacQdotLeft 0;
BA_ "Confidence" SG_ 579 VCRIGHT_hvacQdotRight 0;
BA_ "Confidence" SG_ 579 VCRIGHT_tempDuctLeftLower 0;
BA_ "GenSigSNA" SG_ 579 VCRIGHT_tempDuctLeftLower "255";
BA_ "Confidence" SG_ 579 VCRIGHT_tempDuctRightLower 0;
BA_ "GenSigSNA" SG_ 579 VCRIGHT_tempDuctRightLower "255";
BA_ "Confidence" SG_ 579 VCRIGHT_modeledCabinPressure 0;
BA_ "Confidence" SG_ 579 VCRIGHT_blowerTorqueIndex 0;
BA_ "Confidence" SG_ 579 VCRIGHT_autoSwingLeftPosX 0;
BA_ "Confidence" SG_ 579 VCRIGHT_autoSwingRightPositionX 0;
BA_ "Confidence" SG_ 774 VCRIGHT_infoIndex 1;
BA_ "Confidence" SG_ 774 VCRIGHT_infoBuildType 0;
BA_ "Confidence" SG_ 774 VCRIGHT_infoBuildConfigId 0;
BA_ "Confidence" SG_ 774 VCRIGHT_infoHardwareId 0;
BA_ "Confidence" SG_ 774 VCRIGHT_infoComponentId 0;
BA_ "Confidence" SG_ 774 VCRIGHT_infoPcbaId 0;
BA_ "Confidence" SG_ 774 VCRIGHT_infoAssemblyId 0;
BA_ "GenSigSNA" SG_ 774 VCRIGHT_infoAssemblyId "255";
BA_ "Confidence" SG_ 774 VCRIGHT_infoUsageId 0;
BA_ "Confidence" SG_ 774 VCRIGHT_infoSubUsageId 0;
BA_ "Confidence" SG_ 774 VCRIGHT_infoAppCrc 0;
BA_ "Confidence" SG_ 774 VCRIGHT_infoAppGitHash 0;
BA_ "Confidence" SG_ 774 VCRIGHT_infoBootGitHash 0;
BA_ "Confidence" SG_ 774 VCRIGHT_infoPlatformType 0;
BA_ "Confidence" SG_ 774 VCRIGHT_infoBootUdsProtoVersion 0;
BA_ "Confidence" SG_ 774 VCRIGHT_infoBootCrc 0;
BA_ "Confidence" SG_ 1803 VCRIGHT_logging0point1HzIndex 1;
BA_ "Confidence" SG_ 1803 VCRIGHT_cabinAirFilterLifeRemain 1;
BA_ "SystemSignalLongSymbol" SG_ 1803 VCRIGHT_cabinAirFilterLifeRemain "VCRIGHT_cabinAirFilterLifeRemaining";
BA_ "Confidence" SG_ 1803 VCRIGHT_HEPAAirFilterLifeRemaini 1;
BA_ "SystemSignalLongSymbol" SG_ 1803 VCRIGHT_HEPAAirFilterLifeRemaini "VCRIGHT_HEPAAirFilterLifeRemaining";
BA_ "Confidence" SG_ 1803 VCRIGHT_leftPTCCompromisedRod 0;
BA_ "Confidence" SG_ 1803 VCRIGHT_rightPTCCompromisedRod 0;
BA_ "Confidence" SG_ 1803 VCRIGHT_hepaFilterHealthScore 0;
BA_ "Confidence" SG_ 1803 VCRIGHT_cabinFilterHealthScore 0;
BA_ "Confidence" SG_ 1803 VCRIGHT_cabinTempBreathLevelFOff 0;
BA_ "GenSigSNA" SG_ 1803 VCRIGHT_cabinTempBreathLevelFOff "255";
BA_ "Confidence" SG_ 1803 VCRIGHT_airDistributionModeAdjus 0;
BA_ "SystemSignalLongSymbol" SG_ 1803 VCRIGHT_airDistributionModeAdjus "VCRIGHT_airDistributionModeAdjustmentFactor";
BA_ "Confidence" SG_ 1803 VCRIGHT_hvacLHBleedEndStop 0;
BA_ "Confidence" SG_ 1803 VCRIGHT_hvacRHBleedEndStop 0;
BA_ "Confidence" SG_ 1803 VCRIGHT_hvacLHVaneEndStop 0;
BA_ "Confidence" SG_ 1803 VCRIGHT_hvacRHVaneEndStop 0;
BA_ "Confidence" SG_ 1803 VCRIGHT_hvacUpperModeEndStop 0;
BA_ "Confidence" SG_ 1803 VCRIGHT_hvacLowerModeEndStop 0;
BA_ "Confidence" SG_ 1803 VCRIGHT_hvacIntakeEndStop 0;
BA_ "Confidence" SG_ 1803 VCRIGHT_hvacLHBleedZeroStop 0;
BA_ "Confidence" SG_ 1803 VCRIGHT_hvacRHBleedZeroStop 0;
BA_ "Confidence" SG_ 1803 VCRIGHT_hvacLHVaneZeroStop 0;
BA_ "Confidence" SG_ 1803 VCRIGHT_hvacRHVaneZeroStop 0;
BA_ "Confidence" SG_ 1803 VCRIGHT_hvacUpperModeZeroStop 0;
BA_ "Confidence" SG_ 1803 VCRIGHT_hvacLowerModeZeroStop 0;
BA_ "Confidence" SG_ 1803 VCRIGHT_hvacIntakeZeroStop 0;
BA_ "Confidence" SG_ 1803 VCRIGHT_ambientTempLimp 0;
BA_ "GenSigSNA" SG_ 1803 VCRIGHT_ambientTempLimp "255";
BA_ "Confidence" SG_ 1803 VCRIGHT_cabinProbeTempLimp 0;
BA_ "GenSigSNA" SG_ 1803 VCRIGHT_cabinProbeTempLimp "255";
BA_ "Confidence" SG_ 1803 VCRIGHT_thsTempLimp 0;
BA_ "GenSigSNA" SG_ 1803 VCRIGHT_thsTempLimp "255";
BA_ "Confidence" SG_ 1803 VCRIGHT_thsCabinWaterMassLimp 0;
BA_ "Confidence" SG_ 1803 VCRIGHT_thsSolarIrradianceLimp 0;
BA_ "GenSigSNA" SG_ 1803 VCRIGHT_thsSolarIrradianceLimp "255";
BA_ "Confidence" SG_ 1803 VCRIGHT_silentWakeRecordCount 0;
BA_ "Confidence" SG_ 1803 VCRIGHT_evapCondensateMass 0;
BA_ "Confidence" SG_ 1803 VCRIGHT_airwaveRightLateralTotal 0;
BA_ "SystemSignalLongSymbol" SG_ 1803 VCRIGHT_airwaveRightLateralTotal "VCRIGHT_airwaveRightLateralTotalTravel";
BA_ "Confidence" SG_ 1803 VCRIGHT_airwaveLeftLateralTotalT 0;
BA_ "SystemSignalLongSymbol" SG_ 1803 VCRIGHT_airwaveLeftLateralTotalT "VCRIGHT_airwaveLeftLateralTotalTravel";
BA_ "Confidence" SG_ 611 VCRIGHT_logging10HzIndex 1;
BA_ "Confidence" SG_ 611 VCRIGHT_hvacLHBleedTarget 1;
BA_ "Confidence" SG_ 611 VCRIGHT_hvacRHBleedTarget 1;
BA_ "Confidence" SG_ 611 VCRIGHT_hvacLHVaneTarget 1;
BA_ "Confidence" SG_ 611 VCRIGHT_hvacRHVaneTarget 1;
BA_ "Confidence" SG_ 611 VCRIGHT_hvacUpperModeTarget 1;
BA_ "Confidence" SG_ 611 VCRIGHT_hvacLowerModeTarget 1;
BA_ "Confidence" SG_ 611 VCRIGHT_hvacIntakeTarget 1;
BA_ "Confidence" SG_ 611 VCRIGHT_hvacLHBleedPosition 1;
BA_ "Confidence" SG_ 611 VCRIGHT_hvacRHBleedPosition 1;
BA_ "Confidence" SG_ 611 VCRIGHT_hvacLHVanePosition 1;
BA_ "Confidence" SG_ 611 VCRIGHT_hvacRHVanePosition 1;
BA_ "Confidence" SG_ 611 VCRIGHT_hvacUpperModePosition 1;
BA_ "Confidence" SG_ 611 VCRIGHT_hvacLowerModePosition 1;
BA_ "Confidence" SG_ 611 VCRIGHT_hvacIntakePosition 1;
BA_ "Confidence" SG_ 611 VCRIGHT_hvacLHBleedActuatorState 0;
BA_ "Confidence" SG_ 611 VCRIGHT_hvacRHBleedActuatorState 0;
BA_ "Confidence" SG_ 611 VCRIGHT_hvacLHVaneActuatorState 0;
BA_ "Confidence" SG_ 611 VCRIGHT_hvacRHVaneActuatorState 0;
BA_ "Confidence" SG_ 611 VCRIGHT_hvacUpperModeActState 0;
BA_ "Confidence" SG_ 611 VCRIGHT_hvacLowerModeActState 0;
BA_ "Confidence" SG_ 611 VCRIGHT_hvacIntakeActuatorState 0;
BA_ "Confidence" SG_ 611 VCRIGHT_EvapPulldownBiasActive 0;
BA_ "Confidence" SG_ 611 VCRIGHT_tempDatLeftEst 0;
BA_ "GenSigSNA" SG_ 611 VCRIGHT_tempDatLeftEst "255";
BA_ "Confidence" SG_ 611 VCRIGHT_tempDatRightEst 0;
BA_ "GenSigSNA" SG_ 611 VCRIGHT_tempDatRightEst "255";
BA_ "Confidence" SG_ 611 VCRIGHT_tempDuctLeftEst 0;
BA_ "GenSigSNA" SG_ 611 VCRIGHT_tempDuctLeftEst "255";
BA_ "Confidence" SG_ 611 VCRIGHT_tempDuctRightEst 0;
BA_ "GenSigSNA" SG_ 611 VCRIGHT_tempDuctRightEst "255";
BA_ "Confidence" SG_ 611 VCRIGHT_ptcHeaterBadRodDetection 0;
BA_ "SystemSignalLongSymbol" SG_ 611 VCRIGHT_ptcHeaterBadRodDetection "VCRIGHT_ptcHeaterBadRodDetectionState";
BA_ "Confidence" SG_ 611 VCRIGHT_leftVerticalActuatorDuty 0;
BA_ "Confidence" SG_ 611 VCRIGHT_leftLateralActuatorDuty 0;
BA_ "Confidence" SG_ 611 VCRIGHT_rightVerticalActuatorDut 0;
BA_ "SystemSignalLongSymbol" SG_ 611 VCRIGHT_rightVerticalActuatorDut "VCRIGHT_rightVerticalActuatorDuty";
BA_ "Confidence" SG_ 611 VCRIGHT_rightLateralActuatorDuty 0;
BA_ "Confidence" SG_ 611 VCRIGHT_frontLeftSeatTempTargetQ 0;
BA_ "SystemSignalLongSymbol" SG_ 611 VCRIGHT_frontLeftSeatTempTargetQ "VCRIGHT_frontLeftSeatTempTargetQuasiSS";
BA_ "Confidence" SG_ 611 VCRIGHT_frontRightSeatTempTarget 0;
BA_ "SystemSignalLongSymbol" SG_ 611 VCRIGHT_frontRightSeatTempTarget "VCRIGHT_frontRightSeatTempTargetQuasiSS";
VAL_ 322 VCLEFT_liftgateStatusIndex 2 "INVALID" 1 "1" 0 "0" ;
VAL_ 322 VCLEFT_liftgateState 13 "PLG_STATE_PARTY_DANCE" 12 "PLG_STATE_LATCH_ENTRY" 11 "PLG_STATE_END_OF_TRAVEL" 10 "PLG_STATE_LATCH_EXIT" 9 "PLG_STATE_UNKNOWN" 8 "PLG_STATE_NOT_INSTALLED" 7 "PLG_STATE_LATCH_CLOSING" 6 "PLG_STATE_LATCH_OPENING" 5 "PLG_STATE_CLOSED" 4 "PLG_STATE_CLOSING" 3 "PLG_STATE_OPENING" 2 "PLG_STATE_BACKOFF" 1 "PLG_STATE_OFF" 0 "PLG_STATE_INIT" ;
VAL_ 322 VCLEFT_liftgateStoppingCondition 13 "PLG_STOPPING_CONDITION_COUNT" 12 "PLG_STOPPING_CONDITION_FOLLOWER_REQUEST" 11 "PLG_STOPPING_CONDITION_OBSTACLE_CURRENT_SPIKE" 10 "PLG_STOPPING_CONDITION_LATCH_FAULT" 9 "PLG_STOPPING_CONDITION_UNCALIBRATED" 8 "PLG_STOPPING_CONDITION_OBSTACLE_TRAJ_VEL" 7 "PLG_STOPPING_CONDITION_OBSTACLE_TRAJ_POS" 6 "PLG_STOPPING_CONDITION_OBSTACLE_CURRENT" 5 "PLG_STOPPING_CONDITION_VEHICLE_AT_SPEED" 4 "PLG_STOPPING_CONDITION_STATE_TIMEOUT" 3 "PLG_STOPPING_CONDITION_LOW_12V" 2 "PLG_STOPPING_CONDITION_OBSTACLE_STALL" 1 "PLG_STOPPING_CONDITION_PINCH" 0 "PLG_STOPPING_CONDITION_NONE" ;
VAL_ 322 VCLEFT_liftgateMvmntNotAllowedCo 6 "PLG_MVMT_NOT_ALLOWED_STRUT_POSITION_MISMATCH" 5 "PLG_MVMT_NOT_ALLOWED_LOCKED" 4 "PLG_MVMT_NOT_ALLOWED_EXTERIOR_PRESS_AT_MAX_OPEN" 3 "PLG_MVMT_NOT_ALLOWED_UNCALIBRATED" 2 "PLG_MVMT_NOT_ALLOWED_VEHICLE_AT_SPEED" 1 "PLG_MVMT_NOT_ALLOWED_LOW_12V" 0 "PLG_MVMT_NOT_ALLOWED_NONE" ;
VAL_ 322 VCLEFT_liftgateUIChimeRequest 4 "REMOTE_CHIME_REQUEST_ONE_LONG" 3 "REMOTE_CHIME_REQUEST_THREE_SHORT" 2 "REMOTE_CHIME_REQUEST_TWO_SHORT" 1 "REMOTE_CHIME_REQUEST_ONE_SHORT" 0 "REMOTE_CHIME_REQUEST_NONE" ;
VAL_ 322 VCLEFT_liftgatePhysicalChimeRequ 4 "REMOTE_CHIME_REQUEST_ONE_LONG" 3 "REMOTE_CHIME_REQUEST_THREE_SHORT" 2 "REMOTE_CHIME_REQUEST_TWO_SHORT" 1 "REMOTE_CHIME_REQUEST_ONE_SHORT" 0 "REMOTE_CHIME_REQUEST_NONE" ;
VAL_ 322 VCLEFT_liftgateStaticStrutMode 5 "PLG_STATIC_STRUT_MODE_SLAM_BRAKE" 4 "PLG_STATIC_STRUT_MODE_OPEN_COAST" 3 "PLG_STATIC_STRUT_MODE_CLOSE_COAST" 2 "PLG_STATIC_STRUT_MODE_BRAKE_HOLD" 1 "PLG_STATIC_STRUT_MODE_OFF_COAST" 0 "PLG_STATIC_STRUT_MODE_UNKNOWN_SNA" ;
VAL_ 322 VCLEFT_liftgateRequestSource 9 "PLG_REQUEST_SOURCE_DAS" 8 "PLG_REQUEST_SOURCE_EMERG_RELEASE" 7 "PLG_REQUEST_SOURCE_UDS" 6 "PLG_REQUEST_SOURCE_PARTY" 5 "PLG_REQUEST_SOURCE_VCSEC_COMMAND" 4 "PLG_REQUEST_SOURCE_KEY_TRUNK_BUTTON" 3 "PLG_REQUEST_SOURCE_SHUTFACE" 2 "PLG_REQUEST_SOURCE_EXTERIOR" 1 "PLG_REQUEST_SOURCE_MCU_SWITCH" 0 "PLG_REQUEST_SOURCE_NONE" ;
VAL_ 322 VCLEFT_liftgateGeofenceState 3 "PLG_GEOFENCE_STATE_WAITING_TO_STOP" 2 "PLG_GEOFENCE_STATE_SETTING_HEIGHT" 1 "PLG_GEOFENCE_STATE_WAITING_TO_TRIGGER" 0 "PLG_GEOFENCE_STATE_INIT" ;
VAL_ 322 VCLEFT_liftgateLatchRequest 4 "LATCH_REQUEST_RESET" 3 "LATCH_REQUEST_FORCE_RELEASE" 2 "LATCH_REQUEST_RELEASE_V2" 1 "LATCH_REQUEST_CINCH" 0 "LATCH_REQUEST_NONE" ;
VAL_ 994 VCLEFT_brakeLightStatus 3 "LIGHT_SNA" 2 "LIGHT_FAULT" 1 "LIGHT_ON" 0 "LIGHT_OFF" ;
VAL_ 994 VCLEFT_tailLightStatus 3 "LIGHT_SNA" 2 "LIGHT_FAULT" 1 "LIGHT_ON" 0 "LIGHT_OFF" ;
VAL_ 994 VCLEFT_turnSignalStatus 3 "LIGHT_SNA" 2 "LIGHT_FAULT" 1 "LIGHT_ON" 0 "LIGHT_OFF" ;
VAL_ 994 VCLEFT_FLMapLightStatus 3 "LIGHT_SNA" 2 "LIGHT_FAULT" 1 "LIGHT_ON" 0 "LIGHT_OFF" ;
VAL_ 994 VCLEFT_FRMapLightStatus 3 "LIGHT_SNA" 2 "LIGHT_FAULT" 1 "LIGHT_ON" 0 "LIGHT_OFF" ;
VAL_ 994 VCLEFT_RLMapLightStatus 3 "LIGHT_SNA" 2 "LIGHT_FAULT" 1 "LIGHT_ON" 0 "LIGHT_OFF" ;
VAL_ 994 VCLEFT_RRMapLightStatus 3 "LIGHT_SNA" 2 "LIGHT_FAULT" 1 "LIGHT_ON" 0 "LIGHT_OFF" ;
VAL_ 994 VCLEFT_leftTurnTrailerLightStatu 3 "LIGHT_SNA" 2 "LIGHT_FAULT" 1 "LIGHT_ON" 0 "LIGHT_OFF" ;
VAL_ 994 VCLEFT_rightTrnTrailerLightStatu 3 "LIGHT_SNA" 2 "LIGHT_FAULT" 1 "LIGHT_ON" 0 "LIGHT_OFF" ;
VAL_ 994 VCLEFT_brakeTrailerLightStatus 3 "LIGHT_SNA" 2 "LIGHT_FAULT" 1 "LIGHT_ON" 0 "LIGHT_OFF" ;
VAL_ 994 VCLEFT_tailTrailerLightStatus 3 "LIGHT_SNA" 2 "LIGHT_FAULT" 1 "LIGHT_ON" 0 "LIGHT_OFF" ;
VAL_ 994 VCLEFT_fogTrailerLightStatus 3 "LIGHT_SNA" 2 "LIGHT_FAULT" 1 "LIGHT_ON" 0 "LIGHT_OFF" ;
VAL_ 994 VCLEFT_frontRideHeight -128 "SNA" ;
VAL_ 994 VCLEFT_rearRideHeight -128 "SNA" ;
VAL_ 994 VCLEFT_trailerDetected 3 "TRAILER_LIGHT_DETECTION_NOT_DETECTED" 2 "TRAILER_LIGHT_DETECTION_DETECTED" 1 "TRAILER_LIGHT_DETECTION_FAULT" 0 "TRAILER_LIGHT_DETECTION_SNA" ;
VAL_ 994 VCLEFT_reverseTrailerLightStatus 3 "LIGHT_SNA" 2 "LIGHT_FAULT" 1 "LIGHT_ON" 0 "LIGHT_OFF" ;
VAL_ 994 VCLEFT_reverseLightStatus 3 "LIGHT_SNA" 2 "LIGHT_FAULT" 1 "LIGHT_ON" 0 "LIGHT_OFF" ;
VAL_ 1802 VCLEFT_logging0point1HzIndex 1 "END" 0 "MISC" ;
VAL_ 1802 VCLEFT_leftBrakeTailLightCurrent 511 "SNA" ;
VAL_ 1802 VCLEFT_leftBrakeTailLightCu_0001 4 "FALLING_EDGE_TRANSIENT" 3 "STEADY_STATE_ON" 2 "RISING_EDGE_TRANSIENT" 1 "STEADY_STATE_OFF" 0 "SNA" ;
VAL_ 1802 VCLEFT_leftRearTurnLightCurrent 511 "SNA" ;
VAL_ 1802 VCLEFT_leftRearTurnLightCurrentS 4 "FALLING_EDGE_TRANSIENT" 3 "STEADY_STATE_ON" 2 "RISING_EDGE_TRANSIENT" 1 "STEADY_STATE_OFF" 0 "SNA" ;
VAL_ 936 VCLEFT_logging1HzIndex 3 "END" 2 "HSD_CURRENTS_2" 1 "HSD_CURRENTS_1" 0 "MISC" ;
VAL_ 936 VCLEFT_tohcPCBATemperature 255 "SNA" ;
VAL_ 936 VCLEFT_swcResistance 127 "SNA" ;
VAL_ 727 VCLEFT_pitchEstimateArbitratedSt 7 "PITCHESTIMATION_ARBITRATEDSTATE_UNKNOWN" 5 "PITCHESTIMATION_ARBITRATEDSTATE_LIVE_AX_NO_DELTA" 4 "PITCHESTIMATION_ARBITRATEDSTATE_CYCLE_DELTA_FROZEN" 3 "PITCHESTIMATION_ARBITRATEDSTATE_CYCLE_DELTA_CARRYOVER" 2 "PITCHESTIMATION_ARBITRATEDSTATE_CYCLE_DELTA_LIVE" 1 "PITCHESTIMATION_ARBITRATEDSTATE_FUSION" 0 "PITCHESTIMATION_ARBITRATEDSTATE_UNAVAILABLE" ;
VAL_ 727 VCLEFT_pitchEstimateFusionState 7 "PITCHESTIMATION_STATE_UNKNOWN" 4 "PITCHESTIMATION_STATE_CALCULATE" 3 "PITCHESTIMATION_STATE_WAIT_FOR_STARTUP" 2 "PITCHESTIMATION_STATE_WAIT_FOR_SPEED" 1 "PITCHESTIMATION_STATE_WAIT_FOR_SIGNALS_AND_DOORS" 0 "PITCHESTIMATION_STATE_INIT" ;
VAL_ 727 VCLEFT_pitchEstimateStateTransit 26 "PITCHESTIMATION_DELTA_LIVE_THEN_VALIDITIES_NOT_GOOD" 25 "PITCHESTIMATION_DELTA_LIVE_THEN_FUSION_INIT" 24 "PITCHESTIMATION_DELTA_LIVE_THEN_LIVE_AX" 23 "PITCHESTIMATION_DELTA_LIVE_THEN_SPEED_AND_EPB_NOT_PARKED" 22 "PITCHESTIMATION_DELTA_LIVE_THEN_NVRAM_DISALLOW" 21 "PITCHESTIMATION_DELTA_LIVE_THEN_TRANSPORT" 20 "PITCHESTIMATION_DELTA_LIVE_THEN_DOORS_CLOSED_LONG_TIME" 19 "PITCHESTIMATION_DELTA_LIVE_THEN_EPB_RELEASING" 18 "PITCHESTIMATION_CARRYOVER_THEN_LIVE_AX" 17 "PITCHESTIMATION_CARRYOVER_THEN_FUSION_READY" 16 "PITCHESTIMATION_CARRYOVER_THEN_VALIDITIES_NOT_GOOD" 15 "PITCHESTIMATION_CARRYOVER_THEN_FUSION_INIT" 14 "PITCHESTIMATION_FROZEN_THEN_LIVE_AX" 13 "PITCHESTIMATION_FROZEN_THEN_FUSION_READY" 12 "PITCHESTIMATION_FROZEN_THEN_VALIDITIES_NOT_GOOD" 11 "PITCHESTIMATION_FROZEN_THEN_FUSION_INIT" 10 "PITCHESTIMATION_FUSION_THEN_LIVE_AX" 9 "PITCHESTIMATION_FUSION_THEN_FUSION_INIT" 8 "PITCHESTIMATION_UNAVAILABLE_THEN_LIVE_AX" 7 "PITCHESTIMATION_UNAVAILABLE_THEN_FUSION_READY" 6 "PITCHESTIMATION_UNAVAILABLE_THEN_DELTA_LIVE_READY" 5 "PITCHESTIMATION_UNAVAILABLE_THEN_SPEED_AND_EPB_NOT_PARKED" 4 "PITCHESTIMATION_UNAVAILABLE_THEN_NVRAM_DISALLOW" 3 "PITCHESTIMATION_UNAVAILABLE_THEN_TRANSPORT" 2 "PITCHESTIMATION_LIVE_AX_THEN_VALIDITIES_NOT_GOOD" 1 "PITCHESTIMATION_LIVE_AX_THEN_NO_LONGER_LIVE_AX" 0 "PITCHESTIMATION_INVALID_STATE_TRANSITION_DEFAULT" ;
VAL_ 727 VCLEFT_pitchEstimate -512 "SNA" ;
VAL_ 1863 VCLEFT_frontOccupancyStatus 7 "SEAT_OCCUPANCY_SNA" 3 "SEAT_NOT_CONFIGURED" 2 "SEAT_OCCUPANCY_FAULTED" 1 "SEAT_OCCUPIED" 0 "SEAT_UNOCCUPIED" ;
VAL_ 1863 VCLEFT_frontBuckleStatus 3 "SEAT_BELT_BUCKLE_NOT_CONFIGURED" 2 "SEAT_BELT_BUCKLE_STATUS_FAULTED" 1 "SEAT_BELT_BUCKLE_STATUS_LATCHED" 0 "SEAT_BELT_BUCKLE_STATUS_UNLATCHED" ;
VAL_ 1863 VCLEFT_rearLeftOccupancyStatus 3 "SEAT_NOT_CONFIGURED" 2 "SEAT_OCCUPANCY_FAULTED" 1 "SEAT_OCCUPIED" 0 "SEAT_UNOCCUPIED" ;
VAL_ 1863 VCLEFT_rearCenterOccupancyStatus 3 "SEAT_NOT_CONFIGURED" 2 "SEAT_OCCUPANCY_FAULTED" 1 "SEAT_OCCUPIED" 0 "SEAT_UNOCCUPIED" ;
VAL_ 1863 VCLEFT_rearRightOccupancyStatus 3 "SEAT_NOT_CONFIGURED" 2 "SEAT_OCCUPANCY_FAULTED" 1 "SEAT_OCCUPIED" 0 "SEAT_UNOCCUPIED" ;
VAL_ 1863 VCLEFT_rearLeftBuckleStatus 3 "SEAT_BELT_BUCKLE_NOT_CONFIGURED" 2 "SEAT_BELT_BUCKLE_STATUS_FAULTED" 1 "SEAT_BELT_BUCKLE_STATUS_LATCHED" 0 "SEAT_BELT_BUCKLE_STATUS_UNLATCHED" ;
VAL_ 1863 VCLEFT_rearCenterBuckleStatus 3 "SEAT_BELT_BUCKLE_NOT_CONFIGURED" 2 "SEAT_BELT_BUCKLE_STATUS_FAULTED" 1 "SEAT_BELT_BUCKLE_STATUS_LATCHED" 0 "SEAT_BELT_BUCKLE_STATUS_UNLATCHED" ;
VAL_ 1863 VCLEFT_seatTrackPosition 7 "SEAT_TRACK_POSITION_SNA" 3 "SEAT_TRACK_POSITION_FAULTED" 2 "SEAT_TRACK_POSITION_NOT_CONFIGURED" 1 "SEAT_TRACK_POSITION_REARWARD" 0 "SEAT_TRACK_POSITION_FORWARD" ;
VAL_ 1250 VCLEFT_seatStatusIndex 7 "RELATIVE_POSITION" 6 "OFFSETS" 5 "POSITION" 4 "LUMBAR" 3 "TILT" 2 "LIFT" 1 "BACK" 0 "TRACK" ;
VAL_ 1250 VCLEFT_frontSeatTrackState 5 "SEAT_STATE_UNDEFINED" 4 "SEAT_STATE_CALIBRATING" 3 "SEAT_STATE_RECALLING" 2 "SEAT_STATE_MOVING_DOWN" 1 "SEAT_STATE_MOVING_UP" 0 "SEAT_STATE_STOPPED" ;
VAL_ 1250 VCLEFT_frontSeatTrackBridgeSt 3 "IO_BRIDGE_STATE_COAST" 2 "IO_BRIDGE_STATE_BRAKE" 1 "IO_BRIDGE_STATE_ENABLED" 0 "IO_BRIDGE_STATE_DISABLED" ;
VAL_ 1250 VCLEFT_frontSeatBackState 5 "SEAT_STATE_UNDEFINED" 4 "SEAT_STATE_CALIBRATING" 3 "SEAT_STATE_RECALLING" 2 "SEAT_STATE_MOVING_DOWN" 1 "SEAT_STATE_MOVING_UP" 0 "SEAT_STATE_STOPPED" ;
VAL_ 1250 VCLEFT_frontSeatBackBridgeSt 3 "IO_BRIDGE_STATE_COAST" 2 "IO_BRIDGE_STATE_BRAKE" 1 "IO_BRIDGE_STATE_ENABLED" 0 "IO_BRIDGE_STATE_DISABLED" ;
VAL_ 1250 VCLEFT_frontSeatLiftState 5 "SEAT_STATE_UNDEFINED" 4 "SEAT_STATE_CALIBRATING" 3 "SEAT_STATE_RECALLING" 2 "SEAT_STATE_MOVING_DOWN" 1 "SEAT_STATE_MOVING_UP" 0 "SEAT_STATE_STOPPED" ;
VAL_ 1250 VCLEFT_frontSeatLiftBridgeSt 3 "IO_BRIDGE_STATE_COAST" 2 "IO_BRIDGE_STATE_BRAKE" 1 "IO_BRIDGE_STATE_ENABLED" 0 "IO_BRIDGE_STATE_DISABLED" ;
VAL_ 1250 VCLEFT_frontSeatTiltState 5 "SEAT_STATE_UNDEFINED" 4 "SEAT_STATE_CALIBRATING" 3 "SEAT_STATE_RECALLING" 2 "SEAT_STATE_MOVING_DOWN" 1 "SEAT_STATE_MOVING_UP" 0 "SEAT_STATE_STOPPED" ;
VAL_ 1250 VCLEFT_frontSeatTiltBridgeSt 3 "IO_BRIDGE_STATE_COAST" 2 "IO_BRIDGE_STATE_BRAKE" 1 "IO_BRIDGE_STATE_ENABLED" 0 "IO_BRIDGE_STATE_DISABLED" ;
VAL_ 1250 VCLEFT_lumbarAState 5 "SEAT_STATE_UNDEFINED" 4 "SEAT_STATE_CALIBRATING" 3 "SEAT_STATE_RECALLING" 2 "SEAT_STATE_MOVING_DOWN" 1 "SEAT_STATE_MOVING_UP" 0 "SEAT_STATE_STOPPED" ;
VAL_ 1250 VCLEFT_lumbarBState 5 "SEAT_STATE_UNDEFINED" 4 "SEAT_STATE_CALIBRATING" 3 "SEAT_STATE_RECALLING" 2 "SEAT_STATE_MOVING_DOWN" 1 "SEAT_STATE_MOVING_UP" 0 "SEAT_STATE_STOPPED" ;
VAL_ 738 VCLEFT_seatStatus2Index 12 "SEAT_2ROW_ADJUSTABLE_FOLD_FLAT_2" 11 "SEAT_2ROW_ADJUSTABLE_FOLD_FLAT" 10 "SEAT_MUX_INDEX_PLACEHOLDER" 9 "SEAT_2ROW_EASY_ENTRY" 8 "SEAT_SWITCH_VOLTAGES_2" 7 "SEAT_SWITCH_VOLTAGES_1" 6 "SEAT_2ROW_ACTUATOR" 5 "SEAT_HEAT_REARR_CUSHION" 4 "SEAT_HEAT_REARC" 3 "SEAT_HEAT_REARL" 2 "OCCUPANCY" 1 "SEAT_HEAT_REARL_BACKREST" 0 "SEAT_HEAT_FRONT" ;
VAL_ 738 VCLEFT_frontSeatHeatCurrent 12 "SNA" ;
VAL_ 738 VCLEFT_2RowSeatReclineState 15 "SEAT_ADJUSTABLE_FOLD_FLAT_STATE_SNA" 12 "SEAT_ADJUSTABLE_FOLD_FLAT_STATE_CALIBRATING_ABSOLUTE_SENSOR" 11 "SEAT_ADJUSTABLE_FOLD_FLAT_STATE_CALIBRATING_ZERO_POSITION" 10 "SEAT_ADJUSTABLE_FOLD_FLAT_STATE_WAITING_TO_CLEAR_FOR_UNFOLD" 9 "SEAT_ADJUSTABLE_FOLD_FLAT_STATE_WAITING_TO_CLEAR_FOR_FOLD" 8 "SEAT_ADJUSTABLE_FOLD_FLAT_STATE_MOVING_REARWARD_TO_POSITION" 7 "SEAT_ADJUSTABLE_FOLD_FLAT_STATE_MOVING_FORWARD_TO_POSITION" 6 "SEAT_ADJUSTABLE_FOLD_FLAT_STATE_UNFOLDING" 5 "SEAT_ADJUSTABLE_FOLD_FLAT_STATE_FOLDING" 4 "SEAT_ADJUSTABLE_FOLD_FLAT_STATE_ADJUSTING_REARWARD_FAST" 3 "SEAT_ADJUSTABLE_FOLD_FLAT_STATE_ADJUSTING_FORWARD_FAST" 2 "SEAT_ADJUSTABLE_FOLD_FLAT_STATE_ADJUSTING_REARWARD_COMFORT" 1 "SEAT_ADJUSTABLE_FOLD_FLAT_STATE_ADJUSTING_FORWARD_COMFORT" 0 "SEAT_ADJUSTABLE_FOLD_FLAT_STATE_STOPPED" ;
VAL_ 738 VCLEFT_2RowSeatReclineAbsPosSwit 3 "SWITCH_FAULT" 2 "SWITCH_ON" 1 "SWITCH_OFF" 0 "SWITCH_SNA" ;
VAL_ 738 VCLEFT_2RowSeatReclinePositionSt 4 "SEAT_ADJUSTABLE_FOLD_FLAT_POSITION_STATE_SNA" 3 "SEAT_ADJUSTABLE_FOLD_FLAT_POSITION_STATE_UNKNOWN" 2 "SEAT_ADJUSTABLE_FOLD_FLAT_POSITION_STATE_UNSAFE_INTERMEDIATE" 1 "SEAT_ADJUSTABLE_FOLD_FLAT_POSITION_STATE_UNFOLDED" 0 "SEAT_ADJUSTABLE_FOLD_FLAT_POSITION_STATE_FOLDED" ;
VAL_ 738 VCLEFT_2RowSeatReclineNextToggle 2 "SEAT_ADJUSTABLE_FOLD_FLAT_NEXT_TOGGLE_DIRECTION_SNA" 1 "SEAT_ADJUSTABLE_FOLD_FLAT_NEXT_TOGGLE_DIRECTION_UNFOLD" 0 "SEAT_ADJUSTABLE_FOLD_FLAT_NEXT_TOGGLE_DIRECTION_FOLD" ;
VAL_ 738 VCLEFT_2RowSeat1RClashAvoidanceB 6 "SEAT_FOLD_FLAT_CLASH_AVOIDANCE_REASON_FRONT_SEAT_OCCUPANCY" 5 "SEAT_FOLD_FLAT_CLASH_AVOIDANCE_REASON_FRONT_SEAT_MOVING" 4 "SEAT_FOLD_FLAT_CLASH_AVOIDANCE_REASON_FRONT_SEAT_PROFILE_RECALL" 3 "SEAT_FOLD_FLAT_CLASH_AVOIDANCE_REASON_REAR_SEAT_UNCALIBRATED" 2 "SEAT_FOLD_FLAT_CLASH_AVOIDANCE_REASON_FRONT_SEAT_UNCALIBRATED" 1 "SEAT_FOLD_FLAT_CLASH_AVOIDANCE_REASON_VEHICLE_IN_MOTION" 0 "SEAT_FOLD_FLAT_CLASH_AVOIDANCE_REASON_NONE" ;
VAL_ 738 VCLEFT_2RowSeat1RClashAvoidanceS 3 "SEAT_FOLD_FLAT_CLASH_AVOIDANCE_STATE_RESTORING_FRONT_SEAT" 2 "SEAT_FOLD_FLAT_CLASH_AVOIDANCE_STATE_WAITING_TO_RESTORE_FRONT_SEAT" 1 "SEAT_FOLD_FLAT_CLASH_AVOIDANCE_STATE_FRONT_SEAT_CLEARING" 0 "SEAT_FOLD_FLAT_CLASH_AVOIDANCE_STATE_IDLE" ;
VAL_ 930 VCLEFT_statusIndex 2 "MUX2" 1 "MUX1" 0 "MUX0" ;
VAL_ 930 VCLEFT_swcInputVoltage 255 "SNA" ;
VAL_ 930 VCLEFT_swcPCBATemperature -128 "SNA" ;
VAL_ 930 VCLEFT_LVBatteryTypeDBG 5 "LV_BATTERY_TYPE_TESLA_48V_LI_ION" 4 "LV_BATTERY_TYPE_TESLA_16V_LI_ION" 3 "LV_BATTERY_TYPE_CATL_LI_ION" 2 "LV_BATTERY_TYPE_CLARIOS_B24_FLOODED" 1 "LV_BATTERY_TYPE_ATLASBX_B24_FLOODED" 0 "LV_BATTERY_TYPE_UNKNOWN" ;
VAL_ 930 VCLEFT_trailerAuxCurrent 4095 "SNA" ;
VAL_ 930 VCLEFT_swcHeatTmp 1023 "SNA" ;
VAL_ 930 VCLEFT_swcHeatStatus 4 "HEATER_STATE_FAULT" 3 "HEATER_STATE_OFF_UNAVAILABLE" 2 "HEATER_STATE_OFF" 1 "HEATER_STATE_ON" 0 "HEATER_STATE_SNA" ;
VAL_ 930 VCLEFT_swcHeatPwr 511 "SNA" ;
VAL_ 930 VCLEFT_swcHeatDutyCycle 127 "SNA" ;
VAL_ 962 VCLEFT_switchStatusIndex 1 "1" 0 "0" ;
VAL_ 962 VCLEFT_rightMirrorTilt 4 "MIRROR_TILT_LEFT" 3 "MIRROR_TILT_RIGHT" 2 "MIRROR_TILT_UP" 1 "MIRROR_TILT_DOWN" 0 "MIRROR_TILT_STOP" ;
VAL_ 962 VCLEFT_frontSeatTrackBack 3 "SWITCH_FAULT" 2 "SWITCH_ON" 1 "SWITCH_OFF" 0 "SWITCH_SNA" ;
VAL_ 962 VCLEFT_frontSeatTrackForward 3 "SWITCH_FAULT" 2 "SWITCH_ON" 1 "SWITCH_OFF" 0 "SWITCH_SNA" ;
VAL_ 962 VCLEFT_frontSeatTiltDown 3 "SWITCH_FAULT" 2 "SWITCH_ON" 1 "SWITCH_OFF" 0 "SWITCH_SNA" ;
VAL_ 962 VCLEFT_frontSeatTiltUp 3 "SWITCH_FAULT" 2 "SWITCH_ON" 1 "SWITCH_OFF" 0 "SWITCH_SNA" ;
VAL_ 962 VCLEFT_frontSeatLiftDown 3 "SWITCH_FAULT" 2 "SWITCH_ON" 1 "SWITCH_OFF" 0 "SWITCH_SNA" ;
VAL_ 962 VCLEFT_frontSeatLiftUp 3 "SWITCH_FAULT" 2 "SWITCH_ON" 1 "SWITCH_OFF" 0 "SWITCH_SNA" ;
VAL_ 962 VCLEFT_frontSeatBackrestBack 3 "SWITCH_FAULT" 2 "SWITCH_ON" 1 "SWITCH_OFF" 0 "SWITCH_SNA" ;
VAL_ 962 VCLEFT_frontSeatBackrestForward 3 "SWITCH_FAULT" 2 "SWITCH_ON" 1 "SWITCH_OFF" 0 "SWITCH_SNA" ;
VAL_ 962 VCLEFT_frontSeatLumbarDown 3 "SWITCH_FAULT" 2 "SWITCH_ON" 1 "SWITCH_OFF" 0 "SWITCH_SNA" ;
VAL_ 962 VCLEFT_frontSeatLumbarUp 3 "SWITCH_FAULT" 2 "SWITCH_ON" 1 "SWITCH_OFF" 0 "SWITCH_SNA" ;
VAL_ 962 VCLEFT_frontSeatLumbarIn 3 "SWITCH_FAULT" 2 "SWITCH_ON" 1 "SWITCH_OFF" 0 "SWITCH_SNA" ;
VAL_ 962 VCLEFT_frontSeatLumbarOut 3 "SWITCH_FAULT" 2 "SWITCH_ON" 1 "SWITCH_OFF" 0 "SWITCH_SNA" ;
VAL_ 962 VCLEFT_frontBuckleSwitch 3 "SWITCH_FAULT" 2 "SWITCH_ON" 1 "SWITCH_OFF" 0 "SWITCH_SNA" ;
VAL_ 962 VCLEFT_frontOccupancySwitch 3 "SWITCH_FAULT" 2 "SWITCH_ON" 1 "SWITCH_OFF" 0 "SWITCH_SNA" ;
VAL_ 962 VCLEFT_rearLeftBuckleSwitch 3 "SWITCH_FAULT" 2 "SWITCH_ON" 1 "SWITCH_OFF" 0 "SWITCH_SNA" ;
VAL_ 962 VCLEFT_rearCenterOccupancySwitch 3 "SWITCH_FAULT" 2 "SWITCH_ON" 1 "SWITCH_OFF" 0 "SWITCH_SNA" ;
VAL_ 962 VCLEFT_rearLeftOccupancySwitch 3 "SWITCH_FAULT" 2 "SWITCH_ON" 1 "SWITCH_OFF" 0 "SWITCH_SNA" ;
VAL_ 962 VCLEFT_rearRightOccupancySwitch 3 "SWITCH_FAULT" 2 "SWITCH_ON" 1 "SWITCH_OFF" 0 "SWITCH_SNA" ;
VAL_ 962 VCLEFT_rearCenterBuckleSwitch 3 "SWITCH_FAULT" 2 "SWITCH_ON" 1 "SWITCH_OFF" 0 "SWITCH_SNA" ;
VAL_ 962 VCLEFT_swcLeftTiltRight 3 "SWITCH_FAULT" 2 "SWITCH_ON" 1 "SWITCH_OFF" 0 "SWITCH_SNA" ;
VAL_ 962 VCLEFT_swcLeftPressed 3 "SWITCH_FAULT" 2 "SWITCH_ON" 1 "SWITCH_OFF" 0 "SWITCH_SNA" ;
VAL_ 962 VCLEFT_swcRightTiltLeft 3 "SWITCH_FAULT" 2 "SWITCH_ON" 1 "SWITCH_OFF" 0 "SWITCH_SNA" ;
VAL_ 962 VCLEFT_swcRightTiltRight 3 "SWITCH_FAULT" 2 "SWITCH_ON" 1 "SWITCH_OFF" 0 "SWITCH_SNA" ;
VAL_ 962 VCLEFT_swcRightPressed 3 "SWITCH_FAULT" 2 "SWITCH_ON" 1 "SWITCH_OFF" 0 "SWITCH_SNA" ;
VAL_ 962 VCLEFT_swcLeftTiltLeft 3 "SWITCH_FAULT" 2 "SWITCH_ON" 1 "SWITCH_OFF" 0 "SWITCH_SNA" ;
VAL_ 962 VCLEFT_swcWiperButtonState 3 "FAULT" 2 "HARD_PRESS" 1 "SOFT_PRESS" 0 "INACTIVE" ;
VAL_ 962 VCLEFT_swcTurnSignalLeftButtonSt 3 "FAULT" 2 "HARD_PRESS" 1 "SOFT_PRESS" 0 "INACTIVE" ;
VAL_ 962 VCLEFT_swcTurnSignalRightButtonS 3 "FAULT" 2 "HARD_PRESS" 1 "SOFT_PRESS" 0 "INACTIVE" ;
VAL_ 962 VCLEFT_swcHighBeamButtonState 3 "FAULT" 2 "HARD_PRESS" 1 "SOFT_PRESS" 0 "INACTIVE" ;
VAL_ 962 VCLEFT_swcVoiceControlPress 3 "SWITCH_FAULT" 2 "SWITCH_ON" 1 "SWITCH_OFF" 0 "SWITCH_SNA" ;
VAL_ 962 VCLEFT_swcCameraButtonState 3 "FAULT" 2 "HARD_PRESS" 1 "SOFT_PRESS" 0 "INACTIVE" ;
VAL_ 962 VCLEFT_swcRightPressedQF 1 "VALID" 0 "INVALID" ;
VAL_ 962 VCLEFT_frontSeatResistiveOccupan 3 "SWITCH_FAULT" 2 "SWITCH_ON" 1 "SWITCH_OFF" 0 "SWITCH_SNA" ;
VAL_ 656 VCLEFT_thermalLogging10HzIndex 5 "END" 4 "2R_HVAC_DUTY" 3 "MISC" 2 "2R_HVAC_VOLTAGE_AND_STATUS" 1 "HVAC_VARS2" 0 "HVAC_VARS" ;
VAL_ 656 VCLEFT_hvac2RLeftLateralCalibrat 1 "CALIBRATED" 0 "NOT_CALIBRATED" ;
VAL_ 656 VCLEFT_hvac2RLeftVerticalCalibra 1 "CALIBRATED" 0 "NOT_CALIBRATED" ;
VAL_ 656 VCLEFT_hvac2RRightLateralCalibra 1 "CALIBRATED" 0 "NOT_CALIBRATED" ;
VAL_ 656 VCLEFT_hvac2RRightVerticalCalibr 1 "CALIBRATED" 0 "NOT_CALIBRATED" ;
VAL_ 656 VCLEFT_hvac2RLeftLateralState 11 "HVAC_ACTUATOR_BRUSHED_STATE_RUNNING_OVERSHOOT" 10 "HVAC_ACTUATOR_BRUSHED_STATE_NEGATIVE_BACKOFF" 9 "HVAC_ACTUATOR_BRUSHED_STATE_POSITIVE_BACKOFF" 8 "HVAC_ACTUATOR_BRUSHED_STATE_CONTROL_DISABLED" 7 "HVAC_ACTUATOR_BRUSHED_STATE_FAULT" 6 "HVAC_ACTUATOR_BRUSHED_STATE_BRAKING" 5 "HVAC_ACTUATOR_BRUSHED_STATE_RUNNING" 4 "HVAC_ACTUATOR_BRUSHED_STATE_NEGATIVE_STALL" 3 "HVAC_ACTUATOR_BRUSHED_STATE_NEGATIVE_RUN" 2 "HVAC_ACTUATOR_BRUSHED_STATE_POSITIVE_STALL" 1 "HVAC_ACTUATOR_BRUSHED_STATE_POSITIVE_RUN" 0 "HVAC_ACTUATOR_BRUSHED_STATE_INIT" ;
VAL_ 656 VCLEFT_hvac2RLeftVerticalState 11 "HVAC_ACTUATOR_BRUSHED_STATE_RUNNING_OVERSHOOT" 10 "HVAC_ACTUATOR_BRUSHED_STATE_NEGATIVE_BACKOFF" 9 "HVAC_ACTUATOR_BRUSHED_STATE_POSITIVE_BACKOFF" 8 "HVAC_ACTUATOR_BRUSHED_STATE_CONTROL_DISABLED" 7 "HVAC_ACTUATOR_BRUSHED_STATE_FAULT" 6 "HVAC_ACTUATOR_BRUSHED_STATE_BRAKING" 5 "HVAC_ACTUATOR_BRUSHED_STATE_RUNNING" 4 "HVAC_ACTUATOR_BRUSHED_STATE_NEGATIVE_STALL" 3 "HVAC_ACTUATOR_BRUSHED_STATE_NEGATIVE_RUN" 2 "HVAC_ACTUATOR_BRUSHED_STATE_POSITIVE_STALL" 1 "HVAC_ACTUATOR_BRUSHED_STATE_POSITIVE_RUN" 0 "HVAC_ACTUATOR_BRUSHED_STATE_INIT" ;
VAL_ 656 VCLEFT_hvac2RRightLateralState 11 "HVAC_ACTUATOR_BRUSHED_STATE_RUNNING_OVERSHOOT" 10 "HVAC_ACTUATOR_BRUSHED_STATE_NEGATIVE_BACKOFF" 9 "HVAC_ACTUATOR_BRUSHED_STATE_POSITIVE_BACKOFF" 8 "HVAC_ACTUATOR_BRUSHED_STATE_CONTROL_DISABLED" 7 "HVAC_ACTUATOR_BRUSHED_STATE_FAULT" 6 "HVAC_ACTUATOR_BRUSHED_STATE_BRAKING" 5 "HVAC_ACTUATOR_BRUSHED_STATE_RUNNING" 4 "HVAC_ACTUATOR_BRUSHED_STATE_NEGATIVE_STALL" 3 "HVAC_ACTUATOR_BRUSHED_STATE_NEGATIVE_RUN" 2 "HVAC_ACTUATOR_BRUSHED_STATE_POSITIVE_STALL" 1 "HVAC_ACTUATOR_BRUSHED_STATE_POSITIVE_RUN" 0 "HVAC_ACTUATOR_BRUSHED_STATE_INIT" ;
VAL_ 656 VCLEFT_hvac2RRightVerticalState 11 "HVAC_ACTUATOR_BRUSHED_STATE_RUNNING_OVERSHOOT" 10 "HVAC_ACTUATOR_BRUSHED_STATE_NEGATIVE_BACKOFF" 9 "HVAC_ACTUATOR_BRUSHED_STATE_POSITIVE_BACKOFF" 8 "HVAC_ACTUATOR_BRUSHED_STATE_CONTROL_DISABLED" 7 "HVAC_ACTUATOR_BRUSHED_STATE_FAULT" 6 "HVAC_ACTUATOR_BRUSHED_STATE_BRAKING" 5 "HVAC_ACTUATOR_BRUSHED_STATE_RUNNING" 4 "HVAC_ACTUATOR_BRUSHED_STATE_NEGATIVE_STALL" 3 "HVAC_ACTUATOR_BRUSHED_STATE_NEGATIVE_RUN" 2 "HVAC_ACTUATOR_BRUSHED_STATE_POSITIVE_STALL" 1 "HVAC_ACTUATOR_BRUSHED_STATE_POSITIVE_RUN" 0 "HVAC_ACTUATOR_BRUSHED_STATE_INIT" ;
VAL_ 656 VCLEFT_vcusbLinSchedule 3 "VCUSB_LIN_SCHEDULE_COUNT" 2 "VCUSB_LIN_SCHEDULE_DIAGNOSTIC" 1 "VCUSB_LIN_SCHEDULE_COMMAND_AND_RESPONSE" 0 "VCUSB_LIN_SCHEDULE_OFF" ;
VAL_ 657 VCLEFT_thermalLogging1HzIndex 15 "MAX" 2 "END" 1 "ENDSTOP" 0 "ZEROSTOP" ;
VAL_ 657 VCLEFT_hvacBlowerArbState 6 "ARBITRATOR_FAULTED" 5 "ARBITRATOR_COMPLETED" 4 "ARBITRATOR_REQUEST_CURRENT" 3 "ARBITRATOR_WAIT_BEFORE_REQUEST" 2 "ARBITRATOR_HIGH_FREQ_VOLT_INJECTION" 1 "ARBITRATOR_READY" 0 "ARBITRATOR_NOT_READY" ;
VAL_ 657 VCLEFT_hvacBlowerArbResult 2 "VC_MOTOR_ID_BOSCH" 1 "VC_MOTOR_ID_DELTA" 0 "VC_MOTOR_ID_UNKNOWN" ;
VAL_ 549 VCRIGHT_ptcLVState 3 "LV_FAULT" 2 "LV_GOING_DOWN" 1 "LV_ON" 0 "LV_OFF" ;
VAL_ 549 VCRIGHT_ocsLVState 3 "LV_FAULT" 2 "LV_GOING_DOWN" 1 "LV_ON" 0 "LV_OFF" ;
VAL_ 549 VCRIGHT_premAudioLVState 3 "LV_FAULT" 2 "LV_GOING_DOWN" 1 "LV_ON" 0 "LV_OFF" ;
VAL_ 549 VCRIGHT_rearOilPumpLVState 3 "LV_FAULT" 2 "LV_GOING_DOWN" 1 "LV_ON" 0 "LV_OFF" ;
VAL_ 549 VCRIGHT_tunerLVState 3 "LV_FAULT" 2 "LV_GOING_DOWN" 1 "LV_ON" 0 "LV_OFF" ;
VAL_ 549 VCRIGHT_hvcLVState 3 "LV_FAULT" 2 "LV_GOING_DOWN" 1 "LV_ON" 0 "LV_OFF" ;
VAL_ 549 VCRIGHT_rcmLVState 3 "LV_FAULT" 2 "LV_GOING_DOWN" 1 "LV_ON" 0 "LV_OFF" ;
VAL_ 549 VCRIGHT_lumbarLVState 3 "LV_FAULT" 2 "LV_GOING_DOWN" 1 "LV_ON" 0 "LV_OFF" ;
VAL_ 549 VCRIGHT_eFuseLockoutStatus 2 "EFUSE_LOCKOUT_STATUS_ACTIVE" 1 "EFUSE_LOCKOUT_STATUS_PENDING" 0 "EFUSE_LOCKOUT_STATUS_IDLE" ;
VAL_ 549 VCRIGHT_vehiclePowerStateDBG 3 "VEHICLE_POWER_STATE_DRIVE" 2 "VEHICLE_POWER_STATE_ACCESSORY" 1 "VEHICLE_POWER_STATE_CONDITIONING" 0 "VEHICLE_POWER_STATE_OFF" ;
VAL_ 549 VCRIGHT_parkLVState 3 "LV_FAULT" 2 "LV_GOING_DOWN" 1 "LV_ON" 0 "LV_OFF" ;
VAL_ 549 VCRIGHT_icrLVState 3 "LV_FAULT" 2 "LV_GOING_DOWN" 1 "LV_ON" 0 "LV_OFF" ;
VAL_ 549 VCRIGHT_interiorCameraLedLVState 3 "LV_FAULT" 2 "LV_GOING_DOWN" 1 "LV_ON" 0 "LV_OFF" ;
VAL_ 549 VCRIGHT_diLVState 3 "LV_FAULT" 2 "LV_GOING_DOWN" 1 "LV_ON" 0 "LV_OFF" ;
VAL_ 1795 VCRIGHT_debugThermal10HzIndex 10 "END" 9 "HVAC_ACTUATOR_TUNNING" 8 "HVAC_PTC_COI_DEV4" 7 "HVAC_PTC_COI_DEV3" 6 "HVAC_PTC_COI_DEV2" 5 "HVAC_PTC_COI_DEV1" 4 "actuatorStatus" 3 "cabinModel" 2 "airflow" 1 "temps" 0 "heaterAndEvapWatts" ;
VAL_ 1795 VCRIGHT_setTempAdjustmentLeft 127 "SNA" ;
VAL_ 1795 VCRIGHT_setTempAdjustmentRight 127 "SNA" ;
VAL_ 1795 VCRIGHT_PTCcenterPowerLeft 63 "SNA" ;
VAL_ 1795 VCRIGHT_PTCouterPowerLeft 63 "SNA" ;
VAL_ 1795 VCRIGHT_PTCinnerPowerLeft 63 "SNA" ;
VAL_ 1795 VCRIGHT_PTCcenterPowerRight 63 "SNA" ;
VAL_ 1795 VCRIGHT_PTCouterPowerRight 63 "SNA" ;
VAL_ 1795 VCRIGHT_PTCinnerPowerRight 63 "SNA" ;
VAL_ 1795 VCRIGHT_PTCcenterStoneTempLeft 255 "SNA" ;
VAL_ 1795 VCRIGHT_PTCcenterStoneTempRight 255 "SNA" ;
VAL_ 1795 VCRIGHT_PTCinnerStoneTempLeft 255 "SNA" ;
VAL_ 1795 VCRIGHT_PTCinnerStoneTempRight 255 "SNA" ;
VAL_ 1795 VCRIGHT_PTCouterStoneTempLeft 255 "SNA" ;
VAL_ 1795 VCRIGHT_PTCouterRodTempLeft 255 "SNA" ;
VAL_ 1795 VCRIGHT_PTCouterAirTempLeft 255 "SNA" ;
VAL_ 1795 VCRIGHT_PTCcenterRodTempLeft 255 "SNA" ;
VAL_ 1795 VCRIGHT_PTCinnerRodTempLeft 255 "SNA" ;
VAL_ 1795 VCRIGHT_PTCcenterAirTempLeft 255 "SNA" ;
VAL_ 1795 VCRIGHT_PTCinnerAirTempLeft 255 "SNA" ;
VAL_ 1795 VCRIGHT_PTCouterStoneTempRight 255 "SNA" ;
VAL_ 1795 VCRIGHT_PTCouterRodTempRight 255 "SNA" ;
VAL_ 1795 VCRIGHT_PTCouterAirTempRight 255 "SNA" ;
VAL_ 1795 VCRIGHT_PTCcenterRodTempRight 255 "SNA" ;
VAL_ 1795 VCRIGHT_PTCinnerRodTempRight 255 "SNA" ;
VAL_ 1795 VCRIGHT_PTCcenterAirTempRight 255 "SNA" ;
VAL_ 1795 VCRIGHT_PTCinnerAirTempRight 255 "SNA" ;
VAL_ 259 VCRIGHT_doorClosureStatusFront 8 "CLOSURE_STATUS_FAULT" 2 "CLOSURE_STATUS_CLOSED" 1 "CLOSURE_STATUS_OPEN" 0 "CLOSURE_STATUS_SNA" ;
VAL_ 259 VCRIGHT_doorClosureStatusRear 8 "CLOSURE_STATUS_FAULT" 2 "CLOSURE_STATUS_CLOSED" 1 "CLOSURE_STATUS_OPEN" 0 "CLOSURE_STATUS_SNA" ;
VAL_ 259 VCRIGHT_frontLatchStatus 8 "LATCH_FAULT" 7 "LATCH_DEFAULT" 6 "LATCH_TIMEOUT" 5 "LATCH_AJAR" 4 "LATCH_OPENING" 3 "LATCH_CLOSING" 2 "LATCH_CLOSED" 1 "LATCH_OPENED" 0 "LATCH_SNA" ;
VAL_ 259 VCRIGHT_rearLatchStatus 8 "LATCH_FAULT" 7 "LATCH_DEFAULT" 6 "LATCH_TIMEOUT" 5 "LATCH_AJAR" 4 "LATCH_OPENING" 3 "LATCH_CLOSING" 2 "LATCH_CLOSED" 1 "LATCH_OPENED" 0 "LATCH_SNA" ;
VAL_ 259 VCRIGHT_lastDoorReqSourceFront 4 "DOOR_REQUEST_SOURCE_ECU" 3 "DOOR_REQUEST_SOURCE_VCSEC" 2 "DOOR_REQUEST_SOURCE_EXTERIOR_HANDLE" 1 "DOOR_REQUEST_SOURCE_INTERIOR_BUTTON" 0 "DOOR_REQUEST_SOURCE_UNKNOWN" ;
VAL_ 259 VCRIGHT_lastDoorReqSourceRear 4 "DOOR_REQUEST_SOURCE_ECU" 3 "DOOR_REQUEST_SOURCE_VCSEC" 2 "DOOR_REQUEST_SOURCE_EXTERIOR_HANDLE" 1 "DOOR_REQUEST_SOURCE_INTERIOR_BUTTON" 0 "DOOR_REQUEST_SOURCE_UNKNOWN" ;
VAL_ 259 VCRIGHT_mirrorState 5 "MIRROR_STATE_CALIBRATION" 4 "MIRROR_STATE_RECALL" 3 "MIRROR_STATE_FOLD_UNFOLD" 2 "MIRROR_STATE_TILT_Y" 1 "MIRROR_STATE_TILT_X" 0 "MIRROR_STATE_IDLE" ;
VAL_ 259 VCRIGHT_mirrorFoldState 4 "MIRROR_FOLD_STATE_UNFOLDING" 3 "MIRROR_FOLD_STATE_FOLDING" 2 "MIRROR_FOLD_STATE_UNFOLDED" 1 "MIRROR_FOLD_STATE_FOLDED" 0 "MIRROR_FOLD_STATE_UNKNOWN" ;
VAL_ 259 VCRIGHT_trunkLatchStatus 8 "LATCH_FAULT" 7 "LATCH_DEFAULT" 6 "LATCH_TIMEOUT" 5 "LATCH_AJAR" 4 "LATCH_OPENING" 3 "LATCH_CLOSING" 2 "LATCH_CLOSED" 1 "LATCH_OPENED" 0 "LATCH_SNA" ;
VAL_ 259 VCRIGHT_mirrorRecallState 5 "MIRROR_RECALL_STATE_RECALLING_STOPPED" 4 "MIRROR_RECALL_STATE_RECALLING_FAILED" 3 "MIRROR_RECALL_STATE_RECALLING_COMPLETE" 2 "MIRROR_RECALL_STATE_RECALLING_AXIS_2" 1 "MIRROR_RECALL_STATE_RECALLING_AXIS_1" 0 "MIRROR_RECALL_STATE_INIT" ;
VAL_ 915 VCRIGHT_epbmDebugIndex 1 "TRANSITIONS" 0 "STATES" ;
VAL_ 915 VCRIGHT_epbmCaliperState 6 "EPB_SAVED_CALIPERSTATE_WINCHMODE" 5 "EPB_SAVED_CALIPERSTATE_SERVICE" 4 "EPB_SAVED_CALIPERSTATE_OPEN" 3 "EPB_SAVED_CALIPERSTATE_PARK" 2 "EPB_SAVED_CALIPERSTATE_REAPPLY" 1 "EPB_SAVED_CALIPERSTATE_UNKNOWN" 0 "EPB_SAVED_CALIPERSTATE_UNSAVED" ;
VAL_ 915 VCRIGHT_summonFaultReason 30 "EPB_SUMMONFAULT_MONITOR_TYPE_UNKNOWN" 29 "EPB_SUMMONFAULT_AP_MONITOR" 28 "EPB_SUMMONFAULT_REMOTE_DID_NOT_START" 27 "EPB_SUMMONFAULT_INVALID_REMOTE_STATE" 26 "EPB_SUMMONFAULT_START_IN_UNAVAILABLE" 25 "EPB_SUMMONFAULT_REMOTE_UNIT_FAULTED" 24 "EPB_SUMMONFAULT_LOCAL_UNIT_FAULTED" 23 "EPB_SUMMONFAULT_REMOTE_SUMMON_FAULTED" 22 "EPB_SUMMONFAULT_EPBREMOTE_MIA" 21 "EPB_SUMMONFAULT_PASSIVE_REQUEST" 20 "EPB_SUMMONFAULT_DI_STATE_INVALID" 19 "EPB_SUMMONFAULT_EPB_FAULT" 18 "EPB_SUMMONFAULT_MISMATCH" 17 "EPB_SUMMONFAULT_OOC" 16 "EPB_SUMMONFAULT_PM_REQUEST" 15 "EPB_SUMMONFAULT_PM_MIA" 14 "EPB_SUMMONFAULT_PARK_MIA" 13 "EPB_SUMMONFAULT_EXTERNAL" 12 "EPB_SUMMONFAULT_SPEED" 11 "EPB_SUMMONFAULT_EPBM_REQUEST" 10 "EPB_SUMMONFAULT_EAC_NOT_ALLOWED" 9 "EPB_SUMMONFAULT_VEH_CAN_FAULT" 8 "EPB_SUMMONFAULT_ESP_FAULT" 7 "EPB_SUMMONFAULT_DAS_FAULT" 6 "EPB_SUMMONFAULT_DI_APC_FAULT" 5 "EPB_SUMMONFAULT_DI_FAULT" 4 "EPB_SUMMONFAULT_EPBM_MIA" 3 "EPB_SUMMONFAULT_ESP_MIA" 2 "EPB_SUMMONFAULT_DAS_MIA" 1 "EPB_SUMMONFAULT_DI_MIA" 0 "EPB_SUMMONFAULT_NONE" ;
VAL_ 915 VCRIGHT_epbSummonState 6 "EPB_SUMMON_UNAVAILABLE" 5 "EPB_SUMMON_FAULT" 4 "EPB_SUMMON_COMPLETE" 3 "EPB_SUMMON_ACTIVE" 2 "EPB_SUMMON_ARMED" 1 "EPB_SUMMON_IDLE" 0 "EPB_SUMMON_INIT" ;
VAL_ 915 VCRIGHT_epbmSummonState 6 "EPB_SUMMON_UNAVAILABLE" 5 "EPB_SUMMON_FAULT" 4 "EPB_SUMMON_COMPLETE" 3 "EPB_SUMMON_ACTIVE" 2 "EPB_SUMMON_ARMED" 1 "EPB_SUMMON_IDLE" 0 "EPB_SUMMON_INIT" ;
VAL_ 915 VCRIGHT_epbUnitStatus 23 "EPB_STATUS_COUNT" 22 "EPB_STATUS_AUTONOMY_OPEN" 21 "EPB_STATUS_FREE_ROLL_MODE" 20 "EPB_STATUS_DYNAMIC_PARKING" 19 "EPB_STATUS_EXTERNAL_PARKING" 18 "EPB_STATUS_RELEASING_FOR_EXTERNAL_PARK" 17 "EPB_STATUS_EXTERNAL_DYNAMIC" 16 "EPB_STATUS_SUMMON_PARKING" 15 "EPB_STATUS_SUMMON_RELEASING" 14 "EPB_STATUS_SUMMON" 13 "EPB_STATUS_WINCHMODE_PENDING" 12 "EPB_STATUS_PARK_PENDING" 11 "EPB_STATUS_SERVICE_RELEASING" 10 "EPB_STATUS_RELEASING" 9 "EPB_STATUS_DYNAMIC_APPLYING" 8 "EPB_STATUS_PARKING" 7 "EPB_STATUS_WINCHMODE_RELEASING" 6 "EPB_STATUS_WINCHMODE" 5 "EPB_STATUS_SERVICE" 4 "EPB_STATUS_START" 3 "EPB_STATUS_PARK" 2 "EPB_STATUS_DYNAMIC" 1 "EPB_STATUS_OPEN" 0 "EPB_STATUS_UNKNOWN" ;
VAL_ 915 VCRIGHT_epbmFaultStatus 3 "EPB_STATUS_FAULT_IDLE" 2 "EPB_STATUS_FAULT" 1 "EPB_STATUS_RETRY" 0 "EPB_STATUS_NOMINAL" ;
VAL_ 915 VCRIGHT_epbFaultStatus 3 "EPB_STATUS_FAULT_IDLE" 2 "EPB_STATUS_FAULT" 1 "EPB_STATUS_RETRY" 0 "EPB_STATUS_NOMINAL" ;
VAL_ 915 VCRIGHT_epbmSystemStatus 8 "EPB_VEHICLE_STATUS_MISMATCH" 7 "EPB_VEHICLE_STATUS_FAULT_SECURE" 6 "EPB_VEHICLE_STATUS_FAULT" 5 "EPB_VEHICLE_STATUS_RELEASING" 4 "EPB_VEHICLE_STATUS_PARKING" 3 "EPB_VEHICLE_STATUS_DYNAMIC" 2 "EPB_VEHICLE_STATUS_PARKED" 1 "EPB_VEHICLE_STATUS_RELEASED" 0 "EPB_VEHICLE_STATUS_UNKNOWN" ;
VAL_ 1123 VCRIGHT_cdpRequestState 1 "EPB_CDP_REQUEST_VALID" 0 "EPB_CDP_REQUEST_INVALID" ;
VAL_ 1123 VCRIGHT_epbmSystemStatusQF 1 "EPBM_SYSTEM_STATUS_INVALID" 0 "EPBM_SYSTEM_STATUS_VALID" ;
VAL_ 1123 VCRIGHT_epbmUnitStatus 23 "EPB_STATUS_COUNT" 22 "EPB_STATUS_AUTONOMY_OPEN" 21 "EPB_STATUS_FREE_ROLL_MODE" 20 "EPB_STATUS_DYNAMIC_PARKING" 19 "EPB_STATUS_EXTERNAL_PARKING" 18 "EPB_STATUS_RELEASING_FOR_EXTERNAL_PARK" 17 "EPB_STATUS_EXTERNAL_DYNAMIC" 16 "EPB_STATUS_SUMMON_PARKING" 15 "EPB_STATUS_SUMMON_RELEASING" 14 "EPB_STATUS_SUMMON" 13 "EPB_STATUS_WINCHMODE_PENDING" 12 "EPB_STATUS_PARK_PENDING" 11 "EPB_STATUS_SERVICE_RELEASING" 10 "EPB_STATUS_RELEASING" 9 "EPB_STATUS_DYNAMIC_APPLYING" 8 "EPB_STATUS_PARKING" 7 "EPB_STATUS_WINCHMODE_RELEASING" 6 "EPB_STATUS_WINCHMODE" 5 "EPB_STATUS_SERVICE" 4 "EPB_STATUS_START" 3 "EPB_STATUS_PARK" 2 "EPB_STATUS_DYNAMIC" 1 "EPB_STATUS_OPEN" 0 "EPB_STATUS_UNKNOWN" ;
VAL_ 1123 VCRIGHT_epbmCdpState 2 "EPB_CDP_STATE_FAULT" 1 "EPB_CDP_STATE_VALID" 0 "EPB_CDP_STATE_UNKNOWN" ;
VAL_ 579 VCRIGHT_hvacStatusIndex 5 "MISC3" 4 "MISC2" 3 "MISC" 2 "VCFRONT2" 1 "VCFRONT" 0 "UI" ;
VAL_ 579 VCRIGHT_childModeHVACState 2 "ACTIVE_COMPROMISED" 1 "ACTIVE" 0 "IDLE" ;
VAL_ 579 VCRIGHT_dogModeState 15 "DOG_MODE_INVALID" 6 "DOG_MODE_RUNNING_TEMP_MONITOR_TRIP" 5 "DOG_MODE_RUNNING_DEVICE_OR_MODEL_FAULT" 4 "DOG_MODE_RUNNING" 3 "DOG_MODE_AVAILABLE" 2 "DOG_MODE_INITIALIZING" 1 "DOG_MODE_UNAVAILABLE_CABIN_TOO_HOT" 0 "DOG_MODE_UNAVAILABLE_MODEL_DEVICE_FAULT" ;
VAL_ 579 VCRIGHT_COPNotRunningReasonFilte 7 "CABIN_BELOW_THRESHOLD" 6 "WAITING" 5 "LOW_SOLAR_LOAD" 4 "TIMEOUT" 3 "ENERGY_CONSUMPTION_LIMIT" 2 "USER_INTERACTION" 1 "DISABLED" 0 "NONE" ;
VAL_ 579 VCRIGHT_hvacAirDistributionMode 7 "DEFROST_PANEL_FLOOR" 6 "DEFROST_PANEL" 5 "DEFROST_FLOOR" 4 "DEFROST" 3 "PANEL_FLOOR" 2 "PANEL" 1 "FLOOR" 0 "NONE" ;
VAL_ 579 VCRIGHT_hvacBlowerSegment 11 "11" 10 "10" 9 "9" 8 "8" 7 "7" 6 "6" 5 "5" 4 "4" 3 "3" 2 "2" 1 "1" 0 "OFF" ;
VAL_ 579 VCRIGHT_hvacRecirc 2 "FRESH" 1 "RECIRC" 0 "AUTO" ;
VAL_ 579 VCRIGHT_hvacACRunning 1 "ON" 0 "OFF" ;
VAL_ 579 VCRIGHT_hvacPowerState 4 "OVERHEAT_PROTECT" 3 "OVERHEAT_PROTECT_FANONLY" 2 "PRECONDITION" 1 "ON" 0 "OFF" ;
VAL_ 579 VCRIGHT_hvacVentStatus 3 "OFF" 2 "RIGHT" 1 "LEFT" 0 "BOTH" ;
VAL_ 579 VCRIGHT_hvacSecondRowState 4 "HIGH" 3 "MED" 2 "LOW" 1 "OFF" 0 "AUTO" ;
VAL_ 579 VCRIGHT_hvacModelInitStatus 9 "NOT_INIT_CAMERA_POCKET_BEING_INITIALIZED" 8 "INIT_FORWARD_CALC_LIMP" 7 "INIT_FROM_SENSORS_PREDICTION_ERROR_LIMP" 6 "INIT_FROM_SENSORS_LIMP" 5 "INIT_WAITING_FOR_SENSORS" 4 "INIT_FORWARD_CALC" 3 "INIT_FROM_SENSORS_PREDICTION_ERROR" 2 "INIT_FROM_SENSORS" 1 "NOT_INIT_WAIT_FOR_GTW" 0 "NOT_INIT_WAIT_FOR_SENSORS" ;
VAL_ 579 VCRIGHT_tempDuctLeft 255 "SNA" ;
VAL_ 579 VCRIGHT_tempDuctRight 255 "SNA" ;
VAL_ 579 VCRIGHT_hvacDuctTargetLeft 255 "SNA" ;
VAL_ 579 VCRIGHT_hvacDuctTargetRight 255 "SNA" ;
VAL_ 579 VCRIGHT_tempDuctRightUpper 255 "SNA" ;
VAL_ 579 VCRIGHT_hvacEvapInletTempEstimat 1023 "SNA" ;
VAL_ 579 VCRIGHT_hvacAirflowReason 21 "NONE" 20 "ODOR_ROUTINE" 19 "DRIVERLESS_SELF_TEST" 18 "VOC_PURGE" 17 "STRATIFICATION_TOP_PAD_AREA" 16 "HOT_DUCT_LOCKOUT" 15 "COLD_DUCT_LOCKOUT" 14 "BIOWEAPON_DEFENSE" 13 "EVAP_OIL_PURGE" 12 "EVAP_DRYING" 11 "SCREEN_PROTECTION" 10 "CABIN_OVERHEAT_PROTECT" 9 "CABIN_PURGE" 8 "OUTLET_TEMP_LIMIT" 7 "OCCUPANT_CONVECTION_REQUIREMENT" 6 "STRATIFICATION_INTERIOR_SURFACES" 5 "STRATIFICATION_GLASS_ROOF" 4 "MINIMUM_AUTO_AIRFLOW" 3 "CABIN_TEMPERATURE_CONTROL" 2 "UI_SHORTCUT" 1 "MANUAL_FAN_SPEED" 0 "HVAC_OFF" ;
VAL_ 579 VCRIGHT_solarLoadOnVehicle 255 "SNA" ;
VAL_ 579 VCRIGHT_hvacFrontRightSeatFanSta 3 "FAN_REQUEST_LEVEL3" 2 "FAN_REQUEST_LEVEL2" 1 "FAN_REQUEST_LEVEL1" 0 "FAN_REQUEST_OFF" ;
VAL_ 579 VCRIGHT_hvacFrontLeftSeatFanStat 3 "FAN_REQUEST_LEVEL3" 2 "FAN_REQUEST_LEVEL2" 1 "FAN_REQUEST_LEVEL1" 0 "FAN_REQUEST_OFF" ;
VAL_ 579 VCRIGHT_hvacFrontRightSeatHeatSt 3 "HEATER_REQUEST_LEVEL3" 2 "HEATER_REQUEST_LEVEL2" 1 "HEATER_REQUEST_LEVEL1" 0 "HEATER_REQUEST_OFF" ;
VAL_ 579 VCRIGHT_hvacSeatFrontLeftTempTar 0 "OFF" ;
VAL_ 579 VCRIGHT_hvacManualToAutoNotify 6 "MISC3" 5 "MISC2" 4 "COMFORT_FORWARD_LOOK" 3 "FOGGING_COMFORT" 2 "FOGGING" 1 "COMFORT" 0 "OFF" ;
VAL_ 579 VCRIGHT_hvacRequestsFullAuto 7 "MISC4" 6 "MISC3" 5 "MISC2" 4 "MISC1" 3 "HVAC_OFF_FOGGING_RISK" 2 "MANUAL_HVAC_HIGH_FOGGING_RISK" 1 "HIGH_BLOWER_SPEED" 0 "NOT_ALLOWED" ;
VAL_ 579 VCRIGHT_steeringWheelHeatStatus 3 "STEERING_WHEEL_HEAT_LEVEL3" 2 "STEERING_WHEEL_HEAT_LEVEL2" 1 "STEERING_WHEEL_HEAT_LEVEL1" 0 "STEERING_WHEEL_HEAT_OFF" ;
VAL_ 579 VCRIGHT_autoDefogStatus 2 "INTERMEDIATE_DEFOG" 1 "DEFOG" 0 "NONE" ;
VAL_ 579 VCRIGHT_solarElevation -256 "SNA" ;
VAL_ 579 VCRIGHT_minsToSunrise 255 "SNA" ;
VAL_ 579 VCRIGHT_minsToSunset 255 "SNA" ;
VAL_ 579 VCRIGHT_hvacLimitedReasonRight 7 "HVAC_LIMITING_MANUAL_BLOWER" 6 "HVAC_LIMITING_CDL_AND_QDLH" 5 "HVAC_LIMITING_HDL_AND_QDLC" 4 "HVAC_LIMITING_QDOT_LIMITED_HEATING" 3 "HVAC_LIMITING_QDOT_LIMITED_COOLING" 2 "HVAC_LIMITING_COLD_DUCT_LOCKOUT" 1 "HVAC_LIMITING_HOT_DUCT_LOCKOUT" 0 "HVAC_LIMITING_NONE" ;
VAL_ 579 VCRIGHT_hvacLimitedReasonLeft 7 "HVAC_LIMITING_MANUAL_BLOWER" 6 "HVAC_LIMITING_CDL_AND_QDLH" 5 "HVAC_LIMITING_HDL_AND_QDLC" 4 "HVAC_LIMITING_QDOT_LIMITED_HEATING" 3 "HVAC_LIMITING_QDOT_LIMITED_COOLING" 2 "HVAC_LIMITING_COLD_DUCT_LOCKOUT" 1 "HVAC_LIMITING_HOT_DUCT_LOCKOUT" 0 "HVAC_LIMITING_NONE" ;
VAL_ 579 VCRIGHT_tempDuctLeftUpper 255 "SNA" ;
VAL_ 579 VCRIGHT_hvacFrontLeftSeatHeatSta 3 "HEATER_REQUEST_LEVEL3" 2 "HEATER_REQUEST_LEVEL2" 1 "HEATER_REQUEST_LEVEL1" 0 "HEATER_REQUEST_OFF" ;
VAL_ 579 VCRIGHT_tempDuctLeftLower 255 "SNA" ;
VAL_ 579 VCRIGHT_tempDuctRightLower 255 "SNA" ;
VAL_ 774 VCRIGHT_infoIndex 255 "END" 41 "SUBCOMPONENT14" 40 "SUBCOMPONENT13" 39 "SUBCOMPONENT12" 38 "SUBCOMPONENT11" 37 "SUBCOMPONENT10" 36 "SUBCOMPONENT9" 35 "SUBCOMPONENT8" 34 "SUBCOMPONENT7" 33 "SUBCOMPONENT6" 32 "SUBCOMPONENT5" 31 "SUBCOMPONENT4" 24 "SUBCOMPONENT3" 23 "SUBCOMPONENT2" 20 "UDS_PROTOCOL_BOOTCRC" 19 "VERSION_DEPRECATED" 18 "BOOTLOADER_GITHASH" 17 "APP_GITHASH" 16 "SUBCOMPONENT1" 15 "BOOTLOADER_CRC" 14 "BOOTLOADER_SVN" 13 "APP_CRC" 11 "PCBAID_ASSYID_USAGEID" 10 "BUILD_HWID_COMPONENTID" 9 "DEPRECATED_9" 8 "DEPRECATED_8" 7 "DEPRECATED_7" 6 "DEPRECATED_6" 5 "DEPRECATED_5" 4 "DEPRECATED_4" 3 "DEPRECATED_3" 2 "DEPRECATED_2" 1 "DEPRECATED_1" 0 "DEPRECATED_0" ;
VAL_ 774 VCRIGHT_infoBuildType 4 "INFO_MFG_BUILD" 3 "INFO_TRACEABLE_CI_BUILD" 2 "INFO_LOCAL_BUILD" 1 "INFO_PLATFORM_BUILD" 0 "INFO_UNKNOWN_BUILD" ;
VAL_ 774 VCRIGHT_infoAssemblyId 255 "ASSEMBLY_SNA" 1 "ASSEMBLY1" ;
VAL_ 1803 VCRIGHT_logging0point1HzIndex 8 "END" 7 "HVAC_3" 6 "HVAC_2" 5 "LIGHT_CURRENTS_2" 4 "HVAC_ACTUATOR_ZEROSTOP" 3 "HVAC_ACTUATOR_ENDSTOP" 2 "HVAC" 1 "LIGHT_CURRENTS_1" 0 "LIGHT_CURRENTS_0" ;
VAL_ 1803 VCRIGHT_leftPTCCompromisedRod 7 "CENTER_INNER" 6 "OUTER_CENTER" 5 "OUTER_INNER" 4 "OUTER" 3 "CENTER" 2 "INNER" 1 "ALL" 0 "NONE" ;
VAL_ 1803 VCRIGHT_rightPTCCompromisedRod 7 "CENTER_INNER" 6 "OUTER_CENTER" 5 "OUTER_INNER" 4 "OUTER" 3 "CENTER" 2 "INNER" 1 "ALL" 0 "NONE" ;
VAL_ 1803 VCRIGHT_cabinTempBreathLevelFOff 255 "SNA" ;
VAL_ 1803 VCRIGHT_ambientTempLimp 255 "SNA" ;
VAL_ 1803 VCRIGHT_cabinProbeTempLimp 255 "SNA" ;
VAL_ 1803 VCRIGHT_thsTempLimp 255 "SNA" ;
VAL_ 1803 VCRIGHT_thsSolarIrradianceLimp 255 "SNA" ;
VAL_ 611 VCRIGHT_logging10HzIndex 5 "END" 4 "HVAC_ACTUATOR_BRUSHED_DUTY" 3 "HVAC_ACTUATOR_BRUSHED" 2 "HVAC_ACTUATOR_STATE" 1 "HVAC_ACTUATOR_POSITIONS" 0 "HVAC_ACTUATOR_TARGETS" ;
VAL_ 611 VCRIGHT_hvacLHBleedActuatorState 2 "HVACACTUATOR_STATE_COASTING" 1 "HVACACTUATOR_STATE_RUNNING" 0 "HVACACTUATOR_STATE_BRAKING" ;
VAL_ 611 VCRIGHT_hvacRHBleedActuatorState 2 "HVACACTUATOR_STATE_COASTING" 1 "HVACACTUATOR_STATE_RUNNING" 0 "HVACACTUATOR_STATE_BRAKING" ;
VAL_ 611 VCRIGHT_hvacLHVaneActuatorState 2 "HVACACTUATOR_STATE_COASTING" 1 "HVACACTUATOR_STATE_RUNNING" 0 "HVACACTUATOR_STATE_BRAKING" ;
VAL_ 611 VCRIGHT_hvacRHVaneActuatorState 2 "HVACACTUATOR_STATE_COASTING" 1 "HVACACTUATOR_STATE_RUNNING" 0 "HVACACTUATOR_STATE_BRAKING" ;
VAL_ 611 VCRIGHT_hvacUpperModeActState 2 "HVACACTUATOR_STATE_COASTING" 1 "HVACACTUATOR_STATE_RUNNING" 0 "HVACACTUATOR_STATE_BRAKING" ;
VAL_ 611 VCRIGHT_hvacLowerModeActState 2 "HVACACTUATOR_STATE_COASTING" 1 "HVACACTUATOR_STATE_RUNNING" 0 "HVACACTUATOR_STATE_BRAKING" ;
VAL_ 611 VCRIGHT_hvacIntakeActuatorState 2 "HVACACTUATOR_STATE_COASTING" 1 "HVACACTUATOR_STATE_RUNNING" 0 "HVACACTUATOR_STATE_BRAKING" ;
VAL_ 611 VCRIGHT_tempDatLeftEst 255 "SNA" ;
VAL_ 611 VCRIGHT_tempDatRightEst 255 "SNA" ;
VAL_ 611 VCRIGHT_tempDuctLeftEst 255 "SNA" ;
VAL_ 611 VCRIGHT_tempDuctRightEst 255 "SNA" ;
VAL_ 611 VCRIGHT_ptcHeaterBadRodDetection 11 "UNAVAILABLE" 10 "CLEAR_FAULT_RESTART" 9 "CLEAR_FAULT" 8 "CHECK_RIGHT_INNER" 7 "CHECK_RIGHT_CENTER" 6 "CHECK_RIGHT_OUTER" 5 "CHECK_LEFT_INNER" 4 "CHECK_LEFT_CENTER" 3 "CHECK_LEFT_OUTER" 2 "DETECTED" 1 "IDLE" 0 "INIT" ;
VAL_ 611 VCRIGHT_frontLeftSeatTempTargetQ 0 "OFF" ;
VAL_ 611 VCRIGHT_frontRightSeatTempTarget 0 "OFF" ;
